VERSION ""
BS_:
BU_:

BO_ 795 BCS2L_warningMatrix2: 8 ETH
 SG_ BCS2L_w065_latchMotorLSD: 0|1@1+ (1,0) [0|0] "" X
 SG_ BCS2L_w066_latchMotorOverCurr: 1|1@1+ (1,0) [0|0] "" X
 SG_ BCS2L_w067_latchMotorUnderCurr: 2|1@1+ (1,0) [0|0] "" X
 SG_ BCS2L_w068_latchMicroswitchError: 3|1@1+ (1,0) [0|0] "" X
 SG_ BCS2L_w070_2ROccupiedUnbuckled: 5|1@1+ (1,0) [0|0] "" X
 SG_ BCS2L_w071_3ROccupiedUnbuckled: 6|1@1+ (1,0) [0|0] "" X
 SG_ BCS2L_w072_2RObstacleDetected: 7|1@1+ (1,0) [0|0] "" X
 SG_ BCS2L_w073_occupiedUnsecured: 8|1@1+ (1,0) [0|0] "" X
 SG_ BCS2L_w074_2RowTrackObstacle: 9|1@1+ (1,0) [0|0] "" X
 SG_ BCS2L_w075_2RowPitchObstacle: 10|1@1+ (1,0) [0|0] "" X
 SG_ BCS2L_w076_unexpectedStop: 11|1@1+ (1,0) [0|0] "" X
 SG_ BCS2L_w077_jammedSeat: 12|1@1+ (1,0) [0|0] "" X
 SG_ BCS2L_w079_DvrSideCfgMismatch: 14|1@1+ (1,0) [0|0] "" X
 SG_ BCS2L_w081_trackUncalibrated: 16|1@1+ (1,0) [0|0] "" X
 SG_ BCS2L_w082_pitchUncalibrated: 17|1@1+ (1,0) [0|0] "" X
 SG_ BCS2L_w085_comfortSwitchMisuse: 20|1@1+ (1,0) [0|0] "" X
 SG_ BCS2L_w086_easyEntrySwitchMisuse: 21|1@1+ (1,0) [0|0] "" X
 SG_ BCS2L_w087_foldFlatSwitchMisuse: 22|1@1+ (1,0) [0|0] "" X
 SG_ BCS2L_w090_CrashUnlockError: 25|1@1+ (1,0) [0|0] "" X
 SG_ BCS2L_w091_CrashStateMismatch: 26|1@1+ (1,0) [0|0] "" X
 SG_ BCS2L_w093_OTPError: 28|1@1+ (1,0) [0|0] "" X
 SG_ BCS2L_w094_FreescaleHSDFault: 29|1@1+ (1,0) [0|0] "" X
 SG_ BCS2L_w095_SeatUncalibrated1Row: 30|1@1+ (1,0) [0|0] "" X
 SG_ BCS2L_w096_HeadUncalibrated1Row: 31|1@1+ (1,0) [0|0] "" X
 SG_ BCS2L_w097_6040SeatUnlatched: 32|1@1+ (1,0) [0|0] "" X
 SG_ BCS2L_w098_6040TrackUndercurrent: 33|1@1+ (1,0) [0|0] "" X
 SG_ BCS2L_w100_chargePumpFail: 35|1@1+ (1,0) [0|0] "" X
 SG_ BCS2L_w101_VBATOutOfRange: 36|1@1+ (1,0) [0|0] "" X
 SG_ BCS2L_w102_8vRegulatorOutOfRange: 37|1@1+ (1,0) [0|0] "" X
 SG_ BCS2L_w103_regulatorShortedToGND: 38|1@1+ (1,0) [0|0] "" X
 SG_ BCS2L_w104_ECUOverCurrent: 39|1@1+ (1,0) [0|0] "" X
 SG_ BCS2L_w105_ECUDebugMode: 40|1@1+ (1,0) [0|0] "" X
 SG_ BCS2L_w106_HighCPULoad: 41|1@1+ (1,0) [0|0] "" X
 SG_ BCS2L_w107_HighStackUsage: 42|1@1+ (1,0) [0|0] "" X
 SG_ BCS2L_w108_2RHeatrTmpSnsInvalid: 43|1@1+ (1,0) [0|0] "" X
 SG_ BCS2L_w109_3RHeatrTmpSnsInvalid: 44|1@1+ (1,0) [0|0] "" X
 SG_ BCS2L_w110_2RSeatHeatSlowRise: 45|1@1+ (1,0) [0|0] "" X
 SG_ BCS2L_w111_3RLSeatHeatFault: 46|1@1+ (1,0) [0|0] "" X
 SG_ BCS2L_w112_3RSeatHeatSlowRise: 47|1@1+ (1,0) [0|0] "" X
 SG_ BCS2L_w114_seatHeatFault: 49|1@1+ (1,0) [0|0] "" X
 SG_ BCS2L_w115_2RHeatPadTempSensFLT: 50|1@1+ (1,0) [0|0] "" X
 SG_ BCS2L_w116_3RHeatPadTempSensFLT: 51|1@1+ (1,0) [0|0] "" X
 SG_ BCS2L_w117_2RHeatPadOvercurrent: 52|1@1+ (1,0) [0|0] "" X
 SG_ BCS2L_w118_3RHeatPadOvercurrent: 53|1@1+ (1,0) [0|0] "" X
 SG_ BCS2L_w119_2RCHeatPadOvercurrent: 54|1@1+ (1,0) [0|0] "" X
 SG_ BCS2L_w120_trackMotorDisconnect: 55|1@1+ (1,0) [0|0] "" X
 SG_ BCS2L_w121_pitchMotorDisconnect: 56|1@1+ (1,0) [0|0] "" X
 SG_ BCS2L_w122_trackSensorDisconnect: 57|1@1+ (1,0) [0|0] "" X
 SG_ BCS2L_w123_pitchSensorDisconnect: 58|1@1+ (1,0) [0|0] "" X
 SG_ BCS2L_w124_3RFFMotorDisconnect: 59|1@1+ (1,0) [0|0] "" X
 SG_ BCS2L_w125_3RHeadMotorDisconnect: 60|1@1+ (1,0) [0|0] "" X
 SG_ BCS2L_w126_comfortHoldDown: 61|1@1+ (1,0) [0|0] "" X
 SG_ BCS2L_w127_easyEntryHoldDown: 62|1@1+ (1,0) [0|0] "" X
 SG_ BCS2L_w128_foldFlatHoldDown: 63|1@1+ (1,0) [0|0] "" X

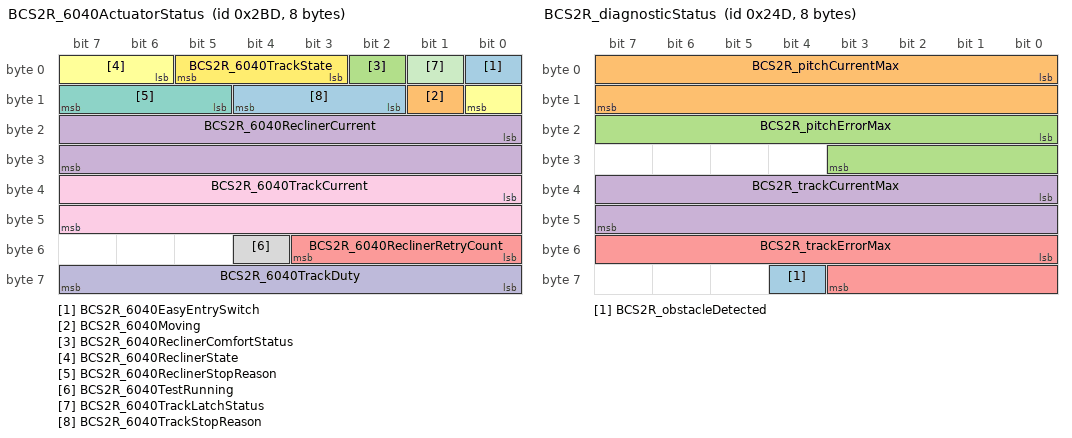
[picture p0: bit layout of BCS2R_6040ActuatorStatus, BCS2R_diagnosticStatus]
BO_ 701 BCS2R_6040ActuatorStatus: 8 ETH
 SG_ BCS2R_6040EasyEntrySwitch: 0|1@1+ (1,0) [0|0] "" X
 SG_ BCS2R_6040Moving: 9|1@1+ (1,0) [0|0] "" X
 SG_ BCS2R_6040ReclinerComfortStatus: 2|1@1+ (1,0) [0|0] "" X
 SG_ BCS2R_6040ReclinerCurrent: 16|16@1- (0.0030518,0) [0|0] "A" X
 SG_ BCS2R_6040ReclinerRetryCount: 48|4@1+ (1,0) [0|0] "" X
 SG_ BCS2R_6040ReclinerState: 6|3@1+ (1,0) [0|0] "" X
 SG_ BCS2R_6040ReclinerStopReason: 13|3@1+ (1,0) [0|0] "" X
 SG_ BCS2R_6040TestRunning: 52|1@1+ (1,0) [0|0] "" X
 SG_ BCS2R_6040TrackCurrent: 32|16@1- (0.0030518,0) [0|0] "A" X
 SG_ BCS2R_6040TrackDuty: 56|8@1- (1,0) [0|0] "%" X
 SG_ BCS2R_6040TrackLatchStatus: 1|1@1+ (1,0) [0|0] "" X
 SG_ BCS2R_6040TrackState: 3|3@1+ (1,0) [0|0] "" X
 SG_ BCS2R_6040TrackStopReason: 10|3@1+ (1,0) [0|0] "" X

BO_ 589 BCS2R_diagnosticStatus: 8 ETH
 SG_ BCS2R_obstacleDetected: 60|1@1+ (1,0) [0|0] "" X
 SG_ BCS2R_pitchCurrentMax: 0|16@1- (0.0030518,0) [0|0] "A" X
 SG_ BCS2R_pitchErrorMax: 16|12@1- (0.04884,0) [0|0] "%" X
 SG_ BCS2R_trackCurrentMax: 32|16@1- (0.0030518,0) [0|0] "A" X
 SG_ BCS2R_trackErrorMax: 48|12@1- (0.04884,0) [0|0] "%" X

BO_ 1309 BCS2R_info: 8 ETH
 SG_ BCS2R_infoIndex M: 0|8@1+ (1,0) [0|0] "" X
 SG_ BCS2R_infoBuildType m10: 8|8@1+ (1,0) [0|0] "" X
 SG_ BCS2R_infoBuildConfigID m10: 16|16@1+ (1,0) [0|0] "" X
 SG_ BCS2R_infoHardwareID m10: 32|16@1+ (1,0) [0|0] "" X
 SG_ BCS2R_infoComponentID m10: 48|16@1+ (1,0) [0|0] "" X
 SG_ BCS2R_infoPcbaID m11: 16|8@1+ (1,0) [0|0] "" X
 SG_ BCS2R_infoAssemblyID m11: 24|8@1+ (1,0) [0|0] "INTEGRAL" X
 SG_ BCS2R_infoUsageID m11: 32|16@1+ (1,0) [0|0] "" X
 SG_ BCS2R_infoSubUsageID m11: 48|16@1+ (1,0) [0|0] "" X
 SG_ BCS2R_infoApplicationCRC m13: 32|32@1+ (1,0) [0|0] "" X
 SG_ BCS2R_infoBootSvnRev m14: 8|24@1+ (1,0) [0|0] "" X
 SG_ BCS2R_infoAppGitHashBytes m17: 10|54@1+ (4,0) [0|0] "" X
 SG_ BCS2R_infoBootGitHashBytes m18: 10|54@1+ (4,0) [0|0] "" X
 SG_ BCS2R_infoPlatformType m19: 8|8@1+ (1,0) [0|0] "" X
 SG_ BCS2R_infoBootUdsProtoVersion m20: 8|8@1+ (1,0) [0|0] "" X
 SG_ BCS2R_infoBootloaderCRC m20: 32|32@1+ (1,0) [0|0] "" X

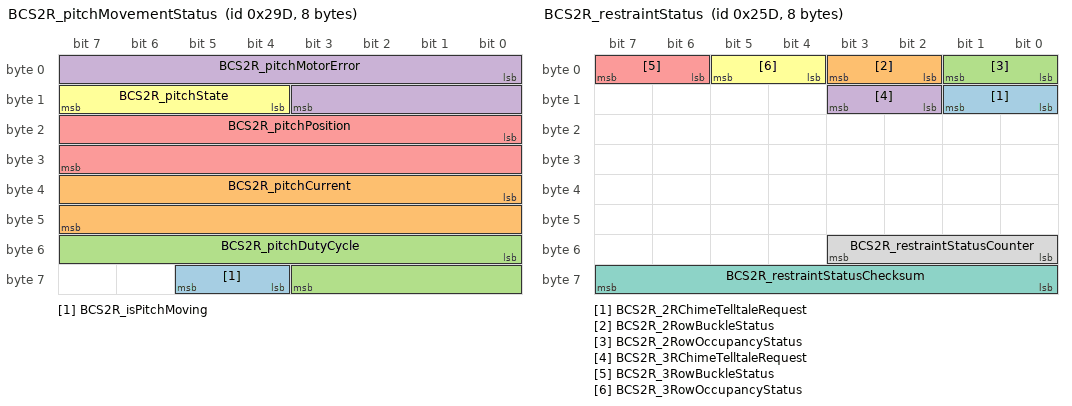
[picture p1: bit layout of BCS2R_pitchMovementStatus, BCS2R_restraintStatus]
BO_ 669 BCS2R_pitchMovementStatus: 8 ETH
 SG_ BCS2R_isPitchMoving: 60|2@1+ (1,0) [0|0] "" X
 SG_ BCS2R_pitchCurrent: 32|16@1- (0.0030518,0) [0|0] "A" X
 SG_ BCS2R_pitchDutyCycle: 48|12@1- (0.04884,0) [0|0] "%" X
 SG_ BCS2R_pitchMotorError: 0|12@1- (0.04884,0) [0|0] "%" X
 SG_ BCS2R_pitchPosition: 16|16@1- (1,0) [0|0] "INTEGRAL" X
 SG_ BCS2R_pitchState: 12|4@1+ (1,0) [0|0] "" X

BO_ 605 BCS2R_restraintStatus: 8 ETH
 SG_ BCS2R_2RChimeTelltaleRequest: 8|2@1+ (1,0) [0|0] "" X
 SG_ BCS2R_2RowBuckleStatus: 2|2@1+ (1,0) [0|0] "" X
 SG_ BCS2R_2RowOccupancyStatus: 0|2@1+ (1,0) [0|0] "" X
 SG_ BCS2R_3RChimeTelltaleRequest: 10|2@1+ (1,0) [0|0] "" X
 SG_ BCS2R_3RowBuckleStatus: 6|2@1+ (1,0) [0|0] "" X
 SG_ BCS2R_3RowOccupancyStatus: 4|2@1+ (1,0) [0|0] "" X
 SG_ BCS2R_restraintStatusChecksum: 56|8@1+ (1,0) [0|0] "" X
 SG_ BCS2R_restraintStatusCounter: 48|4@1+ (1,0) [0|0] "" X

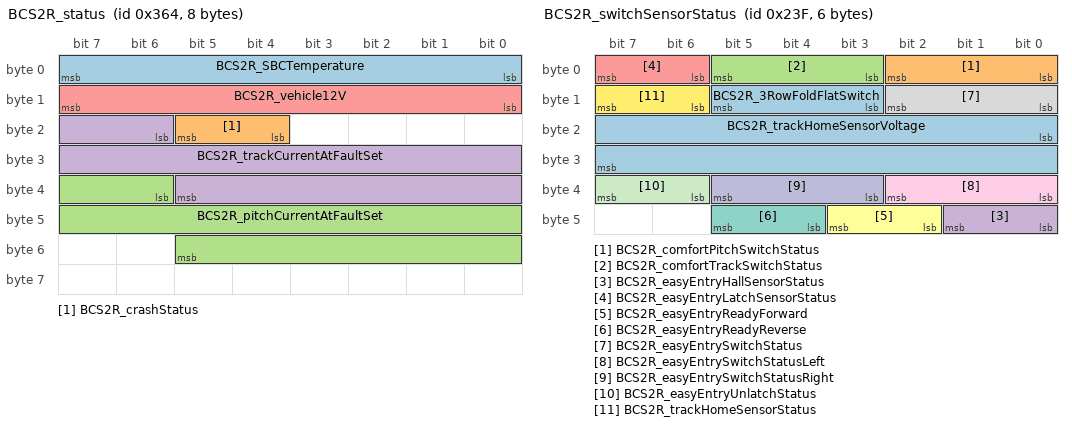
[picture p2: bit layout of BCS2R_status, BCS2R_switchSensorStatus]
BO_ 868 BCS2R_status: 8 ETH
 SG_ BCS2R_SBCTemperature: 0|8@1- (1,0) [0|0] "C" X
 SG_ BCS2R_crashStatus: 20|2@1+ (1,0) [0|0] "" X
 SG_ BCS2R_pitchCurrentAtFaultSet: 38|16@1- (0.0030518,0) [0|0] "A" X
 SG_ BCS2R_trackCurrentAtFaultSet: 22|16@1- (0.0030518,0) [0|0] "A" X
 SG_ BCS2R_vehicle12V: 8|8@1+ (0.1,0) [0|0] "V" X

BO_ 575 BCS2R_switchSensorStatus: 6 ETH
 SG_ BCS2R_3RowFoldFlatSwitch: 11|3@1+ (1,0) [0|0] "" X
 SG_ BCS2R_comfortPitchSwitchStatus: 0|3@1+ (1,0) [0|0] "" X
 SG_ BCS2R_comfortTrackSwitchStatus: 3|3@1+ (1,0) [0|0] "" X
 SG_ BCS2R_easyEntryHallSensorStatus: 40|2@1+ (1,0) [0|0] "" X
 SG_ BCS2R_easyEntryLatchSensorStatus: 6|2@1+ (1,0) [0|0] "" X
 SG_ BCS2R_easyEntryReadyForward: 42|2@1+ (1,0) [0|0] "" X
 SG_ BCS2R_easyEntryReadyReverse: 44|2@1+ (1,0) [0|0] "" X
 SG_ BCS2R_easyEntrySwitchStatus: 8|3@1+ (1,0) [0|0] "" X
 SG_ BCS2R_easyEntrySwitchStatusLeft: 32|3@1+ (1,0) [0|0] "" X
 SG_ BCS2R_easyEntrySwitchStatusRight: 35|3@1+ (1,0) [0|0] "" X
 SG_ BCS2R_easyEntryUnlatchStatus: 38|2@1+ (1,0) [0|0] "" X
 SG_ BCS2R_trackHomeSensorStatus: 14|2@1+ (1,0) [0|0] "" X
 SG_ BCS2R_trackHomeSensorVoltage: 16|16@1- (0.00015259,0) [0|0] "V" X

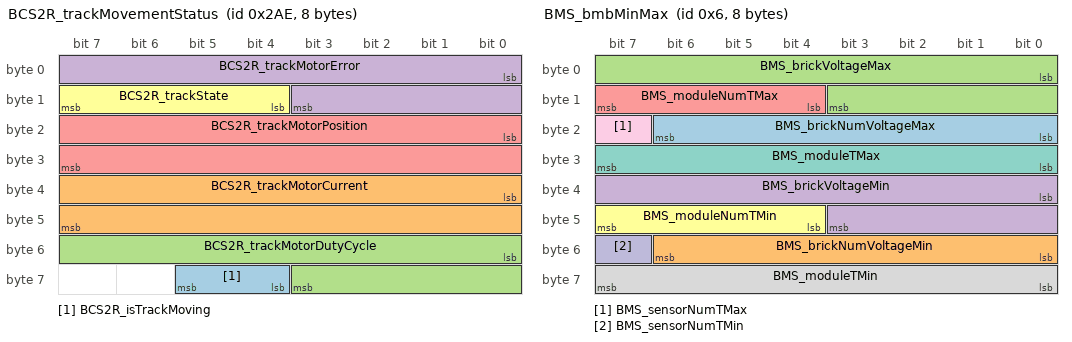
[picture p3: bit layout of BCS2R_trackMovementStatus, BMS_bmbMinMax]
BO_ 686 BCS2R_trackMovementStatus: 8 ETH
 SG_ BCS2R_isTrackMoving: 60|2@1+ (1,0) [0|0] "" X
 SG_ BCS2R_trackMotorCurrent: 32|16@1- (0.0030518,0) [0|0] "A" X
 SG_ BCS2R_trackMotorDutyCycle: 48|12@1- (0.04884,0) [0|0] "%" X
 SG_ BCS2R_trackMotorError: 0|12@1- (0.04884,0) [0|0] "%" X
 SG_ BCS2R_trackMotorPosition: 16|16@1- (1,0) [0|0] "INTEGRAL" X
 SG_ BCS2R_trackState: 12|4@1+ (1,0) [0|0] "" X

BO_ 1725 BCS2R_udsResponse: 8 ETH
 SG_ BCS2R_udsResponseData_H: 0|32@0+ (1,0) [0|0] "" X
 SG_ BCS2R_udsResponseData_L: 32|32@0+ (1,0) [0|0] "" X

BO_ 781 BCS2R_warningMatrix1: 8 ETH
 SG_ BCS2R_w001_WatchdogReset: 0|1@1+ (1,0) [0|0] "" X
 SG_ BCS2R_w002_PowerLossReset: 1|1@1+ (1,0) [0|0] "" X
 SG_ BCS2R_w003_SWAssertion: 2|1@1+ (1,0) [0|0] "" X
 SG_ BCS2R_w004_CANMIA: 3|1@1+ (1,0) [0|0] "" X
 SG_ BCS2R_w005_CANHighError: 4|1@1+ (1,0) [0|0] "" X
 SG_ BCS2R_w006_CANLowError: 5|1@1+ (1,0) [0|0] "" X
 SG_ BCS2R_w007_LINTimeout: 6|1@1+ (1,0) [0|0] "" X
 SG_ BCS2R_w008_LIN2Error: 7|1@1+ (1,0) [0|0] "" X
 SG_ BCS2R_w009_LIN3Error: 8|1@1+ (1,0) [0|0] "" X
 SG_ BCS2R_w010_ExtSupplyVoltError: 9|1@1+ (1,0) [0|0] "" X
 SG_ BCS2R_w011_ECUSupplyVoltError: 10|1@1+ (1,0) [0|0] "" X
 SG_ BCS2R_w012_CPUReset: 11|1@1+ (1,0) [0|0] "" X
 SG_ BCS2R_w013_Shared13: 12|1@1+ (1,0) [0|0] "" X
 SG_ BCS2R_w014_BridgeFault: 13|1@1+ (1,0) [0|0] "" X
 SG_ BCS2R_w015_NVMMAlert: 14|1@1+ (1,0) [0|0] "" X
 SG_ BCS2R_w016_MessageTimingError: 15|1@1+ (1,0) [0|0] "" X
 SG_ BCS2R_w017_AwakeForTooLong: 16|1@1+ (1,0) [0|0] "" X
 SG_ BCS2R_w018_ADCError: 17|1@1+ (1,0) [0|0] "" X
 SG_ BCS2R_w019_I2CError: 18|1@1+ (1,0) [0|0] "" X
 SG_ BCS2R_w020_PWMError: 19|1@1+ (1,0) [0|0] "" X
 SG_ BCS2R_w021_TaskSchedulerError: 20|1@1+ (1,0) [0|0] "" X
 SG_ BCS2R_w022_TaskInitError: 21|1@1+ (1,0) [0|0] "" X
 SG_ BCS2R_w023_SleepError: 22|1@1+ (1,0) [0|0] "" X
 SG_ BCS2R_w024_WakeError: 23|1@1+ (1,0) [0|0] "" X
 SG_ BCS2R_w025_CrashEvent: 24|1@1+ (1,0) [0|0] "" X
 SG_ BCS2R_w026_FlashMemoryError: 25|1@1+ (1,0) [0|0] "" X
 SG_ BCS2R_w027_NVRAMCorruption: 26|1@1+ (1,0) [0|0] "" X
 SG_ BCS2R_w028_NVRAMNotResponding: 27|1@1+ (1,0) [0|0] "" X
 SG_ BCS2R_w029_NVRAMUninitialized: 28|1@1+ (1,0) [0|0] "" X
 SG_ BCS2R_w030_SeatConfigError: 29|1@1+ (1,0) [0|0] "" X
 SG_ BCS2R_w040_trackMotorShort: 39|1@1+ (1,0) [0|0] "" X
 SG_ BCS2R_w041_trackMotorLowCurrent: 40|1@1+ (1,0) [0|0] "" X
 SG_ BCS2R_w042_trackMotorLogicTempUV: 41|1@1+ (1,0) [0|0] "" X
 SG_ BCS2R_w043_trackMotorOverCurr: 42|1@1+ (1,0) [0|0] "" X
 SG_ BCS2R_w044_trackMotorEncodeError: 43|1@1+ (1,0) [0|0] "" X
 SG_ BCS2R_w045_trackMotorUnderCurr: 44|1@1+ (1,0) [0|0] "" X
 SG_ BCS2R_w046_2RBuckleFaultSNA: 45|1@1+ (1,0) [0|0] "" X
 SG_ BCS2R_w047_2ROccupancyFaultSNA: 46|1@1+ (1,0) [0|0] "" X
 SG_ BCS2R_w048_3RBuckleFaultSNA: 47|1@1+ (1,0) [0|0] "" X
 SG_ BCS2R_w049_3ROccupancyFaultSNA: 48|1@1+ (1,0) [0|0] "" X
 SG_ BCS2R_w050_pitchMotorOverCurr: 49|1@1+ (1,0) [0|0] "" X
 SG_ BCS2R_w051_pitchMotorUnderCurr: 50|1@1+ (1,0) [0|0] "" X
 SG_ BCS2R_w052_pitchMotorEncodeError: 51|1@1+ (1,0) [0|0] "" X
 SG_ BCS2R_w053_2RCHeatrTmpSnsInvalid: 52|1@1+ (1,0) [0|0] "" X
 SG_ BCS2R_w054_2RCSeatHeatSlowRise: 53|1@1+ (1,0) [0|0] "" X
 SG_ BCS2R_w056_2RCHeatPadTempSensFLT: 55|1@1+ (1,0) [0|0] "" X
 SG_ BCS2R_w057_2RCBuckleFaultSNA: 56|1@1+ (1,0) [0|0] "" X
 SG_ BCS2R_w058_2RCOccupancyFaultSNA: 57|1@1+ (1,0) [0|0] "" X
 SG_ BCS2R_w060_3RFoldOverCurr: 59|1@1+ (1,0) [0|0] "" X
 SG_ BCS2R_w061_3RHeadrestUnderCurr: 60|1@1+ (1,0) [0|0] "" X
 SG_ BCS2R_w062_3RHeadrestOverCurr: 61|1@1+ (1,0) [0|0] "" X
 SG_ BCS2R_w063_sharedMotorLSD: 62|1@1+ (1,0) [0|0] "" X
 SG_ BCS2R_w064_3RFoldMotorLSD: 63|1@1+ (1,0) [0|0] "" X

BO_ 797 BCS2R_warningMatrix2: 8 ETH
 SG_ BCS2R_w065_latchMotorLSD: 0|1@1+ (1,0) [0|0] "" X
 SG_ BCS2R_w066_latchMotorOverCurr: 1|1@1+ (1,0) [0|0] "" X
 SG_ BCS2R_w067_latchMotorUnderCurr: 2|1@1+ (1,0) [0|0] "" X
 SG_ BCS2R_w068_latchMicroswitchError: 3|1@1+ (1,0) [0|0] "" X
 SG_ BCS2R_w070_2ROccupiedUnbuckled: 5|1@1+ (1,0) [0|0] "" X
 SG_ BCS2R_w071_3ROccupiedUnbuckled: 6|1@1+ (1,0) [0|0] "" X
 SG_ BCS2R_w072_2RObstacleDetected: 7|1@1+ (1,0) [0|0] "" X
 SG_ BCS2R_w073_occupiedUnsecured: 8|1@1+ (1,0) [0|0] "" X
 SG_ BCS2R_w074_2RowTrackObstacle: 9|1@1+ (1,0) [0|0] "" X
 SG_ BCS2R_w075_2RowPitchObstacle: 10|1@1+ (1,0) [0|0] "" X
 SG_ BCS2R_w076_unexpectedStop: 11|1@1+ (1,0) [0|0] "" X
 SG_ BCS2R_w077_jammedSeat: 12|1@1+ (1,0) [0|0] "" X
 SG_ BCS2R_w079_DvrSideCfgMismatch: 14|1@1+ (1,0) [0|0] "" X
 SG_ BCS2R_w081_trackUncalibrated: 16|1@1+ (1,0) [0|0] "" X
 SG_ BCS2R_w082_pitchUncalibrated: 17|1@1+ (1,0) [0|0] "" X
 SG_ BCS2R_w085_comfortSwitchMisuse: 20|1@1+ (1,0) [0|0] "" X
 SG_ BCS2R_w086_easyEntrySwitchMisuse: 21|1@1+ (1,0) [0|0] "" X
 SG_ BCS2R_w087_foldFlatSwitchMisuse: 22|1@1+ (1,0) [0|0] "" X
 SG_ BCS2R_w090_CrashUnlockError: 25|1@1+ (1,0) [0|0] "" X
 SG_ BCS2R_w091_CrashStateMismatch: 26|1@1+ (1,0) [0|0] "" X
 SG_ BCS2R_w093_OTPError: 28|1@1+ (1,0) [0|0] "" X
 SG_ BCS2R_w094_FreescaleHSDFault: 29|1@1+ (1,0) [0|0] "" X
 SG_ BCS2R_w095_SeatUncalibrated1Row: 30|1@1+ (1,0) [0|0] "" X
 SG_ BCS2R_w096_HeadUncalibrated1Row: 31|1@1+ (1,0) [0|0] "" X
 SG_ BCS2R_w097_6040SeatUnlatched: 32|1@1+ (1,0) [0|0] "" X
 SG_ BCS2R_w098_6040TrackUndercurrent: 33|1@1+ (1,0) [0|0] "" X
 SG_ BCS2R_w100_chargePumpFail: 35|1@1+ (1,0) [0|0] "" X
 SG_ BCS2R_w101_VBATOutOfRange: 36|1@1+ (1,0) [0|0] "" X
 SG_ BCS2R_w102_8vRegulatorOutOfRange: 37|1@1+ (1,0) [0|0] "" X
 SG_ BCS2R_w103_regulatorShortedToGND: 38|1@1+ (1,0) [0|0] "" X
 SG_ BCS2R_w104_ECUOverCurrent: 39|1@1+ (1,0) [0|0] "" X
 SG_ BCS2R_w105_ECUDebugMode: 40|1@1+ (1,0) [0|0] "" X
 SG_ BCS2R_w106_HighCPULoad: 41|1@1+ (1,0) [0|0] "" X
 SG_ BCS2R_w107_HighStackUsage: 42|1@1+ (1,0) [0|0] "" X
 SG_ BCS2R_w108_2RHeatrTmpSnsInvalid: 43|1@1+ (1,0) [0|0] "" X
 SG_ BCS2R_w109_3RHeatrTmpSnsInvalid: 44|1@1+ (1,0) [0|0] "" X
 SG_ BCS2R_w110_2RSeatHeatSlowRise: 45|1@1+ (1,0) [0|0] "" X
 SG_ BCS2R_w111_3RLSeatHeatFault: 46|1@1+ (1,0) [0|0] "" X
 SG_ BCS2R_w112_3RSeatHeatSlowRise: 47|1@1+ (1,0) [0|0] "" X
 SG_ BCS2R_w114_seatHeatFault: 49|1@1+ (1,0) [0|0] "" X
 SG_ BCS2R_w115_2RHeatPadTempSensFLT: 50|1@1+ (1,0) [0|0] "" X
 SG_ BCS2R_w116_3RHeatPadTempSensFLT: 51|1@1+ (1,0) [0|0] "" X
 SG_ BCS2R_w117_2RHeatPadOvercurrent: 52|1@1+ (1,0) [0|0] "" X
 SG_ BCS2R_w118_3RHeatPadOvercurrent: 53|1@1+ (1,0) [0|0] "" X
 SG_ BCS2R_w119_2RCHeatPadOvercurrent: 54|1@1+ (1,0) [0|0] "" X
 SG_ BCS2R_w120_trackMotorDisconnect: 55|1@1+ (1,0) [0|0] "" X
 SG_ BCS2R_w121_pitchMotorDisconnect: 56|1@1+ (1,0) [0|0] "" X
 SG_ BCS2R_w122_trackSensorDisconnect: 57|1@1+ (1,0) [0|0] "" X
 SG_ BCS2R_w123_pitchSensorDisconnect: 58|1@1+ (1,0) [0|0] "" X
 SG_ BCS2R_w124_3RFFMotorDisconnect: 59|1@1+ (1,0) [0|0] "" X
 SG_ BCS2R_w125_3RHeadMotorDisconnect: 60|1@1+ (1,0) [0|0] "" X
 SG_ BCS2R_w126_comfortHoldDown: 61|1@1+ (1,0) [0|0] "" X
 SG_ BCS2R_w127_easyEntryHoldDown: 62|1@1+ (1,0) [0|0] "" X
 SG_ BCS2R_w128_foldFlatHoldDown: 63|1@1+ (1,0) [0|0] "" X

BO_ 1684 BC_udsResponse: 8 ETH
 SG_ BC_udsResponseData: 0|54@0+ (1024,0) [0|0] "" X

BO_ 1300 BC_version: 8 ETH
 SG_ BC_componentBranchOrigin: 40|8@1+ (1,0) [0|0] "" X
 SG_ BC_componentHardwareRevision: 56|8@1+ (1,0) [0|0] "" X
 SG_ BC_componentMajorVersion: 32|8@1+ (1,0) [0|0] "" X
 SG_ BC_componentMaturity: 48|8@1+ (1,0) [0|0] "" X
 SG_ BC_componentSvn: 8|24@0+ (1,0) [0|0] "" X
 SG_ BC_platformType: 0|8@1+ (1,0) [0|0] "" X

BO_ 1448 BC_warningMatrix1: 8 ETH
 SG_ BC_w001_leftIndicatorFail: 0|1@1+ (1,0) [0|0] "" X
 SG_ BC_w002_rightIndicatorFail: 1|1@1+ (1,0) [0|0] "" X

BO_ 32 BMS_alertMatrix1: 8 ETH
 SG_ BMS_f001_HW_Over_Current: 0|1@1+ (1,0) [0|0] "" X
 SG_ BMS_f002_HW_Over_Voltage: 1|1@1+ (1,0) [0|0] "" X
 SG_ BMS_f003_HW_Module_Alarm: 2|1@1+ (1,0) [0|0] "" X
 SG_ BMS_f004_Unused_4: 3|1@1+ (1,0) [0|0] "" X
 SG_ BMS_f005_Unused_5: 4|1@1+ (1,0) [0|0] "" X
 SG_ BMS_f006_HW_Ctr_Sfty_Override: 5|1@1+ (1,0) [0|0] "" X
 SG_ BMS_f007_SW_Module_Alarm_Broken: 6|1@1+ (1,0) [0|0] "" X
 SG_ BMS_f008_HW_HVIL: 7|1@1+ (1,0) [0|0] "" X
 SG_ BMS_f009_SW_Pos_Contactor_Drive: 8|1@1+ (1,0) [0|0] "" X
 SG_ BMS_f010_SW_Neg_Contactor_Drive: 9|1@1+ (1,0) [0|0] "" X
 SG_ BMS_f011_HW_Illegal_Ctr_Req: 10|1@1+ (1,0) [0|0] "" X
 SG_ BMS_f012_HW_Pump_Drive_Fault: 11|1@1+ (1,0) [0|0] "" X
 SG_ BMS_f013_HW_Liquid_Detected: 12|1@1+ (1,0) [0|0] "" X
 SG_ BMS_f014_HW_Heater_Drive: 13|1@1+ (1,0) [0|0] "" X
 SG_ BMS_f015_HW_Sleep_Attempt: 14|1@1+ (1,0) [0|0] "" X
 SG_ BMS_f016_SW_Thermal_Gradient: 15|1@1+ (1,0) [0|0] "" X
 SG_ BMS_f017_SW_Brick_OV: 16|1@1+ (1,0) [0|0] "" X
 SG_ BMS_f018_SW_Brick_UV: 17|1@1+ (1,0) [0|0] "" X
 SG_ BMS_f019_SW_BMB_Module_OT: 18|1@1+ (1,0) [0|0] "" X
 SG_ BMS_f020_SW_BMB_PCB_OT: 19|1@1+ (1,0) [0|0] "" X
 SG_ BMS_f021_SW_Dr_Limits_Regulation: 20|1@1+ (1,0) [0|0] "" X
 SG_ BMS_f022_SW_Over_Current: 21|1@1+ (1,0) [0|0] "" X
 SG_ BMS_f023_SW_Contactors_Open_HWOC: 22|1@1+ (1,0) [0|0] "" X
 SG_ BMS_f024_SW_Ctrs_Open_Under_Load: 23|1@1+ (1,0) [0|0] "" X
 SG_ BMS_f025_SW_FC_Ctrs_Open_Undr_Ld: 24|1@1+ (1,0) [0|0] "" X
 SG_ BMS_f026_SW_Ctrs_Disabled: 25|1@1+ (1,0) [0|0] "" X
 SG_ BMS_f027_Unused_27: 26|1@1+ (1,0) [0|0] "" X
 SG_ BMS_f028_Unused_28: 27|1@1+ (1,0) [0|0] "" X
 SG_ BMS_f029_SW_Current_Sensor_Reset: 28|1@1+ (1,0) [0|0] "" X
 SG_ BMS_f030_SW_Chg_Port_Door_Open: 29|1@1+ (1,0) [0|0] "" X
 SG_ BMS_f031_SW_Precharge_Res_Hot: 30|1@1+ (1,0) [0|0] "" X
 SG_ BMS_f032_SW_BusVNotReducing: 31|1@1+ (1,0) [0|0] "" X
 SG_ BMS_f033_SW_Crash: 32|1@1+ (1,0) [0|0] "" X
 SG_ BMS_f034_SW_Isolation_Sensor: 33|1@1+ (1,0) [0|0] "" X
 SG_ BMS_f035_SW_Isolation: 34|1@1+ (1,0) [0|0] "" X
 SG_ BMS_f036_SW_HVIL: 35|1@1+ (1,0) [0|0] "" X
 SG_ BMS_f037_SW_Pos_Contactor: 36|1@1+ (1,0) [0|0] "" X
 SG_ BMS_f038_SW_Neg_Contactor: 37|1@1+ (1,0) [0|0] "" X
 SG_ BMS_f039_SW_DC_Link_Over_Voltage: 38|1@1+ (1,0) [0|0] "" X
 SG_ BMS_f040_SW_BMS_PCB_OT: 39|1@1+ (1,0) [0|0] "" X
 SG_ BMS_f041_SW_Liquid_Detected: 40|1@1+ (1,0) [0|0] "" X
 SG_ BMS_f042_SW_Humidity: 41|1@1+ (1,0) [0|0] "" X
 SG_ BMS_f043_SW_Watch_Dog_Reset: 42|1@1+ (1,0) [0|0] "" X
 SG_ BMS_f044_SW_Assertion: 43|1@1+ (1,0) [0|0] "" X
 SG_ BMS_f045_SW_Internal_CANB_error: 44|1@1+ (1,0) [0|0] "" X
 SG_ BMS_f046_SW_External_CANA_error: 45|1@1+ (1,0) [0|0] "" X
 SG_ BMS_f047_SW_Memory_Error: 46|1@1+ (1,0) [0|0] "" X
 SG_ BMS_f048_SW_SCC: 47|1@1+ (1,0) [0|0] "" X
 SG_ BMS_f049_SW_Thermal_Event: 48|1@1+ (1,0) [0|0] "" X
 SG_ BMS_f050_SW_BMB_MIA: 49|1@1+ (1,0) [0|0] "" X
 SG_ BMS_f051_SW_Current_Sensor_MIA: 50|1@1+ (1,0) [0|0] "" X
 SG_ BMS_f052_SW_Charger_MIA: 51|1@1+ (1,0) [0|0] "" X
 SG_ BMS_f053_SW_EVCM_MIA: 52|1@1+ (1,0) [0|0] "" X
 SG_ BMS_f054_SW_Current_Sensor: 53|1@1+ (1,0) [0|0] "" X
 SG_ BMS_f055_SW_Pump: 54|1@1+ (1,0) [0|0] "" X
 SG_ BMS_f056_SW_Module_Temp_Outlier: 55|1@1+ (1,0) [0|0] "" X
 SG_ BMS_f057_SW_Chiller: 56|1@1+ (1,0) [0|0] "" X
 SG_ BMS_f058_SW_Heater_Performance: 57|1@1+ (1,0) [0|0] "" X
 SG_ BMS_f059_SW_Pack_Voltage_Sensing: 58|1@1+ (1,0) [0|0] "" X
 SG_ BMS_f060_SW_BMB_Power_Supply: 59|1@1+ (1,0) [0|0] "" X
 SG_ BMS_f061_SW_BMS_Power_Supply: 60|1@1+ (1,0) [0|0] "" X
 SG_ BMS_f062_SW_Ctr_Pwr_Supply: 61|1@1+ (1,0) [0|0] "" X
 SG_ BMS_f063_SW_Precharge_Failure: 62|1@1+ (1,0) [0|0] "" X
 SG_ BMS_f064_SW_BrickV_Imbalance: 63|1@1+ (1,0) [0|0] "" X

BO_ 33 BMS_alertMatrix2: 8 ETH
 SG_ BMS_f065_SW_Brick_Low_Capacity: 0|1@1+ (1,0) [0|0] "" X
 SG_ BMS_f066_SW_High_Brick_Imp: 1|1@1+ (1,0) [0|0] "" X
 SG_ BMS_f067_SW_Low_Coolnt_Flow_Rate: 2|1@1+ (1,0) [0|0] "" X
 SG_ BMS_f068_SW_Low_SOC: 3|1@1+ (1,0) [0|0] "" X
 SG_ BMS_f069_SW_Low_Power: 4|1@1+ (1,0) [0|0] "" X
 SG_ BMS_f070_Unused_70: 5|1@1+ (1,0) [0|0] "" X
 SG_ BMS_f071_SW_SM_TransCon_Not_Met: 6|1@1+ (1,0) [0|0] "" X
 SG_ BMS_f072_SW_Unexpctd_Ctr_Bhvr: 7|1@1+ (1,0) [0|0] "" X
 SG_ BMS_f073_SW_Unexpctd_HV_Sys_Bhvr: 8|1@1+ (1,0) [0|0] "" X
 SG_ BMS_f074_SW_Charging: 9|1@1+ (1,0) [0|0] "" X
 SG_ BMS_f075_SW_Heater_Temp_Sensor: 10|1@1+ (1,0) [0|0] "" X
 SG_ BMS_f076_SW_Manifold_Temp_Sensor: 11|1@1+ (1,0) [0|0] "" X
 SG_ BMS_f077_SW_Charger_Regulation: 12|1@1+ (1,0) [0|0] "" X
 SG_ BMS_f078_SW_Heater_Over_Temp: 13|1@1+ (1,0) [0|0] "" X
 SG_ BMS_f079_SW_Ctr_Pwr_Interrupted: 14|1@1+ (1,0) [0|0] "" X
 SG_ BMS_f080_SW_Int_HV_Disconnect: 15|1@1+ (1,0) [0|0] "" X
 SG_ BMS_f081_SW_Liquid_Sensor_MIA: 16|1@1+ (1,0) [0|0] "" X
 SG_ BMS_f082_SW_BMS_MIA: 17|1@1+ (1,0) [0|0] "" X
 SG_ BMS_f083_SW_PacMan: 18|1@1+ (1,0) [0|0] "" X
 SG_ BMS_f084_SW_Pack_Imbalance: 19|1@1+ (1,0) [0|0] "" X
 SG_ BMS_f085_SW_Prechg_Too_Slow: 20|1@1+ (1,0) [0|0] "" X
 SG_ BMS_f086_SW_Not_Ok_To_Precharge: 21|1@1+ (1,0) [0|0] "" X
 SG_ BMS_f087_SW_Prechg_Too_Fast: 22|1@1+ (1,0) [0|0] "" X
 SG_ BMS_f088_SW_DTC: 23|1@1+ (1,0) [0|0] "" X
 SG_ BMS_f089_SW_THC_MIA: 24|1@1+ (1,0) [0|0] "" X
 SG_ BMS_f090_SW_GTW_Msg_Latency: 25|1@1+ (1,0) [0|0] "" X
 SG_ BMS_f091_RESERVED_W169_FC_SW_1: 26|1@1+ (1,0) [0|0] "" X
 SG_ BMS_f092_RESERVED_W169_FC_SW_2: 27|1@1+ (1,0) [0|0] "" X
 SG_ BMS_f093_SW_FastChg_Problem: 28|1@1+ (1,0) [0|0] "" X
 SG_ BMS_f094_SW_Drive_Inverter_MIA: 29|1@1+ (1,0) [0|0] "" X
 SG_ BMS_f095_SW_FastChg_Regulation: 30|1@1+ (1,0) [0|0] "" X
 SG_ BMS_f096_SW_Fast_Charger_MIA: 31|1@1+ (1,0) [0|0] "" X
 SG_ BMS_f097_HW_BMB_Under_Voltage: 32|1@1+ (1,0) [0|0] "" X
 SG_ BMS_f098_HW_BMB_Over_Voltage: 33|1@1+ (1,0) [0|0] "" X
 SG_ BMS_f099_SW_BMB_Communication: 34|1@1+ (1,0) [0|0] "" X
 SG_ BMS_f100_HW_BMB_Reset: 35|1@1+ (1,0) [0|0] "" X
 SG_ BMS_f101_HW_BMB_Over_Temperature: 36|1@1+ (1,0) [0|0] "" X
 SG_ BMS_f102_HW_BMB_Thermal_Shutdown: 37|1@1+ (1,0) [0|0] "" X
 SG_ BMS_f103_HW_BMB_Memory_Parity: 38|1@1+ (1,0) [0|0] "" X
 SG_ BMS_f104_HW_BMB_Enumeration: 39|1@1+ (1,0) [0|0] "" X
 SG_ BMS_f105_SW_One_Module_Tsense: 40|1@1+ (1,0) [0|0] "" X
 SG_ BMS_f106_SW_All_Module_Tsense: 41|1@1+ (1,0) [0|0] "" X
 SG_ BMS_f107_SW_Cell_Voltage_Sensor: 42|1@1+ (1,0) [0|0] "" X
 SG_ BMS_f108_HW_BMB_Alarm_Self_Test: 43|1@1+ (1,0) [0|0] "" X
 SG_ BMS_f109_SW_Bleed_Resistor: 44|1@1+ (1,0) [0|0] "" X
 SG_ BMS_f110_SW_Module_Vsense: 45|1@1+ (1,0) [0|0] "" X
 SG_ BMS_f111_SW_BMB_ADC_: 46|1@1+ (1,0) [0|0] "" X
 SG_ BMS_f112_SW_Pos_Contactor_ANC: 47|1@1+ (1,0) [0|0] "" X
 SG_ BMS_f113_SW_Neg_Contactor_ANC: 48|1@1+ (1,0) [0|0] "" X
 SG_ BMS_f114_SW_FC_Contactors: 49|1@1+ (1,0) [0|0] "" X
 SG_ BMS_f115_SW_Neg_Contactor_FC: 50|1@1+ (1,0) [0|0] "" X
 SG_ BMS_f116_SW_BusV_Not_Reducing_FC: 51|1@1+ (1,0) [0|0] "" X
 SG_ BMS_f117_SW_Wrong_Battery_Pack: 52|1@1+ (1,0) [0|0] "" X
 SG_ BMS_f118_SW_DC_Link_Voltage_ANC: 53|1@1+ (1,0) [0|0] "" X
 SG_ BMS_f119_SW_DC_Link_Voltage_FC: 54|1@1+ (1,0) [0|0] "" X
 SG_ BMS_f120_SW_Moisture_CtrlSys: 55|1@1+ (1,0) [0|0] "" X
 SG_ BMS_f121_SW_BMS_PCB_HumiditySens: 56|1@1+ (1,0) [0|0] "" X
 SG_ BMS_f122_SW_BMS_PCB_Temp_Sensor: 57|1@1+ (1,0) [0|0] "" X
 SG_ BMS_f123_SW_Internal_Isolation: 58|1@1+ (1,0) [0|0] "" X
 SG_ BMS_f124_SW_BMB_Comm_Integrity: 59|1@1+ (1,0) [0|0] "" X
 SG_ BMS_f125_SW_BMS_Ctr_Curr_Sensor: 60|1@1+ (1,0) [0|0] "" X
 SG_ BMS_f126_HW_BMS_Blind_Mate: 61|1@1+ (1,0) [0|0] "" X
 SG_ BMS_f127_SW_CPLD_CRC: 62|1@1+ (1,0) [0|0] "" X
 SG_ BMS_f128_SW_MIL_DTC_set: 63|1@1+ (1,0) [0|0] "" X

BO_ 34 BMS_alertMatrix3: 8 ETH
 SG_ BMS_f129_SW_BMB_VSH_Connector: 0|1@1+ (1,0) [0|0] "" X
 SG_ BMS_f130_SW_Module_Alrm_Redund: 1|1@1+ (1,0) [0|0] "" X
 SG_ BMS_f131_SW_PCB_Temp_Sensor_MIA: 2|1@1+ (1,0) [0|0] "" X
 SG_ BMS_f132_HW_BMB_OTP_Uncorrctbl: 3|1@1+ (1,0) [0|0] "" X
 SG_ BMS_f133_SW_Service_Tool: 4|1@1+ (1,0) [0|0] "" X
 SG_ BMS_f134_SW_Delayed_Ctr_Off: 5|1@1+ (1,0) [0|0] "" X
 SG_ BMS_f135_SW_Network_Management: 6|1@1+ (1,0) [0|0] "" X
 SG_ BMS_f136_SW_Module_OT_Warning: 7|1@1+ (1,0) [0|0] "" X
 SG_ BMS_f137_SW_Brick_UV_Warning: 8|1@1+ (1,0) [0|0] "" X
 SG_ BMS_f138_SW_Brick_OV_Warning: 9|1@1+ (1,0) [0|0] "" X
 SG_ BMS_f139_SW_DC_Link_V_Irrational: 10|1@1+ (1,0) [0|0] "" X
 SG_ BMS_f140_SW_OverCurrent_Sense: 11|1@1+ (1,0) [0|0] "" X
 SG_ BMS_f141_SW_12V_Pwr_Supply_Low: 12|1@1+ (1,0) [0|0] "" X
 SG_ BMS_f142_SW_Isolation_Degradatio: 13|1@1+ (1,0) [0|0] "" X
 SG_ BMS_f143_SW_BMB_OTP_Reg_Wrong: 14|1@1+ (1,0) [0|0] "" X
 SG_ BMS_f144_SW_CPLD_Version_Wrong: 15|1@1+ (1,0) [0|0] "" X
 SG_ BMS_f145_SW_socChange: 16|1@1+ (1,0) [0|0] "" X
 SG_ BMS_f146_SW_Brick_Overdischarged: 17|1@1+ (1,0) [0|0] "" X
 SG_ BMS_f147_SW_Safety: 18|1@1+ (1,0) [0|0] "" X
 SG_ BMS_f148_SW_unused_3: 19|1@1+ (1,0) [0|0] "" X
 SG_ BMS_f149_SW_precharge_too_short: 20|1@1+ (1,0) [0|0] "" X
 SG_ BMS_f150_SW_precharge_too_long: 21|1@1+ (1,0) [0|0] "" X
 SG_ BMS_f151_SW_external_isolation: 22|1@1+ (1,0) [0|0] "" X
 SG_ BMS_f152_SW_pos_contactor_welded: 23|1@1+ (1,0) [0|0] "" X
 SG_ BMS_f153_SW_neg_contactor_welded: 24|1@1+ (1,0) [0|0] "" X
 SG_ BMS_f154_HW_Flood: 25|1@1+ (1,0) [0|0] "" X
 SG_ BMS_f155_SW_BMB_Vref_leaky: 26|1@1+ (1,0) [0|0] "" X
 SG_ BMS_f156_SW_BMB_Vref_bad: 27|1@1+ (1,0) [0|0] "" X
 SG_ BMS_f157_SW_BMS_Standby_Supply: 28|1@1+ (1,0) [0|0] "" X
 SG_ BMS_f158_SW_Low_Isolation_Wrn: 29|1@1+ (1,0) [0|0] "" X
 SG_ BMS_f159_SW_WOT_Cycles_Exceeded: 30|1@1+ (1,0) [0|0] "" X
 SG_ BMS_f160_SW_Brick_Overcharged: 31|1@1+ (1,0) [0|0] "" X
 SG_ BMS_f161_SW_Contactor_Stress: 32|1@1+ (1,0) [0|0] "" X
 SG_ BMS_f162_SW_FC_Prechg_Too_Slow: 33|1@1+ (1,0) [0|0] "" X
 SG_ BMS_f163_SW_Contactor_WOT_Count: 34|1@1+ (1,0) [0|0] "" X
 SG_ BMS_f164_SW_Brick_SOC_Imbalance: 35|1@1+ (1,0) [0|0] "" X
 SG_ BMS_f165_SW_Module_SOC_Imbalance: 36|1@1+ (1,0) [0|0] "" X
 SG_ BMS_f166_SW_AhToBeCharged_Imbal: 37|1@1+ (1,0) [0|0] "" X
 SG_ BMS_f167_SW_Brick_WeakShort: 38|1@1+ (1,0) [0|0] "" X

BO_ 35 BMS_alertMatrix4: 8 ETH
 SG_ BMS_w001_HW_Over_Current: 0|1@1+ (1,0) [0|0] "" X
 SG_ BMS_w002_HW_Over_Voltage: 1|1@1+ (1,0) [0|0] "" X
 SG_ BMS_w003_HW_Module_Alarm: 2|1@1+ (1,0) [0|0] "" X
 SG_ BMS_w004_Unused_4: 3|1@1+ (1,0) [0|0] "" X
 SG_ BMS_w005_Unused_5: 4|1@1+ (1,0) [0|0] "" X
 SG_ BMS_w006_HW_Ctr_Sfty_Override: 5|1@1+ (1,0) [0|0] "" X
 SG_ BMS_w007_SW_Module_Alarm_Broken: 6|1@1+ (1,0) [0|0] "" X
 SG_ BMS_w008_HW_HVIL: 7|1@1+ (1,0) [0|0] "" X
 SG_ BMS_w009_SW_Pos_Contactor_Drive: 8|1@1+ (1,0) [0|0] "" X
 SG_ BMS_w010_SW_Neg_Contactor_Drive: 9|1@1+ (1,0) [0|0] "" X
 SG_ BMS_w011_HW_Illegal_Ctr_Req: 10|1@1+ (1,0) [0|0] "" X
 SG_ BMS_w012_HW_Pump_Drive_Fault: 11|1@1+ (1,0) [0|0] "" X
 SG_ BMS_w013_HW_Liquid_Detected: 12|1@1+ (1,0) [0|0] "" X
 SG_ BMS_w014_HW_Heater_Drive: 13|1@1+ (1,0) [0|0] "" X
 SG_ BMS_w015_HW_Sleep_Attempt: 14|1@1+ (1,0) [0|0] "" X
 SG_ BMS_w016_SW_Thermal_Gradient: 15|1@1+ (1,0) [0|0] "" X
 SG_ BMS_w017_SW_Brick_OV: 16|1@1+ (1,0) [0|0] "" X
 SG_ BMS_w018_SW_Brick_UV: 17|1@1+ (1,0) [0|0] "" X
 SG_ BMS_w019_SW_BMB_Module_OT: 18|1@1+ (1,0) [0|0] "" X
 SG_ BMS_w020_SW_BMB_PCB_OT: 19|1@1+ (1,0) [0|0] "" X
 SG_ BMS_w021_SW_Dr_Limits_Regulation: 20|1@1+ (1,0) [0|0] "" X
 SG_ BMS_w022_SW_Over_Current: 21|1@1+ (1,0) [0|0] "" X
 SG_ BMS_w023_SW_Contactors_Open_HWOC: 22|1@1+ (1,0) [0|0] "" X
 SG_ BMS_w024_SW_Ctrs_Open_Under_Load: 23|1@1+ (1,0) [0|0] "" X
 SG_ BMS_w025_SW_FC_Ctrs_Open_Undr_Ld: 24|1@1+ (1,0) [0|0] "" X
 SG_ BMS_w026_SW_Ctrs_Disabled: 25|1@1+ (1,0) [0|0] "" X
 SG_ BMS_w027_Unused_27: 26|1@1+ (1,0) [0|0] "" X
 SG_ BMS_w028_Unused_28: 27|1@1+ (1,0) [0|0] "" X
 SG_ BMS_w029_SW_Current_Sensor_Reset: 28|1@1+ (1,0) [0|0] "" X
 SG_ BMS_w030_SW_Chg_Port_Door_Open: 29|1@1+ (1,0) [0|0] "" X
 SG_ BMS_w031_SW_Precharge_Res_Hot: 30|1@1+ (1,0) [0|0] "" X
 SG_ BMS_w032_SW_BusVNotReducing: 31|1@1+ (1,0) [0|0] "" X
 SG_ BMS_w033_SW_Crash: 32|1@1+ (1,0) [0|0] "" X
 SG_ BMS_w034_SW_Isolation_Sensor: 33|1@1+ (1,0) [0|0] "" X
 SG_ BMS_w035_SW_Isolation: 34|1@1+ (1,0) [0|0] "" X
 SG_ BMS_w036_SW_HVIL: 35|1@1+ (1,0) [0|0] "" X
 SG_ BMS_w037_SW_Pos_Contactor: 36|1@1+ (1,0) [0|0] "" X
 SG_ BMS_w038_SW_Neg_Contactor: 37|1@1+ (1,0) [0|0] "" X
 SG_ BMS_w039_SW_DC_Link_Over_Voltage: 38|1@1+ (1,0) [0|0] "" X
 SG_ BMS_w040_SW_BMS_PCB_OT: 39|1@1+ (1,0) [0|0] "" X
 SG_ BMS_w041_SW_Liquid_Detected: 40|1@1+ (1,0) [0|0] "" X
 SG_ BMS_w042_SW_Humidity: 41|1@1+ (1,0) [0|0] "" X
 SG_ BMS_w043_SW_Watch_Dog_Reset: 42|1@1+ (1,0) [0|0] "" X
 SG_ BMS_w044_SW_Assertion: 43|1@1+ (1,0) [0|0] "" X
 SG_ BMS_w045_SW_Internal_CANB_error: 44|1@1+ (1,0) [0|0] "" X
 SG_ BMS_w046_SW_External_CANA_error: 45|1@1+ (1,0) [0|0] "" X
 SG_ BMS_w047_SW_Memory_Error: 46|1@1+ (1,0) [0|0] "" X
 SG_ BMS_w048_SW_SCC: 47|1@1+ (1,0) [0|0] "" X
 SG_ BMS_w049_SW_Thermal_Event: 48|1@1+ (1,0) [0|0] "" X
 SG_ BMS_w050_SW_BMB_MIA: 49|1@1+ (1,0) [0|0] "" X
 SG_ BMS_w051_SW_Current_Sensor_MIA: 50|1@1+ (1,0) [0|0] "" X
 SG_ BMS_w052_SW_Charger_MIA: 51|1@1+ (1,0) [0|0] "" X
 SG_ BMS_w053_SW_EVCM_MIA: 52|1@1+ (1,0) [0|0] "" X
 SG_ BMS_w054_SW_Current_Sensor: 53|1@1+ (1,0) [0|0] "" X
 SG_ BMS_w055_SW_Pump: 54|1@1+ (1,0) [0|0] "" X
 SG_ BMS_w056_SW_Module_Temp_Outlier: 55|1@1+ (1,0) [0|0] "" X
 SG_ BMS_w057_SW_Chiller: 56|1@1+ (1,0) [0|0] "" X
 SG_ BMS_w058_SW_Heater_Performance: 57|1@1+ (1,0) [0|0] "" X
 SG_ BMS_w059_SW_Pack_Voltage_Sensing: 58|1@1+ (1,0) [0|0] "" X
 SG_ BMS_w060_SW_BMB_Power_Supply: 59|1@1+ (1,0) [0|0] "" X
 SG_ BMS_w061_SW_BMS_Power_Supply: 60|1@1+ (1,0) [0|0] "" X
 SG_ BMS_w062_SW_Ctr_Pwr_Supply: 61|1@1+ (1,0) [0|0] "" X
 SG_ BMS_w063_SW_Precharge_Failure: 62|1@1+ (1,0) [0|0] "" X
 SG_ BMS_w064_SW_BrickV_Imbalance: 63|1@1+ (1,0) [0|0] "" X

BO_ 96 BMS_alertMatrix5: 8 ETH
 SG_ BMS_w065_SW_Brick_Low_Capacity: 0|1@1+ (1,0) [0|0] "" X
 SG_ BMS_w066_SW_High_Brick_Imp: 1|1@1+ (1,0) [0|0] "" X
 SG_ BMS_w067_SW_Low_Coolnt_Flow_Rate: 2|1@1+ (1,0) [0|0] "" X
 SG_ BMS_w068_SW_Low_SOC: 3|1@1+ (1,0) [0|0] "" X
 SG_ BMS_w069_SW_Low_Power: 4|1@1+ (1,0) [0|0] "" X
 SG_ BMS_w070_Unused_70: 5|1@1+ (1,0) [0|0] "" X
 SG_ BMS_w071_SW_SM_TransCon_Not_Met: 6|1@1+ (1,0) [0|0] "" X
 SG_ BMS_w072_SW_Unexpctd_Ctr_Bhvr: 7|1@1+ (1,0) [0|0] "" X
 SG_ BMS_w073_SW_Unexpctd_HV_Sys_Bhvr: 8|1@1+ (1,0) [0|0] "" X
 SG_ BMS_w074_SW_Charging: 9|1@1+ (1,0) [0|0] "" X
 SG_ BMS_w075_SW_Heater_Temp_Sensor: 10|1@1+ (1,0) [0|0] "" X
 SG_ BMS_w076_SW_Manifold_Temp_Sensor: 11|1@1+ (1,0) [0|0] "" X
 SG_ BMS_w077_SW_Charger_Regulation: 12|1@1+ (1,0) [0|0] "" X
 SG_ BMS_w078_SW_Heater_Over_Temp: 13|1@1+ (1,0) [0|0] "" X
 SG_ BMS_w079_SW_Ctr_Pwr_Interrupted: 14|1@1+ (1,0) [0|0] "" X
 SG_ BMS_w080_SW_Int_HV_Disconnect: 15|1@1+ (1,0) [0|0] "" X
 SG_ BMS_w081_SW_Liquid_Sensor_MIA: 16|1@1+ (1,0) [0|0] "" X
 SG_ BMS_w082_SW_BMS_MIA: 17|1@1+ (1,0) [0|0] "" X
 SG_ BMS_w083_SW_PacMan: 18|1@1+ (1,0) [0|0] "" X
 SG_ BMS_w084_SW_Pack_Imbalance: 19|1@1+ (1,0) [0|0] "" X
 SG_ BMS_w085_SW_Prechg_Too_Slow: 20|1@1+ (1,0) [0|0] "" X
 SG_ BMS_w086_SW_Not_Ok_To_Precharge: 21|1@1+ (1,0) [0|0] "" X
 SG_ BMS_w087_SW_Prechg_Too_Fast: 22|1@1+ (1,0) [0|0] "" X
 SG_ BMS_w088_SW_DTC: 23|1@1+ (1,0) [0|0] "" X
 SG_ BMS_w089_SW_THC_MIA: 24|1@1+ (1,0) [0|0] "" X
 SG_ BMS_w090_SW_GTW_Msg_Latency: 25|1@1+ (1,0) [0|0] "" X
 SG_ BMS_w091_RESERVED_W169_FC_SW_1: 26|1@1+ (1,0) [0|0] "" X
 SG_ BMS_w092_RESERVED_W169_FC_SW_2: 27|1@1+ (1,0) [0|0] "" X
 SG_ BMS_w093_SW_FastChg_Problem: 28|1@1+ (1,0) [0|0] "" X
 SG_ BMS_w094_SW_Drive_Inverter_MIA: 29|1@1+ (1,0) [0|0] "" X
 SG_ BMS_w095_SW_FastChg_Regulation: 30|1@1+ (1,0) [0|0] "" X
 SG_ BMS_w096_SW_Fast_Charger_MIA: 31|1@1+ (1,0) [0|0] "" X
 SG_ BMS_w097_HW_BMB_Under_Voltage: 32|1@1+ (1,0) [0|0] "" X
 SG_ BMS_w098_HW_BMB_Over_Voltage: 33|1@1+ (1,0) [0|0] "" X
 SG_ BMS_w099_SW_BMB_Communication: 34|1@1+ (1,0) [0|0] "" X
 SG_ BMS_w100_HW_BMB_Reset: 35|1@1+ (1,0) [0|0] "" X
 SG_ BMS_w101_HW_BMB_Over_Temperature: 36|1@1+ (1,0) [0|0] "" X
 SG_ BMS_w102_HW_BMB_Thermal_Shutdown: 37|1@1+ (1,0) [0|0] "" X
 SG_ BMS_w103_HW_BMB_Memory_Parity: 38|1@1+ (1,0) [0|0] "" X
 SG_ BMS_w104_HW_BMB_Enumeration: 39|1@1+ (1,0) [0|0] "" X
 SG_ BMS_w105_SW_One_Module_Tsense: 40|1@1+ (1,0) [0|0] "" X
 SG_ BMS_w106_SW_All_Module_Tsense: 41|1@1+ (1,0) [0|0] "" X
 SG_ BMS_w107_SW_Cell_Voltage_Sensor: 42|1@1+ (1,0) [0|0] "" X
 SG_ BMS_w108_HW_BMB_Alarm_Self_Test: 43|1@1+ (1,0) [0|0] "" X
 SG_ BMS_w109_SW_Bleed_Resistor: 44|1@1+ (1,0) [0|0] "" X
 SG_ BMS_w110_SW_Module_Vsense: 45|1@1+ (1,0) [0|0] "" X
 SG_ BMS_w111_SW_BMB_ADC_: 46|1@1+ (1,0) [0|0] "" X
 SG_ BMS_w112_SW_Pos_Contactor_ANC: 47|1@1+ (1,0) [0|0] "" X
 SG_ BMS_w113_SW_Neg_Contactor_ANC: 48|1@1+ (1,0) [0|0] "" X
 SG_ BMS_w114_SW_FC_Contactors: 49|1@1+ (1,0) [0|0] "" X
 SG_ BMS_w115_SW_Neg_Contactor_FC: 50|1@1+ (1,0) [0|0] "" X
 SG_ BMS_w116_SW_BusV_Not_Reducing_FC: 51|1@1+ (1,0) [0|0] "" X
 SG_ BMS_w117_SW_Wrong_Battery_Pack: 52|1@1+ (1,0) [0|0] "" X
 SG_ BMS_w118_SW_DC_Link_Voltage_ANC: 53|1@1+ (1,0) [0|0] "" X
 SG_ BMS_w119_SW_DC_Link_Voltage_FC: 54|1@1+ (1,0) [0|0] "" X
 SG_ BMS_w120_SW_Moisture_CtrlSys: 55|1@1+ (1,0) [0|0] "" X
 SG_ BMS_w121_SW_BMS_PCB_HumiditySens: 56|1@1+ (1,0) [0|0] "" X
 SG_ BMS_w122_SW_BMS_PCB_Temp_Sensor: 57|1@1+ (1,0) [0|0] "" X
 SG_ BMS_w123_SW_Internal_Isolation: 58|1@1+ (1,0) [0|0] "" X
 SG_ BMS_w124_SW_BMB_Comm_Integrity: 59|1@1+ (1,0) [0|0] "" X
 SG_ BMS_w125_SW_BMS_Ctr_Curr_Sensor: 60|1@1+ (1,0) [0|0] "" X
 SG_ BMS_w126_HW_BMS_Blind_Mate: 61|1@1+ (1,0) [0|0] "" X
 SG_ BMS_w127_SW_CPLD_CRC: 62|1@1+ (1,0) [0|0] "" X
 SG_ BMS_w128_SW_MIL_DTC_set: 63|1@1+ (1,0) [0|0] "" X

BO_ 97 BMS_alertMatrix6: 8 ETH
 SG_ BMS_w129_SW_BMB_VSH_Connector: 0|1@1+ (1,0) [0|0] "" X
 SG_ BMS_w130_SW_Module_Alrm_Redund: 1|1@1+ (1,0) [0|0] "" X
 SG_ BMS_w131_SW_PCB_Temp_Sensor_MIA: 2|1@1+ (1,0) [0|0] "" X
 SG_ BMS_w132_HW_BMB_OTP_Uncorrctbl: 3|1@1+ (1,0) [0|0] "" X
 SG_ BMS_w133_SW_Service_Tool: 4|1@1+ (1,0) [0|0] "" X
 SG_ BMS_w134_SW_Delayed_Ctr_Off: 5|1@1+ (1,0) [0|0] "" X
 SG_ BMS_w135_SW_Network_Management: 6|1@1+ (1,0) [0|0] "" X
 SG_ BMS_w136_SW_Module_OT_Warning: 7|1@1+ (1,0) [0|0] "" X
 SG_ BMS_w137_SW_Brick_UV_Warning: 8|1@1+ (1,0) [0|0] "" X
 SG_ BMS_w138_SW_Brick_OV_Warning: 9|1@1+ (1,0) [0|0] "" X
 SG_ BMS_w139_SW_DC_Link_V_Irrational: 10|1@1+ (1,0) [0|0] "" X
 SG_ BMS_w140_SW_OverCurrent_Sense: 11|1@1+ (1,0) [0|0] "" X
 SG_ BMS_w141_SW_12V_Pwr_Supply_Low: 12|1@1+ (1,0) [0|0] "" X
 SG_ BMS_w142_SW_Isolation_Degradatio: 13|1@1+ (1,0) [0|0] "" X
 SG_ BMS_w143_SW_BMB_OTP_Reg_Wrong: 14|1@1+ (1,0) [0|0] "" X
 SG_ BMS_w144_SW_CPLD_Version_Wrong: 15|1@1+ (1,0) [0|0] "" X
 SG_ BMS_w145_SW_socChange: 16|1@1+ (1,0) [0|0] "" X
 SG_ BMS_w146_SW_Brick_Overdischarged: 17|1@1+ (1,0) [0|0] "" X
 SG_ BMS_w147_SW_Safety: 18|1@1+ (1,0) [0|0] "" X
 SG_ BMS_w148_SW_DrvDenied_BattEmpty: 19|1@1+ (1,0) [0|0] "" X
 SG_ BMS_w149_SW_precharge_too_short: 20|1@1+ (1,0) [0|0] "" X
 SG_ BMS_w150_SW_precharge_too_long: 21|1@1+ (1,0) [0|0] "" X
 SG_ BMS_w151_SW_external_isolation: 22|1@1+ (1,0) [0|0] "" X
 SG_ BMS_w152_SW_pos_contactor_welded: 23|1@1+ (1,0) [0|0] "" X
 SG_ BMS_w153_SW_neg_contactor_welded: 24|1@1+ (1,0) [0|0] "" X
 SG_ BMS_w154_HW_Flood: 25|1@1+ (1,0) [0|0] "" X
 SG_ BMS_w155_SW_BMB_Vref_leaky: 26|1@1+ (1,0) [0|0] "" X
 SG_ BMS_w156_SW_BMB_Vref_bad: 27|1@1+ (1,0) [0|0] "" X
 SG_ BMS_w157_SW_BMS_Standby_Supply: 28|1@1+ (1,0) [0|0] "" X
 SG_ BMS_w158_SW_Low_Isolation_Wrn: 29|1@1+ (1,0) [0|0] "" X
 SG_ BMS_w159_SW_WOT_Cycles_Exceeded: 30|1@1+ (1,0) [0|0] "" X
 SG_ BMS_w160_SW_Brick_Overcharged: 31|1@1+ (1,0) [0|0] "" X
 SG_ BMS_w161_SW_Contactor_Stress: 32|1@1+ (1,0) [0|0] "" X
 SG_ BMS_w162_SW_FC_Prechg_Too_Slow: 33|1@1+ (1,0) [0|0] "" X
 SG_ BMS_w163_SW_Contactor_WOT_Count: 34|1@1+ (1,0) [0|0] "" X
 SG_ BMS_w164_SW_Brick_SOC_Imbalance: 35|1@1+ (1,0) [0|0] "" X
 SG_ BMS_w165_SW_Module_SOC_Imbalance: 36|1@1+ (1,0) [0|0] "" X
 SG_ BMS_w166_SW_AhToBeCharged_Imbal: 37|1@1+ (1,0) [0|0] "" X
 SG_ BMS_w167_SW_Brick_WeakShort: 38|1@1+ (1,0) [0|0] "" X

BO_ 994 BMS_alertMatrix7: 8 ETH
 SG_ BMS_u001_DisChg_While_Charging: 0|1@1+ (1,0) [0|0] "" X
 SG_ BMS_u002_Ramp_Down_Active: 1|1@1+ (1,0) [0|0] "" X
 SG_ BMS_u003_Insufficient_drive_pwr: 2|1@1+ (1,0) [0|0] "" X
 SG_ BMS_u004_Charge_Cable_Connected: 3|1@1+ (1,0) [0|0] "" X
 SG_ BMS_u005_Low_Power_Until_Charge: 4|1@1+ (1,0) [0|0] "" X
 SG_ BMS_u006_End_of_Drive_Ramp_Down: 5|1@1+ (1,0) [0|0] "" X
 SG_ BMS_u007_Unused_u7: 6|1@1+ (1,0) [0|0] "" X
 SG_ BMS_u008_limpMode: 7|1@1+ (1,0) [0|0] "" X
 SG_ BMS_u009_Power_Will_Improve: 8|1@1+ (1,0) [0|0] "" X
 SG_ BMS_u010_Power_Will_NOT_Improve: 9|1@1+ (1,0) [0|0] "" X
 SG_ BMS_u011_Fast_Charger_Problem: 10|1@1+ (1,0) [0|0] "" X
 SG_ BMS_u012_Fast_Charger_Incompat: 11|1@1+ (1,0) [0|0] "" X
 SG_ BMS_u013_Not_Supercharge_Capable: 12|1@1+ (1,0) [0|0] "" X
 SG_ BMS_u014_Not_Enough_Pwr_To_Heat: 13|1@1+ (1,0) [0|0] "" X
 SG_ BMS_u015_Not_Fast_Charge_Capable: 14|1@1+ (1,0) [0|0] "" X
 SG_ BMS_u016_FEIM_Delayed_Ctr_Close: 15|1@1+ (1,0) [0|0] "" X
 SG_ BMS_u017_Charge_Already_Complete: 16|1@1+ (1,0) [0|0] "" X
 SG_ BMS_u018_Max_Charge_Limited: 17|1@1+ (1,0) [0|0] "" X
 SG_ BMS_u019_Acceleration_Reduced: 18|1@1+ (1,0) [0|0] "" X
 SG_ BMS_u020_Cannot_Precharge_FC: 19|1@1+ (1,0) [0|0] "" X
 SG_ BMS_u021_SC_Post_Out_Of_Service: 20|1@1+ (1,0) [0|0] "" X
 SG_ BMS_u022_EVSE_UpdateInProgress: 21|1@1+ (1,0) [0|0] "" X
 SG_ BMS_u023_AdapterUpdateInProgress: 22|1@1+ (1,0) [0|0] "" X
 SG_ BMS_u024_Not_Uncorked_Capable: 23|1@1+ (1,0) [0|0] "" X

BO_ 6 BMS_bmbMinMax: 8 ETH
 SG_ BMS_brickNumVoltageMax: 16|7@1+ (1,1) [0|0] "" X
 SG_ BMS_brickNumVoltageMin: 48|7@1+ (1,1) [0|0] "" X
 SG_ BMS_brickVoltageMax: 0|12@1+ (0.002,0) [0|0] "V" X
 SG_ BMS_brickVoltageMin: 32|12@1+ (0.002,0) [0|0] "V" X
 SG_ BMS_moduleNumTMax: 12|4@1+ (1,1) [0|0] "" X
 SG_ BMS_moduleNumTMin: 44|4@1+ (1,1) [0|0] "" X
 SG_ BMS_moduleTMax: 24|8@1+ (0.5,-40) [0|0] "DegC" X
 SG_ BMS_moduleTMin: 56|8@1+ (0.5,-40) [0|0] "DegC" X
 SG_ BMS_sensorNumTMax: 23|1@1+ (1,1) [0|0] "" X
 SG_ BMS_sensorNumTMin: 55|1@1+ (1,1) [0|0] "" X

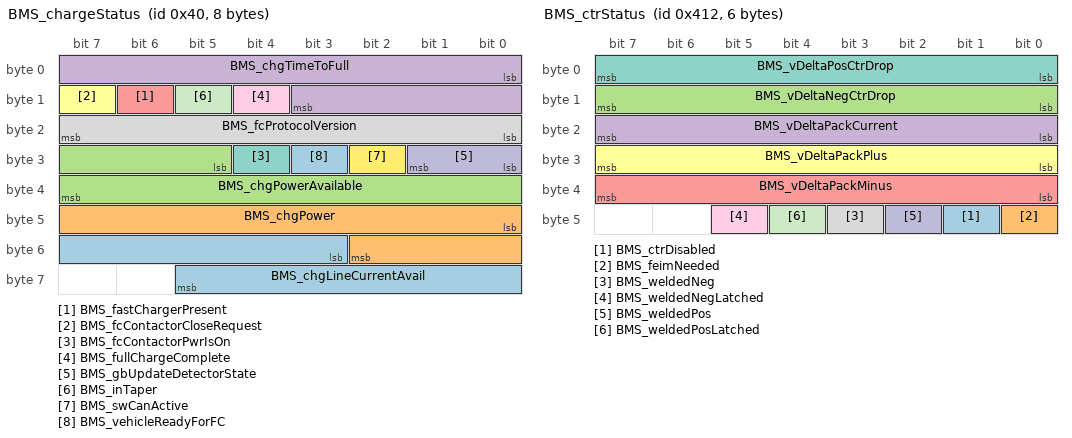
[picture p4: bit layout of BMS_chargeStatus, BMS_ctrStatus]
BO_ 64 BMS_chargeStatus: 8 ETH
 SG_ BMS_chgLineCurrentAvail: 51|11@1+ (0.05,0) [0|0] "A" X
 SG_ BMS_chgPower: 40|11@1+ (0.125,0) [0|0] "kW" X
 SG_ BMS_chgPowerAvailable: 29|11@1+ (0.125,0) [0|0] "kW" X
 SG_ BMS_chgTimeToFull: 0|12@1+ (0.0166667,0) [0|0] "Hours" X
 SG_ BMS_fastChargerPresent: 14|1@1+ (1,0) [0|0] "" X
 SG_ BMS_fcContactorCloseRequest: 15|1@1+ (1,0) [0|0] "" X
 SG_ BMS_fcContactorPwrIsOn: 28|1@1+ (1,0) [0|0] "" X
 SG_ BMS_fcProtocolVersion: 16|8@1+ (1,0) [0|0] "" X
 SG_ BMS_fullChargeComplete: 12|1@1+ (1,0) [0|0] "" X
 SG_ BMS_gbUpdateDetectorState: 24|2@1+ (1,0) [0|0] "" X
 SG_ BMS_inTaper: 13|1@1+ (1,0) [0|0] "" X
 SG_ BMS_swCanActive: 26|1@1+ (1,0) [0|0] "" X
 SG_ BMS_vehicleReadyForFC: 27|1@1+ (1,0) [0|0] "" X

BO_ 1042 BMS_ctrStatus: 6 ETH
 SG_ BMS_ctrDisabled: 41|1@1+ (1,0) [0|0] "" X
 SG_ BMS_feimNeeded: 40|1@1+ (1,0) [0|0] "" X
 SG_ BMS_vDeltaNegCtrDrop: 8|8@1- (0.125,0) [0|0] "V" X
 SG_ BMS_vDeltaPackCurrent: 16|8@1+ (5,-1000) [0|0] "A" X
 SG_ BMS_vDeltaPackMinus: 32|8@1+ (2,0) [0|0] "V" X
 SG_ BMS_vDeltaPackPlus: 24|8@1+ (2,0) [0|0] "V" X
 SG_ BMS_vDeltaPosCtrDrop: 0|8@1- (0.125,0) [0|0] "V" X
 SG_ BMS_weldedNeg: 43|1@1+ (1,0) [0|0] "" X
 SG_ BMS_weldedNegLatched: 45|1@1+ (1,0) [0|0] "" X
 SG_ BMS_weldedPos: 42|1@1+ (1,0) [0|0] "" X
 SG_ BMS_weldedPosLatched: 44|1@1+ (1,0) [0|0] "" X

BO_ 802 BMS_dtcMatrix1: 8 ETH
 SG_ BMS_dtcIndex M: 0|8@1+ (1,0) [0|0] "" X
 SG_ BMS_d001_Internal_Batt_Failure m0: 8|2@1+ (1,0) [0|0] "" X
 SG_ BMS_d002_Internal_Iso_Failure m0: 10|2@1+ (1,0) [0|0] "" X
 SG_ BMS_d003_FEIM_Failure m0: 12|2@1+ (1,0) [0|0] "" X
 SG_ BMS_d004_System_Iso_Failure m0: 14|2@1+ (1,0) [0|0] "" X
 SG_ BMS_d005_Pos_Ctr_Stuck_Closed m0: 16|2@1+ (1,0) [0|0] "" X
 SG_ BMS_d006_Neg_Ctr_Stuck_Closed m0: 18|2@1+ (1,0) [0|0] "" X
 SG_ BMS_d007_HVIL_Fault m0: 20|2@1+ (1,0) [0|0] "" X
 SG_ BMS_d008_HV_Discharge_Fault m0: 22|2@1+ (1,0) [0|0] "" X
 SG_ BMS_d009_Over_Temperature m0: 24|2@1+ (1,0) [0|0] "" X
 SG_ BMS_d010_Precharge_Too_Short m0: 26|2@1+ (1,0) [0|0] "" X
 SG_ BMS_d011_Precharge_Too_Long m0: 28|2@1+ (1,0) [0|0] "" X
 SG_ BMS_d012_12V_Undervoltage m0: 30|2@1+ (1,0) [0|0] "" X
 SG_ BMS_d013_12V_Overvoltage m0: 32|2@1+ (1,0) [0|0] "" X
 SG_ BMS_d014_Replace_Desiccant m0: 34|2@1+ (1,0) [0|0] "" X
 SG_ BMS_d015_Flood m0: 36|2@1+ (1,0) [0|0] "" X

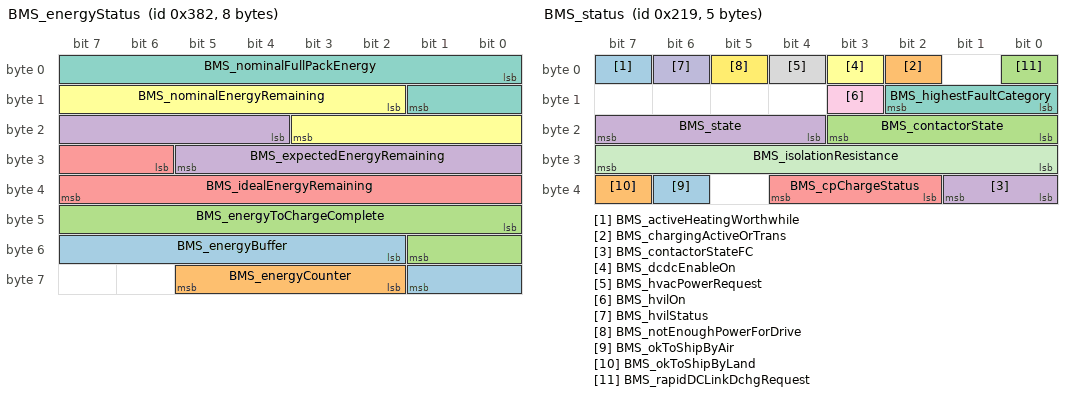
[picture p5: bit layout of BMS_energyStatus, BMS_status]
BO_ 898 BMS_energyStatus: 8 ETH
 SG_ BMS_energyBuffer: 50|8@1+ (0.1,0) [0|0] "KWh" X
 SG_ BMS_energyCounter: 58|4@1+ (1,0) [0|0] "" X
 SG_ BMS_energyToChargeComplete: 40|10@1+ (0.1,0) [0|0] "KWh" X
 SG_ BMS_expectedEnergyRemaining: 20|10@1+ (0.1,0) [0|0] "KWh" X
 SG_ BMS_idealEnergyRemaining: 30|10@1+ (0.1,0) [0|0] "KWh" X
 SG_ BMS_nominalEnergyRemaining: 10|10@1+ (0.1,0) [0|0] "KWh" X
 SG_ BMS_nominalFullPackEnergy: 0|10@1+ (0.1,0) [0|0] "KWh" X

BO_ 1490 BMS_info: 8 ETH
 SG_ BMS_infoIndex M: 0|8@1+ (1,0) [0|0] "" X
 SG_ BMS_infoBuildType m10: 8|8@1+ (1,0) [0|0] "" X
 SG_ BMS_infoBuildConfigID m10: 16|16@1+ (1,0) [0|0] "" X
 SG_ BMS_infoHardwareID m10: 32|16@1+ (1,0) [0|0] "" X
 SG_ BMS_infoComponentID m10: 48|16@1+ (1,0) [0|0] "" X
 SG_ BMS_infoPcbaID m11: 16|8@1+ (1,0) [0|0] "" X
 SG_ BMS_infoAssemblyID m11: 24|8@1+ (1,0) [0|0] "" X
 SG_ BMS_infoUsageID m11: 32|16@1+ (1,0) [0|0] "" X
 SG_ BMS_infoSubUsageID m11: 48|16@1+ (1,0) [0|0] "" X
 SG_ BMS_infoApplicationCRC m13: 32|32@1+ (1,0) [0|0] "" X
 SG_ BMS_infoBootloaderSvnRevision m14: 8|24@1+ (1,0) [0|0] "" X
 SG_ BMS_infoCPLDVersion m16: 16|8@1+ (1,0) [0|0] "" X
 SG_ BMS_infoAppGitHashBytes m17: 10|54@1+ (4,0) [0|0] "" X
 SG_ BMS_infoBootGitHashBytes m18: 10|54@1+ (4,0) [0|0] "" X
 SG_ BMS_infoPlatformType m19: 8|8@1+ (1,0) [0|0] "" X
 SG_ BMS_infoHardwareRevision m19: 40|8@1+ (1,0) [0|0] "" X
 SG_ BMS_infoBootUdsProtoVersion m20: 8|8@1+ (1,0) [0|0] "" X
 SG_ BMS_infoBootloaderCRC m20: 32|32@1+ (1,0) [0|0] "" X

BO_ 978 BMS_kwhCounter: 8 ETH
 SG_ BMS_kwhChargeTotal: 0|32@1+ (0.001,0) [0|0] "kWh" X
 SG_ BMS_kwhDischargeTotal: 32|32@1+ (0.001,0) [0|0] "kWh" X

BO_ 1378 BMS_odometerStatus: 4 ETH
 SG_ BMS_odometer: 0|32@1+ (0.001,0) [0|0] "mi" X

BO_ 65 BMS_socStatus: 8 ETH
 SG_ BMS_kwhCounterType M: 20|2@1+ (1,0) [0|0] "" X
 SG_ BMS_packSOE: 10|10@1+ (0.1,0) [0|0] "%" X
 SG_ BMS_socMin: 0|10@1+ (0.1,0) [0|0] "%" X
 SG_ BMS_dcChargerKwhTotal m0: 32|32@1+ (0.001,0) [0|0] "KWh" X
 SG_ BMS_acChargerKwhTotal m1: 32|32@1+ (0.001,0) [0|0] "KWh" X

BO_ 537 BMS_status: 5 ETH
 SG_ BMS_activeHeatingWorthwhile: 7|1@1+ (1,0) [0|0] "" X
 SG_ BMS_chargingActiveOrTrans: 2|1@1+ (1,0) [0|0] "" X
 SG_ BMS_contactorState: 16|4@1+ (1,0) [0|0] "" X
 SG_ BMS_contactorStateFC: 32|2@1+ (1,0) [0|0] "" X
 SG_ BMS_cpChargeStatus: 34|3@1+ (1,0) [0|0] "" X
 SG_ BMS_dcdcEnableOn: 3|1@1+ (1,0) [0|0] "" X
 SG_ BMS_highestFaultCategory: 8|3@1+ (1,0) [0|0] "" X
 SG_ BMS_hvacPowerRequest: 4|1@1+ (1,0) [0|0] "" X
 SG_ BMS_hvilOn: 11|1@1+ (1,0) [0|0] "" X
 SG_ BMS_hvilStatus: 6|1@1+ (1,0) [0|0] "" X
 SG_ BMS_isolationResistance: 24|8@1+ (20,0) [0|0] "kOhm" X
 SG_ BMS_notEnoughPowerForDrive: 5|1@1+ (1,0) [0|0] "" X
 SG_ BMS_okToShipByAir: 38|1@1+ (1,0) [0|0] "" X
 SG_ BMS_okToShipByLand: 39|1@1+ (1,0) [0|0] "" X
 SG_ BMS_rapidDCLinkDchgRequest: 0|1@1+ (1,0) [0|0] "" X
 SG_ BMS_state: 20|4@1+ (1,0) [0|0] "" X

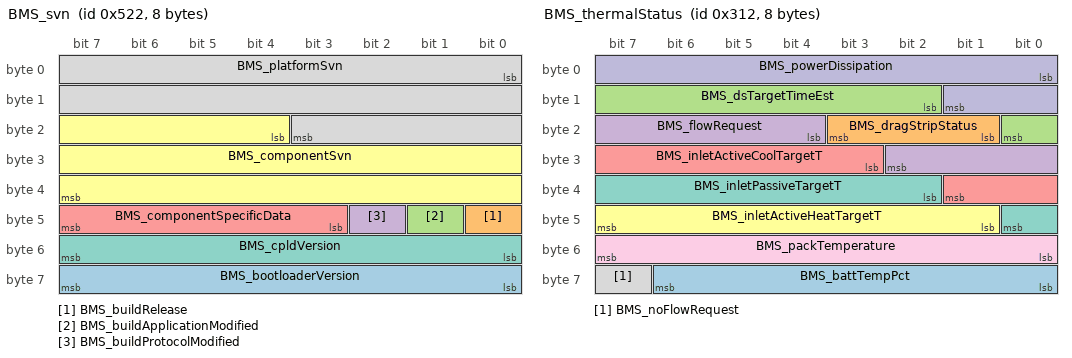
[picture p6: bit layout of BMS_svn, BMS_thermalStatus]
BO_ 1314 BMS_svn: 8 ETH
 SG_ BMS_bootloaderVersion: 56|8@1+ (1,0) [0|0] "" X
 SG_ BMS_buildRelease: 40|1@1+ (1,0) [0|0] "" X
 SG_ BMS_buildApplicationModified: 41|1@1+ (1,0) [0|0] "" X
 SG_ BMS_buildProtocolModified: 42|1@1+ (1,0) [0|0] "" X
 SG_ BMS_componentSpecificData: 43|5@1+ (1,0) [0|0] "" X
 SG_ BMS_componentSvn: 20|20@1+ (1,0) [0|0] "" X
 SG_ BMS_cpldVersion: 48|8@1+ (1,0) [0|0] "" X
 SG_ BMS_platformSvn: 0|20@1+ (1,0) [0|0] "" X

BO_ 786 BMS_thermalStatus: 8 ETH
 SG_ BMS_battTempPct: 56|7@1+ (1,0) [0|0] "%" X
 SG_ BMS_dragStripStatus: 17|3@1+ (1,0) [0|0] "" X
 SG_ BMS_dsTargetTimeEst: 10|7@1+ (1,0) [0|0] "min" X
 SG_ BMS_flowRequest: 20|7@1+ (1,0) [0|0] "%" X
 SG_ BMS_inletActiveCoolTargetT: 27|7@1+ (1,0) [0|0] "DegC" X
 SG_ BMS_inletActiveHeatTargetT: 41|7@1+ (1,-40) [0|0] "DegC" X
 SG_ BMS_inletPassiveTargetT: 34|7@1+ (1,-20) [0|0] "DegC" X
 SG_ BMS_noFlowRequest: 63|1@1+ (1,0) [0|0] "" X
 SG_ BMS_packTemperature: 48|8@1- (1,40) [0|0] "C" X
 SG_ BMS_powerDissipation: 0|10@1+ (0.02,0) [0|0] "kW" X

BO_ 1554 BMS_udsResponse: 8 ETH
 SG_ BMS_udsResponseData: 0|54@0+ (1024,0) [0|0] "" X

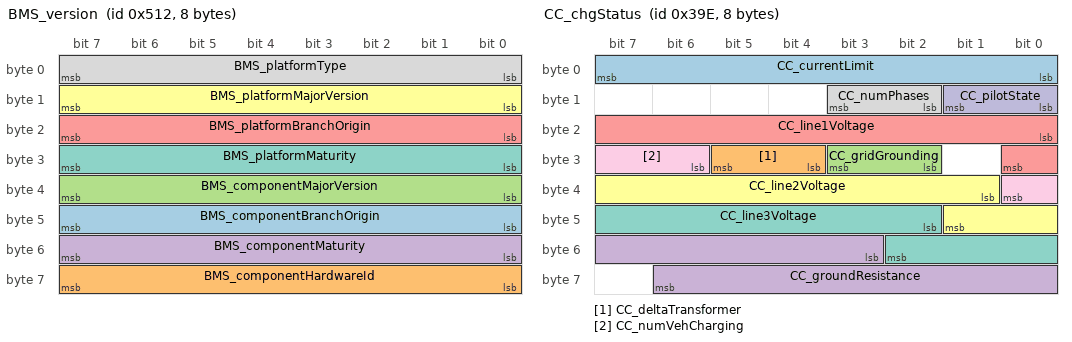
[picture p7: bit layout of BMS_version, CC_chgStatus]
BO_ 1298 BMS_version: 8 ETH
 SG_ BMS_componentBranchOrigin: 40|8@1+ (1,0) [0|0] "" X
 SG_ BMS_componentHardwareId: 56|8@1+ (1,0) [0|0] "" X
 SG_ BMS_componentMajorVersion: 32|8@1+ (1,0) [0|0] "" X
 SG_ BMS_componentMaturity: 48|8@1+ (1,0) [0|0] "" X
 SG_ BMS_platformBranchOrigin: 16|8@1+ (1,0) [0|0] "" X
 SG_ BMS_platformMajorVersion: 8|8@1+ (1,0) [0|0] "" X
 SG_ BMS_platformMaturity: 24|8@1+ (1,0) [0|0] "" X
 SG_ BMS_platformType: 0|8@1+ (1,0) [0|0] "" X

BO_ 926 CC_chgStatus: 8 ETH
 SG_ CC_currentLimit: 0|8@1+ (0.5,0) [0|0] "A" X
 SG_ CC_deltaTransformer: 28|2@1+ (1,0) [0|0] "" X
 SG_ CC_gridGrounding: 26|2@1+ (1,0) [0|0] "" X
 SG_ CC_groundResistance: 51|12@1+ (1,0) [0|0] "kOhm" X
 SG_ CC_line1Voltage: 16|9@1+ (1,0) [0|0] "V" X
 SG_ CC_line2Voltage: 33|9@1+ (1,0) [0|0] "V" X
 SG_ CC_line3Voltage: 42|9@1+ (1,0) [0|0] "V" X
 SG_ CC_numPhases: 10|2@1+ (1,0) [0|0] "" X
 SG_ CC_numVehCharging: 30|3@1+ (1,0) [0|0] "" X
 SG_ CC_pilotState: 8|2@1+ (1,0) [0|0] "" X

BO_ 647 CC_faultMatrix: 8 ETH
 SG_ CC_f001_gndMonIntrptLineSide: 0|1@1+ (1,0) [0|0] "" X
 SG_ CC_f002_gndMonIntrptLoadSide: 1|1@1+ (1,0) [0|0] "" X
 SG_ CC_f003_CCIDTripped: 2|1@1+ (1,0) [0|0] "" X
 SG_ CC_f004_CCIDSelfTestFault: 3|1@1+ (1,0) [0|0] "" X
 SG_ CC_f005_groundedNeutral: 4|1@1+ (1,0) [0|0] "" X
 SG_ CC_f006_inputOverCurrent: 5|1@1+ (1,0) [0|0] "" X
 SG_ CC_f007_inputOverVoltage: 6|1@1+ (1,0) [0|0] "" X
 SG_ CC_f008_inputUnderVoltage: 7|1@1+ (1,0) [0|0] "" X
 SG_ CC_f009_inputMiswired: 8|1@1+ (1,0) [0|0] "" X
 SG_ CC_f010_contactorWelded: 9|1@1+ (1,0) [0|0] "" X
 SG_ CC_f011_ambientOT: 10|1@1+ (1,0) [0|0] "" X
 SG_ CC_f012_wallPlugOT: 11|1@1+ (1,0) [0|0] "" X
 SG_ CC_f013_vehConnOT: 12|1@1+ (1,0) [0|0] "" X
 SG_ CC_f014_mcuSelfTestFault: 13|1@1+ (1,0) [0|0] "" X
 SG_ CC_f015_PilotAFault: 14|1@1+ (1,0) [0|0] "" X
 SG_ CC_f016_PilotBFault: 15|1@1+ (1,0) [0|0] "" X
 SG_ CC_f017_PilotCFault: 16|1@1+ (1,0) [0|0] "" X
 SG_ CC_f018_PilotDFault: 17|1@1+ (1,0) [0|0] "" X
 SG_ CC_f019_proxDisconnected: 18|1@1+ (1,0) [0|0] "" X
 SG_ CC_f020_3vRailIncorrect: 19|1@1+ (1,0) [0|0] "" X
 SG_ CC_f021_CB_noMaster: 20|1@1+ (1,0) [0|0] "" X
 SG_ CC_f022_CB_tooManyMasters: 21|1@1+ (1,0) [0|0] "" X
 SG_ CC_f023_CB_tooManySlaves: 22|1@1+ (1,0) [0|0] "" X
 SG_ CC_f024_CB_masterISetTooLow: 23|1@1+ (1,0) [0|0] "" X
 SG_ CC_f025_evseTemp: 24|1@1+ (1,0) [0|0] "" X
 SG_ CC_f026_wallPlugTemp: 25|1@1+ (1,0) [0|0] "" X
 SG_ CC_f027_vehicleHandleTemp: 26|1@1+ (1,0) [0|0] "" X
 SG_ CC_f028_CB_rotarySelect: 27|1@1+ (1,0) [0|0] "" X
 SG_ CC_f029_PilotFFault: 28|1@1+ (1,0) [0|0] "" X
 SG_ CC_f030_masterSlaveMismatch: 29|1@1+ (1,0) [0|0] "" X

BO_ 1134 CC_logData: 8 ETH
 SG_ CC_logIndex M: 0|8@1+ (1,0) [0|0] "" X
 SG_ CC_activeConnectorID m0: 8|8@1+ (1,0) [0|0] "" X
 SG_ CC_temperature1 m0: 16|8@1- (1,88) [0|0] "DegC" X
 SG_ CC_temperature2 m0: 24|8@1- (1,88) [0|0] "DegC" X
 SG_ CC_temperature3 m0: 32|8@1- (1,88) [0|0] "DegC" X
 SG_ CC_contactor1Closed m0: 40|2@1+ (1,0) [0|0] "" X
 SG_ CC_contactor2Closed m0: 42|2@1+ (1,0) [0|0] "" X
 SG_ CC_temperature4 m0: 44|8@1- (1,88) [0|0] "DegC" X
 SG_ CC_conn1Current m1: 8|8@1+ (0.5,0) [0|0] "A" X
 SG_ CC_conn2Current m2: 8|8@1+ (0.5,0) [0|0] "A" X
 SG_ CC_conn3Current m3: 8|8@1+ (0.5,0) [0|0] "A" X
 SG_ CC_conn4Current m4: 8|8@1+ (0.5,0) [0|0] "A" X
 SG_ CC_lifetimei2t m10: 32|32@1+ (0.1,0) [0|0] "A2h" X
 SG_ CC_lifetimeCtrCycles m11: 8|28@1+ (1,0) [0|0] "" X
 SG_ CC_lifetimeCtrCyclesLoaded m11: 36|28@1+ (1,0) [0|0] "" X
 SG_ CC_lifetimeAlertCount m12: 8|28@1+ (1,0) [0|0] "" X
 SG_ CC_lifetimeThermalFoldbacks m12: 36|28@1+ (1,0) [0|0] "" X
 SG_ CC_lifetimeAvgStartupTemp m13: 36|28@1- (0.1,0) [0|0] "degC" X

BO_ 592 CHADA_status_1: 8 ETH
 SG_ CA_status1DataSelect M: 0|7@1+ (1,0) [0|0] "" X
 SG_ CA_status1DummySig: 7|1@1+ (1,0) [0|0] "" X
 SG_ CA_pilotState m0: 8|2@1+ (1,0) [0|0] "" X
 SG_ CA_proximityState m0: 10|2@1+ (1,0) [0|0] "" X
 SG_ CA_swCanRelay m0: 12|1@1+ (1,0) [0|0] "" X
 SG_ CA_flybackEnabled m0: 13|1@1+ (1,0) [0|0] "" X
 SG_ CA_bms_vehicleReady m0: 14|1@1+ (1,0) [0|0] "" X
 SG_ CA_bms_connLocked m0: 15|1@1+ (1,0) [0|0] "" X
 SG_ CA_flybackV m0: 16|16@1+ (0.0128333,0) [0|0] "V" X
 SG_ CA_flybackTargetV m0: 32|16@1+ (0.0128333,0) [0|0] "V" X
 SG_ CA_proximityV m0: 48|16@1+ (5.86634e-05,0) [0|0] "V" X
 SG_ CA_state m1: 8|8@1+ (1,0) [0|0] "" X
 SG_ CA_bms_packVoltage m1: 16|13@1+ (0.0732422,0) [0|0] "V" X
 SG_ CA_evse_ss1Active_GPIO m1: 29|1@1+ (1,0) [0|0] "" X
 SG_ CA_evse_ss2Active_GPIO m1: 30|1@1+ (1,0) [0|0] "" X
 SG_ CA_evse_chgEnable_GPIO m1: 31|1@1+ (1,0) [0|0] "" X
 SG_ CA_bms_packCurrent m1: 32|16@1- (0.0183105,0) [0|0] "A" X
 SG_ CA_pilotMaxV m1: 48|16@1- (0.000865938,0) [0|0] "V" X
 SG_ CA_bms_currentCommand m2: 8|16@1+ (0.0091543,0) [0|0] "A" X
 SG_ CA_bms_voltageLimit m2: 24|16@1+ (0.0091543,0) [0|0] "V" X
 SG_ CA_bms_currentLimit m2: 40|16@1+ (0.0091543,0) [0|0] "A" X
 SG_ CA_bmsStatus m2: 56|2@1+ (1,0) [0|0] "" X
 SG_ CA_evseStatus m2: 58|2@1+ (1,0) [0|0] "" X
 SG_ CA_dbgStatus m2: 60|2@1+ (1,0) [0|0] "" X
 SG_ CA_global_dbg_active m2: 62|1@1+ (1,0) [0|0] "" X
 SG_ CA_VEH_Flag_BAT_V_Over m3: 8|1@1+ (1,0) [0|0] "" X
 SG_ CA_VEH_Flag_BAT_V_Under m3: 9|1@1+ (1,0) [0|0] "" X
 SG_ CA_VEH_Flag_BAT_I_Deviation m3: 10|1@1+ (1,0) [0|0] "" X
 SG_ CA_VEH_Flag_BAT_T_High m3: 11|1@1+ (1,0) [0|0] "" X
 SG_ CA_VEH_Flag_BAT_V_Deviation m3: 12|1@1+ (1,0) [0|0] "" X
 SG_ CA_VEH_Flag_CHR_Enable m3: 13|1@1+ (1,0) [0|0] "" X
 SG_ CA_VEH_Flag_In_Drive m3: 14|1@1+ (1,0) [0|0] "" X
 SG_ CA_VEH_Flag_Other_Fault m3: 15|1@1+ (1,0) [0|0] "" X
 SG_ CA_VEH_Flag_FC_Cont_Open m3: 16|1@1+ (1,0) [0|0] "" X
 SG_ CA_VEH_Flag_Normal_Stop_Req m3: 17|1@1+ (1,0) [0|0] "" X
 SG_ CA_EVSE_Flag_CHR_Enabled m3: 18|1@1+ (1,0) [0|0] "" X
 SG_ CA_EVSE_Flag_CHR_Malfunc m3: 19|1@1+ (1,0) [0|0] "" X
 SG_ CA_EVSE_Flag_CHR_ConLock m3: 20|1@1+ (1,0) [0|0] "" X
 SG_ CA_EVSE_Flag_BAT_Incomp m3: 21|1@1+ (1,0) [0|0] "" X
 SG_ CA_EVSE_Flag_BAT_Malfunc m3: 22|1@1+ (1,0) [0|0] "" X
 SG_ CA_EVSE_Flag_Stop_Req m3: 23|1@1+ (1,0) [0|0] "" X
 SG_ CA_fc_dcVoltage m3: 24|16@1+ (0.0128333,0) [0|0] "V" X
 SG_ CA_voltageRail12V m3: 40|16@1+ (0.00028966,0) [0|0] "V" X
 SG_ CA_pilotDrv m3: 56|2@1+ (1,0) [0|0] "" X
 SG_ CA_flybackState m3: 58|2@1+ (1,0) [0|0] "" X
 SG_ CA_flybackTargetState m3: 60|2@1+ (1,0) [0|0] "" X
 SG_ CA_EVSE_Present_V_Out m4: 8|16@1+ (1,0) [0|0] "V" X
 SG_ CA_EVSE_Present_I_Out m4: 24|8@1+ (1,0) [0|0] "A" X
 SG_ CA_VEH_Request_I m4: 32|8@1+ (1,0) [0|0] "A" X
 SG_ CA_flybackMaxV m4: 40|16@1+ (0.0128333,0) [0|0] "V" X
 SG_ CA_shutdownSource m4: 56|2@1+ (1,0) [0|0] "" X
 SG_ CA_shutdownReason m4: 58|3@1+ (1,0) [0|0] "" X

BO_ 593 CHADA_status_2: 8 ETH
 SG_ CA_status2DataSelect M: 0|7@1+ (1,0) [0|0] "" X
 SG_ CA_status2DummySig: 7|1@1+ (1,0) [0|0] "" X
 SG_ CA_VEH_Ext_Protocol_Ver m0: 8|8@1+ (1,0) [0|0] "" X
 SG_ CA_EVSE_Ext_Protocol_Ver m0: 16|8@1+ (1,0) [0|0] "" X
 SG_ CA_FC_protocolVersion m0: 24|8@1+ (1,0) [0|0] "" X
 SG_ CA_BMS_protocolVersion m0: 32|8@1+ (1,0) [0|0] "" X
 SG_ CA_VEH_BAT_V_Target m0: 40|16@1+ (1,0) [0|0] "V" X
 SG_ CA_VEH_BAT_SOC m0: 56|8@1+ (0.392157,0) [0|0] "%" X
 SG_ CA_EVSE_Threshold_V m1: 8|16@1+ (1,0) [0|0] "A" X
 SG_ CA_EVSE_Avail_V_Out m1: 24|16@1+ (1,0) [0|0] "V" X
 SG_ CA_EVSE_Avail_I_Out m1: 40|8@1+ (1,0) [0|0] "A" X
 SG_ CA_flybackVoltageLimit m1: 48|16@1+ (0.0128333,0) [0|0] "V" X
 SG_ CA_vehConnTempDegC m2: 8|16@1- (0.00457771,0) [0|0] "C" X
 SG_ CA_evseConnTempDegC m2: 24|16@1- (0.00457771,0) [0|0] "C" X
 SG_ CA_pcbaTempDegC m2: 40|16@1- (0.0100711,25) [0|0] "C" X
 SG_ CA_vehConnTempV m3: 8|16@1+ (5.03548e-05,0) [0|0] "V" X
 SG_ CA_evseConnTempV m3: 24|16@1+ (5.03548e-05,0) [0|0] "V" X
 SG_ CA_pcbaTempV m3: 40|16@1+ (5.03548e-05,0) [0|0] "V" X

BO_ 1335 CHGPH1_info: 8 ETH
 SG_ CHGPH1_infoIndex M: 0|8@1+ (1,0) [0|0] "" X
 SG_ CHGPH1_infoBuildType m10: 8|8@1+ (1,0) [0|0] "" X
 SG_ CHGPH1_infoBuildConfigID m10: 16|16@1+ (1,0) [0|0] "" X
 SG_ CHGPH1_infoHardwareID m10: 32|16@1+ (1,0) [0|0] "" X
 SG_ CHGPH1_infoComponentID m10: 48|16@1+ (1,0) [0|0] "" X
 SG_ CHGPH1_infoPcbaID m11: 16|8@1+ (1,0) [0|0] "" X
 SG_ CHGPH1_infoAssemblyID m11: 24|8@1+ (1,0) [0|0] "" X
 SG_ CHGPH1_infoUsageID m11: 32|16@1+ (1,0) [0|0] "" X
 SG_ CHGPH1_infoSubUsageID m11: 48|16@1+ (1,0) [0|0] "" X
 SG_ CHGPH1_infoApplicationCRC m13: 32|32@1+ (1,0) [0|0] "" X
 SG_ CHGPH1_infoBootloaderSvnRevision m14: 8|24@1+ (1,0) [0|0] "" X
 SG_ CHGPH1_infoBootloaderCRC m15: 32|32@1+ (1,0) [0|0] "" X
 SG_ CHGPH1_infoCPLDVersionMajor m16: 16|8@1+ (1,0) [0|0] "" X
 SG_ CHGPH1_infoCPLDVersionMinor m16: 24|8@1+ (1,0) [0|0] "" X
 SG_ CHGPH1_infoAppGitHashBytes m17: 10|54@1+ (4,0) [0|0] "" X
 SG_ CHGPH1_infoBootGitHashBytes m18: 10|54@1+ (4,0) [0|0] "" X
 SG_ CHGPH1_infoPlatformType m19: 8|8@1+ (1,0) [0|0] "" X
 SG_ CHGPH1_infoMajorVersion m19: 16|8@1+ (1,0) [0|0] "" X
 SG_ CHGPH1_infoBranchOrigin m19: 24|8@1+ (1,0) [0|0] "" X
 SG_ CHGPH1_infoMaturity m19: 32|8@1+ (1,0) [0|0] "" X
 SG_ CHGPH1_infoHardwareRevision m19: 40|8@1+ (1,0) [0|0] "" X
 SG_ CHGPH1_infoBootUdsProtoVersion m20: 8|8@1+ (1,0) [0|0] "" X

BO_ 1559 CHGPH1_udsResponse: 8 ETH
 SG_ CHGPH1_udsResponseData: 0|54@0+ (1024,0) [0|0] "" X

BO_ 1337 CHGPH2_info: 8 ETH
 SG_ CHGPH2_infoIndex M: 0|8@1+ (1,0) [0|0] "" X
 SG_ CHGPH2_infoBuildType m10: 8|8@1+ (1,0) [0|0] "" X
 SG_ CHGPH2_infoBuildConfigID m10: 16|16@1+ (1,0) [0|0] "" X
 SG_ CHGPH2_infoHardwareID m10: 32|16@1+ (1,0) [0|0] "" X
 SG_ CHGPH2_infoComponentID m10: 48|16@1+ (1,0) [0|0] "" X
 SG_ CHGPH2_infoPcbaID m11: 16|8@1+ (1,0) [0|0] "" X
 SG_ CHGPH2_infoAssemblyID m11: 24|8@1+ (1,0) [0|0] "" X
 SG_ CHGPH2_infoUsageID m11: 32|16@1+ (1,0) [0|0] "" X
 SG_ CHGPH2_infoSubUsageID m11: 48|16@1+ (1,0) [0|0] "" X
 SG_ CHGPH2_infoApplicationCRC m13: 32|32@1+ (1,0) [0|0] "" X
 SG_ CHGPH2_infoBootloaderSvnRevision m14: 8|24@1+ (1,0) [0|0] "" X
 SG_ CHGPH2_infoBootloaderCRC m15: 32|32@1+ (1,0) [0|0] "" X
 SG_ CHGPH2_infoCPLDVersionMajor m16: 16|8@1+ (1,0) [0|0] "" X
 SG_ CHGPH2_infoCPLDVersionMinor m16: 24|8@1+ (1,0) [0|0] "" X
 SG_ CHGPH2_infoAppGitHashBytes m17: 10|54@1+ (4,0) [0|0] "" X
 SG_ CHGPH2_infoBootGitHashBytes m18: 10|54@1+ (4,0) [0|0] "" X
 SG_ CHGPH2_infoPlatformType m19: 8|8@1+ (1,0) [0|0] "" X
 SG_ CHGPH2_infoMajorVersion m19: 16|8@1+ (1,0) [0|0] "" X
 SG_ CHGPH2_infoBranchOrigin m19: 24|8@1+ (1,0) [0|0] "" X
 SG_ CHGPH2_infoMaturity m19: 32|8@1+ (1,0) [0|0] "" X
 SG_ CHGPH2_infoHardwareRevision m19: 40|8@1+ (1,0) [0|0] "" X
 SG_ CHGPH2_infoBootUdsProtoVersion m20: 8|8@1+ (1,0) [0|0] "" X

BO_ 1561 CHGPH2_udsResponse: 8 ETH
 SG_ CHGPH2_udsResponseData: 0|54@0+ (1024,0) [0|0] "" X

BO_ 1339 CHGPH3_info: 8 ETH
 SG_ CHGPH3_infoIndex M: 0|8@1+ (1,0) [0|0] "" X
 SG_ CHGPH3_infoBuildType m10: 8|8@1+ (1,0) [0|0] "" X
 SG_ CHGPH3_infoBuildConfigID m10: 16|16@1+ (1,0) [0|0] "" X
 SG_ CHGPH3_infoHardwareID m10: 32|16@1+ (1,0) [0|0] "" X
 SG_ CHGPH3_infoComponentID m10: 48|16@1+ (1,0) [0|0] "" X
 SG_ CHGPH3_infoPcbaID m11: 16|8@1+ (1,0) [0|0] "" X
 SG_ CHGPH3_infoAssemblyID m11: 24|8@1+ (1,0) [0|0] "" X
 SG_ CHGPH3_infoUsageID m11: 32|16@1+ (1,0) [0|0] "" X
 SG_ CHGPH3_infoSubUsageID m11: 48|16@1+ (1,0) [0|0] "" X
 SG_ CHGPH3_infoApplicationCRC m13: 32|32@1+ (1,0) [0|0] "" X
 SG_ CHGPH3_infoBootloaderSvnRevision m14: 8|24@1+ (1,0) [0|0] "" X
 SG_ CHGPH3_infoBootloaderCRC m15: 32|32@1+ (1,0) [0|0] "" X
 SG_ CHGPH3_infoCPLDVersionMajor m16: 16|8@1+ (1,0) [0|0] "" X
 SG_ CHGPH3_infoCPLDVersionMinor m16: 24|8@1+ (1,0) [0|0] "" X
 SG_ CHGPH3_infoAppGitHashBytes m17: 10|54@1+ (4,0) [0|0] "" X
 SG_ CHGPH3_infoBootGitHashBytes m18: 10|54@1+ (4,0) [0|0] "" X
 SG_ CHGPH3_infoPlatformType m19: 8|8@1+ (1,0) [0|0] "" X
 SG_ CHGPH3_infoMajorVersion m19: 16|8@1+ (1,0) [0|0] "" X
 SG_ CHGPH3_infoBranchOrigin m19: 24|8@1+ (1,0) [0|0] "" X
 SG_ CHGPH3_infoMaturity m19: 32|8@1+ (1,0) [0|0] "" X
 SG_ CHGPH3_infoHardwareRevision m19: 40|8@1+ (1,0) [0|0] "" X
 SG_ CHGPH3_infoBootUdsProtoVersion m20: 8|8@1+ (1,0) [0|0] "" X

BO_ 1563 CHGPH3_udsResponse: 8 ETH
 SG_ CHGPH3_udsResponseData: 0|54@0+ (1024,0) [0|0] "" X

BO_ 1388 CHGRLY_info: 8 ETH
 SG_ CHGRLY_infoIndex M: 0|8@1+ (1,0) [0|0] "" X
 SG_ CHGRLY_buildType m10: 8|8@1+ (1,0) [0|0] "" X
 SG_ CHGRLY_buildConfigId m10: 16|16@1+ (1,0) [0|0] "" X
 SG_ CHGRLY_hardwareId m10: 32|16@1+ (1,0) [0|0] "" X
 SG_ CHGRLY_componentId m10: 48|16@1+ (1,0) [0|0] "" X
 SG_ CHGRLY_pcbaId m11: 16|8@1+ (1,0) [0|0] "" X
 SG_ CHGRLY_assemblyId m11: 24|8@1+ (1,0) [0|0] "" X
 SG_ CHGRLY_usageId m11: 32|16@1+ (1,0) [0|0] "" X
 SG_ CHGRLY_subUsageId m11: 48|16@1+ (1,0) [0|0] "" X
 SG_ CHGRLY_platformType m13: 8|8@1+ (1,0) [0|0] "" X
 SG_ CHGRLY_appCrc m13: 32|32@1+ (1,0) [0|0] "" X
 SG_ CHGRLY_appGitHash m17: 10|54@1+ (4,0) [0|0] "" X
 SG_ CHGRLY_bootGitHash m18: 10|54@1+ (4,0) [0|0] "" X
 SG_ CHGRLY_bootUdsProtoVersion m20: 8|8@1+ (1,0) [0|0] "" X
 SG_ CHGRLY_bootCrc m20: 32|32@1+ (1,0) [0|0] "" X

BO_ 1596 CHGRLY_udsResponse: 8 ETH
 SG_ CHGRLY_udsResponseData: 0|54@0+ (1024,0) [0|0] "" X

BO_ 1463 CHGSPH1_info: 8 ETH
 SG_ CHGSPH1_infoIndex M: 0|8@1+ (1,0) [0|0] "" X
 SG_ CHGSPH1_infoBuildType m10: 8|8@1+ (1,0) [0|0] "" X
 SG_ CHGSPH1_infoBuildConfigID m10: 16|16@1+ (1,0) [0|0] "" X
 SG_ CHGSPH1_infoHardwareID m10: 32|16@1+ (1,0) [0|0] "" X
 SG_ CHGSPH1_infoComponentID m10: 48|16@1+ (1,0) [0|0] "" X
 SG_ CHGSPH1_infoPcbaID m11: 16|8@1+ (1,0) [0|0] "" X
 SG_ CHGSPH1_infoAssemblyID m11: 24|8@1+ (1,0) [0|0] "" X
 SG_ CHGSPH1_infoUsageID m11: 32|16@1+ (1,0) [0|0] "" X
 SG_ CHGSPH1_infoSubUsageID m11: 48|16@1+ (1,0) [0|0] "" X
 SG_ CHGSPH1_infoApplicationCRC m13: 32|32@1+ (1,0) [0|0] "" X
 SG_ CHGSPH1_infoBootloaderSvnRevisio m14: 8|24@1+ (1,0) [0|0] "" X
 SG_ CHGSPH1_infoBootloaderCRC m15: 32|32@1+ (1,0) [0|0] "" X
 SG_ CHGSPH1_infoCPLDVersionMajor m16: 16|8@1+ (1,0) [0|0] "" X
 SG_ CHGSPH1_infoCPLDVersionMinor m16: 24|8@1+ (1,0) [0|0] "" X
 SG_ CHGSPH1_infoAppGitHashBytes m17: 10|54@1+ (4,0) [0|0] "" X
 SG_ CHGSPH1_infoBootGitHashBytes m18: 10|54@1+ (4,0) [0|0] "" X
 SG_ CHGSPH1_infoPlatformType m19: 8|8@1+ (1,0) [0|0] "" X
 SG_ CHGSPH1_infoMajorVersion m19: 16|8@1+ (1,0) [0|0] "" X
 SG_ CHGSPH1_infoBranchOrigin m19: 24|8@1+ (1,0) [0|0] "" X
 SG_ CHGSPH1_infoMaturity m19: 32|8@1+ (1,0) [0|0] "" X
 SG_ CHGSPH1_infoHardwareRevision m19: 40|8@1+ (1,0) [0|0] "" X
 SG_ CHGSPH1_infoBootUdsProtoVersion m20: 8|8@1+ (1,0) [0|0] "" X

BO_ 1687 CHGSPH1_udsResponse: 8 ETH
 SG_ CHGSPH1_udsResponseData: 0|54@0+ (1024,0) [0|0] "" X

BO_ 1465 CHGSPH2_info: 8 ETH
 SG_ CHGSPH2_infoIndex M: 0|8@1+ (1,0) [0|0] "" X
 SG_ CHGSPH2_infoBuildType m10: 8|8@1+ (1,0) [0|0] "" X
 SG_ CHGSPH2_infoBuildConfigID m10: 16|16@1+ (1,0) [0|0] "" X
 SG_ CHGSPH2_infoHardwareID m10: 32|16@1+ (1,0) [0|0] "" X
 SG_ CHGSPH2_infoComponentID m10: 48|16@1+ (1,0) [0|0] "" X
 SG_ CHGSPH2_infoPcbaID m11: 16|8@1+ (1,0) [0|0] "" X
 SG_ CHGSPH2_infoAssemblyID m11: 24|8@1+ (1,0) [0|0] "" X
 SG_ CHGSPH2_infoUsageID m11: 32|16@1+ (1,0) [0|0] "" X
 SG_ CHGSPH2_infoSubUsageID m11: 48|16@1+ (1,0) [0|0] "" X
 SG_ CHGSPH2_infoApplicationCRC m13: 32|32@1+ (1,0) [0|0] "" X
 SG_ CHGSPH2_infoBootloaderSvnRevisio m14: 8|24@1+ (1,0) [0|0] "" X
 SG_ CHGSPH2_infoBootloaderCRC m15: 32|32@1+ (1,0) [0|0] "" X
 SG_ CHGSPH2_infoCPLDVersionMajor m16: 16|8@1+ (1,0) [0|0] "" X
 SG_ CHGSPH2_infoCPLDVersionMinor m16: 24|8@1+ (1,0) [0|0] "" X
 SG_ CHGSPH2_infoAppGitHashBytes m17: 10|54@1+ (4,0) [0|0] "" X
 SG_ CHGSPH2_infoBootGitHashBytes m18: 10|54@1+ (4,0) [0|0] "" X
 SG_ CHGSPH2_infoPlatformType m19: 8|8@1+ (1,0) [0|0] "" X
 SG_ CHGSPH2_infoMajorVersion m19: 16|8@1+ (1,0) [0|0] "" X
 SG_ CHGSPH2_infoBranchOrigin m19: 24|8@1+ (1,0) [0|0] "" X
 SG_ CHGSPH2_infoMaturity m19: 32|8@1+ (1,0) [0|0] "" X
 SG_ CHGSPH2_infoHardwareRevision m19: 40|8@1+ (1,0) [0|0] "" X
 SG_ CHGSPH2_infoBootUdsProtoVersion m20: 8|8@1+ (1,0) [0|0] "" X

BO_ 1565 CHGSPH2_udsResponse: 8 ETH
 SG_ CHGSPH2_udsResponseData: 0|54@0+ (1024,0) [0|0] "" X

BO_ 1467 CHGSPH3_info: 8 ETH
 SG_ CHGSPH3_infoIndex M: 0|8@1+ (1,0) [0|0] "" X
 SG_ CHGSPH3_infoBuildType m10: 8|8@1+ (1,0) [0|0] "" X
 SG_ CHGSPH3_infoBuildConfigID m10: 16|16@1+ (1,0) [0|0] "" X
 SG_ CHGSPH3_infoHardwareID m10: 32|16@1+ (1,0) [0|0] "" X
 SG_ CHGSPH3_infoComponentID m10: 48|16@1+ (1,0) [0|0] "" X
 SG_ CHGSPH3_infoPcbaID m11: 16|8@1+ (1,0) [0|0] "" X
 SG_ CHGSPH3_infoAssemblyID m11: 24|8@1+ (1,0) [0|0] "" X
 SG_ CHGSPH3_infoUsageID m11: 32|16@1+ (1,0) [0|0] "" X
 SG_ CHGSPH3_infoSubUsageID m11: 48|16@1+ (1,0) [0|0] "" X
 SG_ CHGSPH3_infoApplicationCRC m13: 32|32@1+ (1,0) [0|0] "" X
 SG_ CHGSPH3_infoBootloaderSvnRevisio m14: 8|24@1+ (1,0) [0|0] "" X
 SG_ CHGSPH3_infoBootloaderCRC m15: 32|32@1+ (1,0) [0|0] "" X
 SG_ CHGSPH3_infoCPLDVersionMajor m16: 16|8@1+ (1,0) [0|0] "" X
 SG_ CHGSPH3_infoCPLDVersionMinor m16: 24|8@1+ (1,0) [0|0] "" X
 SG_ CHGSPH3_infoAppGitHashBytes m17: 10|54@1+ (4,0) [0|0] "" X
 SG_ CHGSPH3_infoBootGitHashBytes m18: 10|54@1+ (4,0) [0|0] "" X
 SG_ CHGSPH3_infoPlatformType m19: 8|8@1+ (1,0) [0|0] "" X
 SG_ CHGSPH3_infoMajorVersion m19: 16|8@1+ (1,0) [0|0] "" X
 SG_ CHGSPH3_infoBranchOrigin m19: 24|8@1+ (1,0) [0|0] "" X
 SG_ CHGSPH3_infoMaturity m19: 32|8@1+ (1,0) [0|0] "" X
 SG_ CHGSPH3_infoHardwareRevision m19: 40|8@1+ (1,0) [0|0] "" X
 SG_ CHGSPH3_infoBootUdsProtoVersion m20: 8|8@1+ (1,0) [0|0] "" X

BO_ 1691 CHGSPH3_udsResponse: 8 ETH
 SG_ CHGSPH3_udsResponseData: 0|54@0+ (1024,0) [0|0] "" X

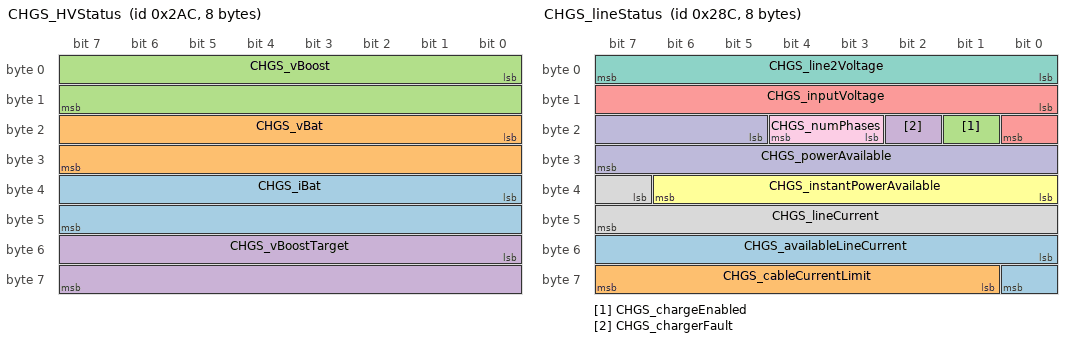
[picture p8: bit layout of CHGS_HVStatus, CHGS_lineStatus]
BO_ 684 CHGS_HVStatus: 8 ETH
 SG_ CHGS_iBat: 32|16@1+ (0.00126648,0) [0|0] "A" X
 SG_ CHGS_vBat: 16|16@1+ (0.0105286,0) [0|0] "V" X
 SG_ CHGS_vBoost: 0|16@1+ (0.00762939,0) [0|0] "V" X
 SG_ CHGS_vBoostTarget: 48|16@1+ (0.00762939,0) [0|0] "V" X

BO_ 956 CHGS_dtcMatrix: 8 ETH
 SG_ CHGS_dtcIndex M: 0|8@1+ (1,0) [0|0] "" X
 SG_ CHGS_d001_replaceCharger m0: 8|2@1+ (1,0) [0|0] "" X
 SG_ CHGS_d002_12VOV m0: 10|2@1+ (1,0) [0|0] "" X
 SG_ CHGS_d003_12VUV m0: 12|2@1+ (1,0) [0|0] "" X
 SG_ CHGS_d004_overTemp m0: 14|2@1+ (1,0) [0|0] "" X
 SG_ CHGS_d005_lowFlow m0: 16|2@1+ (1,0) [0|0] "" X
 SG_ CHGS_d006_HVUV m0: 18|2@1+ (1,0) [0|0] "" X
 SG_ CHGS_d007_FCFuseBlown m0: 20|2@1+ (1,0) [0|0] "" X
 SG_ CHGS_d008_FCWeld m0: 22|2@1+ (1,0) [0|0] "" X
 SG_ CHGS_d009_FCWontClose m0: 24|2@1+ (1,0) [0|0] "" X
 SG_ CHGS_d010_FCCnctrPower m0: 26|2@1+ (1,0) [0|0] "" X
 SG_ CHGS_d011_proxRationality m0: 28|2@1+ (1,0) [0|0] "" X
 SG_ CHGS_d012_lostComms m0: 30|2@1+ (1,0) [0|0] "" X
 SG_ CHGS_d013_HVIL m0: 32|2@1+ (1,0) [0|0] "" X
 SG_ CHGS_d014_15VUV m0: 34|2@1+ (1,0) [0|0] "" X
 SG_ CHGS_d015_unused m0: 36|2@1+ (1,0) [0|0] "" X
 SG_ CHGS_d016_unused m0: 38|2@1+ (1,0) [0|0] "" X
 SG_ CHGS_d017_unused m0: 40|2@1+ (1,0) [0|0] "" X
 SG_ CHGS_d018_unused m0: 42|2@1+ (1,0) [0|0] "" X
 SG_ CHGS_d019_unused m0: 44|2@1+ (1,0) [0|0] "" X
 SG_ CHGS_d020_unused m0: 46|2@1+ (1,0) [0|0] "" X
 SG_ CHGS_d021_unused m0: 48|2@1+ (1,0) [0|0] "" X
 SG_ CHGS_d022_unused m0: 50|2@1+ (1,0) [0|0] "" X
 SG_ CHGS_d023_unused m0: 52|2@1+ (1,0) [0|0] "" X
 SG_ CHGS_d024_unused m0: 54|2@1+ (1,0) [0|0] "" X
 SG_ CHGS_d025_unused m0: 56|2@1+ (1,0) [0|0] "" X
 SG_ CHGS_d026_unused m0: 58|2@1+ (1,0) [0|0] "" X
 SG_ CHGS_d027_unused m0: 60|2@1+ (1,0) [0|0] "" X
 SG_ CHGS_d028_unused m0: 62|2@1+ (1,0) [0|0] "" X

BO_ 66 CHGS_faultMatrix1: 8 ETH
 SG_ CHGS_f001_hwBuck: 0|1@1+ (1,0) [0|0] "" X
 SG_ CHGS_f002_hwBoost: 1|1@1+ (1,0) [0|0] "" X
 SG_ CHGS_f003_hwBiasBoost: 2|1@1+ (1,0) [0|0] "" X
 SG_ CHGS_f004_hwBiasBuck: 3|1@1+ (1,0) [0|0] "" X
 SG_ CHGS_f005_hwXfrmrOC: 4|1@1+ (1,0) [0|0] "" X
 SG_ CHGS_f006_hwBoost1OC: 5|1@1+ (1,0) [0|0] "" X
 SG_ CHGS_f007_hwBoost2OC: 6|1@1+ (1,0) [0|0] "" X
 SG_ CHGS_f008_hwThermal1: 7|1@1+ (1,0) [0|0] "" X
 SG_ CHGS_f009_hwFCWeld: 8|1@1+ (1,0) [0|0] "" X
 SG_ CHGS_f010_hwIllegalFCRequest: 9|1@1+ (1,0) [0|0] "" X
 SG_ CHGS_f011_hwVInOV: 10|1@1+ (1,0) [0|0] "" X
 SG_ CHGS_f012_hwFastChargeDriver: 11|1@1+ (1,0) [0|0] "" X
 SG_ CHGS_f013_hwIllegalInletRequest: 12|1@1+ (1,0) [0|0] "" X
 SG_ CHGS_f014_hwThermal2: 13|1@1+ (1,0) [0|0] "" X
 SG_ CHGS_f015_hwAntispark: 14|1@1+ (1,0) [0|0] "" X
 SG_ CHGS_f016_hwVOutOV: 15|1@1+ (1,0) [0|0] "" X
 SG_ CHGS_f017_hwIntermediateBus: 16|1@1+ (1,0) [0|0] "" X
 SG_ CHGS_f018_hwLineOC: 17|1@1+ (1,0) [0|0] "" X
 SG_ CHGS_f019_hwIBatOC: 18|1@1+ (1,0) [0|0] "" X
 SG_ CHGS_f020_hwHVIL: 19|1@1+ (1,0) [0|0] "" X
 SG_ CHGS_f021_15V: 20|1@1+ (1,0) [0|0] "" X
 SG_ CHGS_f022_hw12VUV: 21|1@1+ (1,0) [0|0] "" X
 SG_ CHGS_f023_hwReset: 22|1@1+ (1,0) [0|0] "" X
 SG_ CHGS_f024_VLineOVPk: 23|1@1+ (1,0) [0|0] "" X
 SG_ CHGS_f025_VLineUV: 24|1@1+ (1,0) [0|0] "" X
 SG_ CHGS_f026_VOutOV: 25|1@1+ (1,0) [0|0] "" X
 SG_ CHGS_f027_VOutUV: 26|1@1+ (1,0) [0|0] "" X
 SG_ CHGS_f028_igbtOT: 27|1@1+ (1,0) [0|0] "" X
 SG_ CHGS_f029_ambientOT: 28|1@1+ (1,0) [0|0] "" X
 SG_ CHGS_f030_VLineFreqOF: 29|1@1+ (1,0) [0|0] "" X
 SG_ CHGS_f031_VLineFreqUF: 30|1@1+ (1,0) [0|0] "" X
 SG_ CHGS_f032_pllSyncLoss: 31|1@1+ (1,0) [0|0] "" X
 SG_ CHGS_f033_pilotFaulted: 32|1@1+ (1,0) [0|0] "" X
 SG_ CHGS_f034_swHVIL: 33|1@1+ (1,0) [0|0] "" X
 SG_ CHGS_f035_pilotRationality: 34|1@1+ (1,0) [0|0] "" X
 SG_ CHGS_f036_unused: 35|1@1+ (1,0) [0|0] "" X
 SG_ CHGS_f037_recOT: 36|1@1+ (1,0) [0|0] "" X
 SG_ CHGS_f038_buckOT: 37|1@1+ (1,0) [0|0] "" X
 SG_ CHGS_f039_12V: 38|1@1+ (1,0) [0|0] "" X
 SG_ CHGS_f040_lostCommsGTW: 39|1@1+ (1,0) [0|0] "" X
 SG_ CHGS_f041_lostCommsBMS: 40|1@1+ (1,0) [0|0] "" X
 SG_ CHGS_f042_lostCommsCP: 41|1@1+ (1,0) [0|0] "" X
 SG_ CHGS_f043_canRationality: 42|1@1+ (1,0) [0|0] "" X
 SG_ CHGS_f044_lostCommsVI: 43|1@1+ (1,0) [0|0] "" X
 SG_ CHGS_f045_invalidState: 44|1@1+ (1,0) [0|0] "" X
 SG_ CHGS_f046_movingInCharge: 45|1@1+ (1,0) [0|0] "" X
 SG_ CHGS_f047_HVJB_groundLoss: 46|1@1+ (1,0) [0|0] "" X
 SG_ CHGS_f048_FCWeldCheckState: 47|1@1+ (1,0) [0|0] "" X
 SG_ CHGS_f049_invalidChargeReq: 48|1@1+ (1,0) [0|0] "" X
 SG_ CHGS_f050_invalidStateChng: 49|1@1+ (1,0) [0|0] "" X
 SG_ CHGS_f051_FCStateFault: 50|1@1+ (1,0) [0|0] "" X
 SG_ CHGS_f052_memoryError: 51|1@1+ (1,0) [0|0] "" X
 SG_ CHGS_f053_networkManagement: 52|1@1+ (1,0) [0|0] "" X
 SG_ CHGS_f054_interruptTime: 53|1@1+ (1,0) [0|0] "" X
 SG_ CHGS_f055_VLineDischarge: 54|1@1+ (1,0) [0|0] "" X
 SG_ CHGS_f056_5VPower: 55|1@1+ (1,0) [0|0] "" X
 SG_ CHGS_f057_VLineOV: 56|1@1+ (1,0) [0|0] "" X
 SG_ CHGS_f058_watchdogreset: 57|1@1+ (1,0) [0|0] "" X
 SG_ CHGS_f059_SWCANError: 58|1@1+ (1,0) [0|0] "" X
 SG_ CHGS_f060_FCCntrVcheck: 59|1@1+ (1,0) [0|0] "" X
 SG_ CHGS_f061_FCAuxCntrRationality: 60|1@1+ (1,0) [0|0] "" X
 SG_ CHGS_f062_FCPosCntrWelded: 61|1@1+ (1,0) [0|0] "" X
 SG_ CHGS_f063_FCNegCntrWelded: 62|1@1+ (1,0) [0|0] "" X
 SG_ CHGS_f064_prechargeRelayWelded: 63|1@1+ (1,0) [0|0] "" X

BO_ 67 CHGS_faultMatrix2: 8 ETH
 SG_ CHGS_f065_FCCntrRationalitycheck: 0|1@1+ (1,0) [0|0] "" X
 SG_ CHGS_f066_unexpectedVintBehavior: 1|1@1+ (1,0) [0|0] "" X
 SG_ CHGS_f067_line2OV: 2|1@1+ (1,0) [0|0] "" X
 SG_ CHGS_f068_heatsinkTempSlope: 3|1@1+ (1,0) [0|0] "" X
 SG_ CHGS_f069_igbtTempSlope: 4|1@1+ (1,0) [0|0] "" X
 SG_ CHGS_f070_heatsinkOT: 5|1@1+ (1,0) [0|0] "" X
 SG_ CHGS_f071_chargeThermalLimit: 6|1@1+ (1,0) [0|0] "" X
 SG_ CHGS_f072_assertion: 7|1@1+ (1,0) [0|0] "" X
 SG_ CHGS_f073_unexpectedVoutBehavior: 8|1@1+ (1,0) [0|0] "" X
 SG_ CHGS_f074_cpldFaulted: 9|1@1+ (1,0) [0|0] "" X
 SG_ CHGS_f075_stateTransitionDenied: 10|1@1+ (1,0) [0|0] "" X
 SG_ CHGS_f076_iLineOCPk: 11|1@1+ (1,0) [0|0] "" X
 SG_ CHGS_f077_iLineOCRMS: 12|1@1+ (1,0) [0|0] "" X
 SG_ CHGS_f078_boostPrechargeFail: 13|1@1+ (1,0) [0|0] "" X
 SG_ CHGS_f079_GFCI: 14|1@1+ (1,0) [0|0] "" X
 SG_ CHGS_f080_vIntOutofRange: 15|1@1+ (1,0) [0|0] "" X
 SG_ CHGS_f081_iacRegulation: 16|1@1+ (1,0) [0|0] "" X
 SG_ CHGS_f082_vIntRegulation: 17|1@1+ (1,0) [0|0] "" X
 SG_ CHGS_f083_allPhasesFaulted: 18|1@1+ (1,0) [0|0] "" X
 SG_ CHGS_f084_vOutRegulation: 19|1@1+ (1,0) [0|0] "" X
 SG_ CHGS_f085_adcReference: 20|1@1+ (1,0) [0|0] "" X
 SG_ CHGS_f086_CPLDInhibEVSEAccept: 21|1@1+ (1,0) [0|0] "" X
 SG_ CHGS_f087_inputRelayRationalty: 22|1@1+ (1,0) [0|0] "" X
 SG_ CHGS_f088_lostCommsChgrly: 23|1@1+ (1,0) [0|0] "" X
 SG_ CHGS_f089_iLineRationality: 24|1@1+ (1,0) [0|0] "" X
 SG_ CHGS_f090_vLineRationality: 25|1@1+ (1,0) [0|0] "" X
 SG_ CHGS_f091_proximityRationality: 26|1@1+ (1,0) [0|0] "" X
 SG_ CHGS_f092_vOutRationality: 27|1@1+ (1,0) [0|0] "" X
 SG_ CHGS_f093_vIntRationality: 28|1@1+ (1,0) [0|0] "" X
 SG_ CHGS_f094_igbtTempRationality: 29|1@1+ (1,0) [0|0] "" X
 SG_ CHGS_f095_htsinkTempRationality: 30|1@1+ (1,0) [0|0] "" X
 SG_ CHGS_f096_ambientTempRationality: 31|1@1+ (1,0) [0|0] "" X
 SG_ CHGS_f097_hvilRationality: 32|1@1+ (1,0) [0|0] "" X
 SG_ CHGS_f098_iOutRationality: 33|1@1+ (1,0) [0|0] "" X
 SG_ CHGS_f099_noFlowDetected: 34|1@1+ (1,0) [0|0] "" X
 SG_ CHGS_f100_hw15VUV: 35|1@1+ (1,0) [0|0] "" X
 SG_ CHGS_f101_lostCommsPhase: 36|1@1+ (1,0) [0|0] "" X
 SG_ CHGS_f102_lostCommsMaster: 37|1@1+ (1,0) [0|0] "" X
 SG_ CHGS_f103_lostCommsSlave: 38|1@1+ (1,0) [0|0] "" X
 SG_ CHGS_f104_magneticsOT: 39|1@1+ (1,0) [0|0] "" X
 SG_ CHGS_f105_magTempRationality: 40|1@1+ (1,0) [0|0] "" X
 SG_ CHGS_f106_gfciRationality: 41|1@1+ (1,0) [0|0] "" X
 SG_ CHGS_f107_cpldRationality: 42|1@1+ (1,0) [0|0] "" X
 SG_ CHGS_f108_cpCoverOpen: 43|1@1+ (1,0) [0|0] "" X
 SG_ CHGS_f109_resetAttemptInEnable: 44|1@1+ (1,0) [0|0] "" X
 SG_ CHGS_f110_busOff: 45|1@1+ (1,0) [0|0] "" X
 SG_ CHGS_f111_AttemptToFastCharge: 46|1@1+ (1,0) [0|0] "" X
 SG_ CHGS_f112_packConfig: 47|1@1+ (1,0) [0|0] "" X
 SG_ CHGS_f113_eepromError: 48|1@1+ (1,0) [0|0] "" X
 SG_ CHGS_f114_phEnRationality: 49|1@1+ (1,0) [0|0] "" X
 SG_ CHGS_f115_chargerConfig: 50|1@1+ (1,0) [0|0] "" X
 SG_ CHGS_f116_HVJBOT: 51|1@1+ (1,0) [0|0] "" X
 SG_ CHGS_f117_HVJBOTFault: 52|1@1+ (1,0) [0|0] "" X
 SG_ CHGS_f118_VDiffHwRationality: 53|1@1+ (1,0) [0|0] "" X
 SG_ CHGS_f119_FCNotClosed: 54|1@1+ (1,0) [0|0] "" X
 SG_ CHGS_f120_unused: 55|1@1+ (1,0) [0|0] "" X
 SG_ CHGS_f121_crashDetected: 56|1@1+ (1,0) [0|0] "" X
 SG_ CHGS_f122_dioRationality: 57|1@1+ (1,0) [0|0] "" X
 SG_ CHGS_f123_liveCableDisconnect: 58|1@1+ (1,0) [0|0] "" X
 SG_ CHGS_f124_ph3VersionMismatch: 59|1@1+ (1,0) [0|0] "" X
 SG_ CHGS_f125_leakageTestFailure: 60|1@1+ (1,0) [0|0] "" X
 SG_ CHGS_f126_allPhasesMIA: 61|1@1+ (1,0) [0|0] "" X
 SG_ CHGS_f127_hvCableBadPolarity: 62|1@1+ (1,0) [0|0] "" X
 SG_ CHGS_f128_leakageTestLow: 63|1@1+ (1,0) [0|0] "" X

BO_ 1468 CHGS_info: 8 ETH
 SG_ CHGS_infoIndex M: 0|8@1+ (1,0) [0|0] "" X
 SG_ CHGS_infoBuildType m10: 8|8@1+ (1,0) [0|0] "" X
 SG_ CHGS_infoBuildConfigID m10: 16|16@1+ (1,0) [0|0] "" X
 SG_ CHGS_infoHardwareID m10: 32|16@1+ (1,0) [0|0] "" X
 SG_ CHGS_infoComponentID m10: 48|16@1+ (1,0) [0|0] "" X
 SG_ CHGS_infoPcbaID m11: 16|8@1+ (1,0) [0|0] "" X
 SG_ CHGS_infoAssemblyID m11: 24|8@1+ (1,0) [0|0] "" X
 SG_ CHGS_infoUsageID m11: 32|16@1+ (1,0) [0|0] "" X
 SG_ CHGS_infoSubUsageID m11: 48|16@1+ (1,0) [0|0] "" X
 SG_ CHGS_infoApplicationCRC m13: 32|32@1+ (1,0) [0|0] "" X
 SG_ CHGS_infoBootloaderSvnRevision m14: 8|24@1+ (1,0) [0|0] "" X
 SG_ CHGS_infoBootloaderCRC m15: 32|32@1+ (1,0) [0|0] "" X
 SG_ CHGS_infoCPLDVersionMajor m16: 16|8@1+ (1,0) [0|0] "" X
 SG_ CHGS_infoCPLDVersionMinor m16: 24|8@1+ (1,0) [0|0] "" X
 SG_ CHGS_infoAppGitHashBytes m17: 10|54@1+ (4,0) [0|0] "" X
 SG_ CHGS_infoBootGitHashBytes m18: 10|54@1+ (4,0) [0|0] "" X
 SG_ CHGS_infoPlatformType m19: 8|8@1+ (1,0) [0|0] "" X
 SG_ CHGS_infoMajorVersion m19: 16|8@1+ (1,0) [0|0] "" X
 SG_ CHGS_infoBranchOrigin m19: 24|8@1+ (1,0) [0|0] "" X
 SG_ CHGS_infoMaturity m19: 32|8@1+ (1,0) [0|0] "" X
 SG_ CHGS_infoHardwareRevision m19: 40|8@1+ (1,0) [0|0] "" X
 SG_ CHGS_infoBootUdsProtoVersion m20: 8|8@1+ (1,0) [0|0] "" X

BO_ 652 CHGS_lineStatus: 8 ETH
 SG_ CHGS_availableLineCurrent: 48|9@1+ (0.16666,0) [0|0] "A" X
 SG_ CHGS_cableCurrentLimit: 57|7@1+ (1,0) [0|0] "A" X
 SG_ CHGS_chargeEnabled: 17|1@1+ (1,0) [0|0] "" X
 SG_ CHGS_chargerFault: 18|1@1+ (1,0) [0|0] "" X
 SG_ CHGS_inputVoltage: 8|9@1+ (1,0) [0|0] "V" X
 SG_ CHGS_instantPowerAvailable: 32|7@1+ (0.2,0) [0|0] "kW" X
 SG_ CHGS_line2Voltage: 0|8@1+ (2,0) [0|0] "V" X
 SG_ CHGS_lineCurrent: 39|9@1+ (0.16666,0) [0|0] "A" X
 SG_ CHGS_numPhases: 19|2@1+ (1,0) [0|0] "" X
 SG_ CHGS_powerAvailable: 21|11@1+ (0.01,0) [0|0] "kW" X

BO_ 668 CHGS_status: 8 ETH
 SG_ CHGS_GFCICurrent: 48|7@1+ (0.4,0) [0|0] "mA" X
 SG_ CHGS_cableState: 26|2@1+ (1,0) [0|0] "" X
 SG_ CHGS_cableType: 24|2@1+ (1,0) [0|0] "" X
 SG_ CHGS_evseAccept: 0|1@1+ (1,0) [0|0] "" X
 SG_ CHGS_evseRequest: 1|1@1+ (1,0) [0|0] "" X
 SG_ CHGS_lineChgShuttingDown: 28|1@1+ (1,0) [0|0] "" X
 SG_ CHGS_mainState: 4|4@1+ (1,0) [0|0] "" X
 SG_ CHGS_maxLineCurrent: 55|7@1+ (1,0) [0|0] "A" X
 SG_ CHGS_phaseConfig: 29|3@1+ (1,0) [0|0] "" X
 SG_ CHGS_pilot: 13|3@1+ (1,0) [0|0] "" X
 SG_ CHGS_pilotCurrent: 16|8@1+ (0.5,0) [0|0] "A" X
 SG_ CHGS_proximity: 11|2@1+ (1,0) [0|0] "" X
 SG_ CHGS_proximitySimUnlatched: 10|1@1+ (1,0) [0|0] "" X
 SG_ CHGS_requestHVACPowerOn: 9|1@1+ (1,0) [0|0] "" X
 SG_ CHGS_retryCount: 2|2@1+ (1,0) [0|0] "" X
 SG_ CHGS_subState: 40|6@1+ (1,0) [0|0] "" X
 SG_ CHGS_v12V: 32|8@1+ (0.1,0) [0|0] "V" X
 SG_ CHGS_voltageLimitAchieved: 8|1@1+ (1,0) [0|0] "" X
 SG_ CHGS_waveformDataReady: 46|1@1+ (1,0) [0|0] "" X

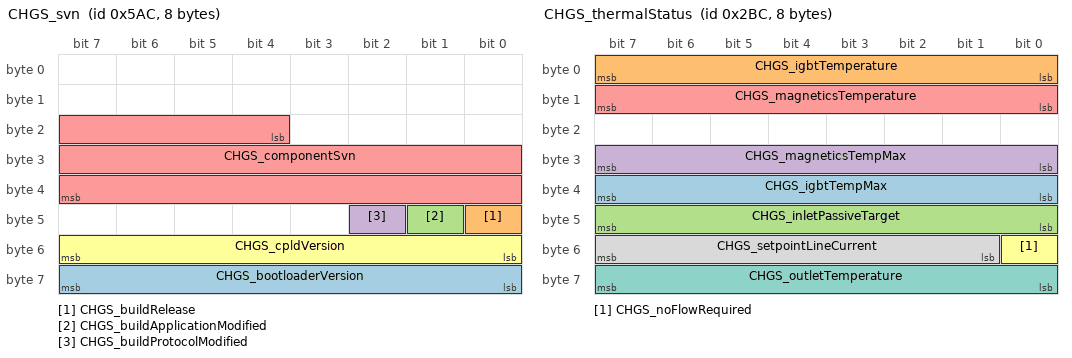
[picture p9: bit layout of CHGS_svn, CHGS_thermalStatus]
BO_ 1452 CHGS_svn: 8 ETH
 SG_ CHGS_bootloaderVersion: 56|8@1+ (1,0) [0|0] "" X
 SG_ CHGS_buildRelease: 40|1@1+ (1,0) [0|0] "" X
 SG_ CHGS_buildApplicationModified: 41|1@1+ (1,0) [0|0] "" X
 SG_ CHGS_buildProtocolModified: 42|1@1+ (1,0) [0|0] "" X
 SG_ CHGS_componentSvn: 20|20@1+ (1,0) [0|0] "" X
 SG_ CHGS_cpldVersion: 48|8@1+ (1,0) [0|0] "" X

BO_ 700 CHGS_thermalStatus: 8 ETH
 SG_ CHGS_igbtTempMax: 32|8@1+ (1,-40) [0|0] "C" X
 SG_ CHGS_igbtTemperature: 0|8@1+ (1,-40) [0|0] "C" X
 SG_ CHGS_inletPassiveTarget: 40|8@1+ (1,-40) [0|0] "C" X
 SG_ CHGS_magneticsTempMax: 24|8@1+ (1,-40) [0|0] "C" X
 SG_ CHGS_magneticsTemperature: 8|8@1+ (1,-40) [0|0] "C" X
 SG_ CHGS_noFlowRequired: 48|1@1+ (1,0) [0|0] "" X
 SG_ CHGS_outletTemperature: 56|8@1+ (1,-40) [0|0] "C" X
 SG_ CHGS_setpointLineCurrent: 49|7@1+ (1,0) [0|0] "A" X

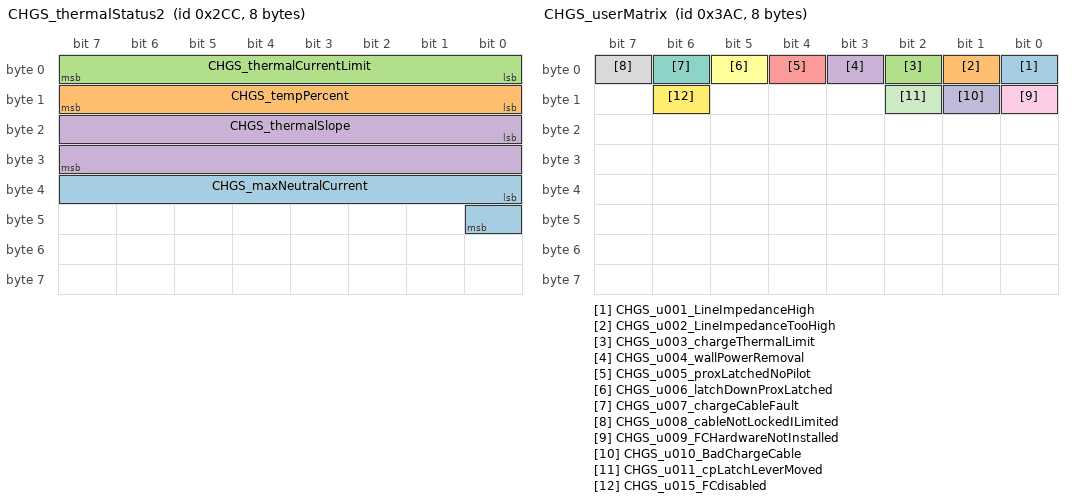
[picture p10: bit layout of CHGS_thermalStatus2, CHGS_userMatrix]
BO_ 716 CHGS_thermalStatus2: 8 ETH
 SG_ CHGS_maxNeutralCurrent: 32|9@1+ (0.16666,0) [0|0] "A" X
 SG_ CHGS_tempPercent: 8|8@1+ (0.4,0) [0|0] "%" X
 SG_ CHGS_thermalCurrentLimit: 0|8@1+ (0.234375,0) [0|0] "A" X
 SG_ CHGS_thermalSlope: 16|16@1- (0.001,0) [0|0] "degC/sec" X

BO_ 1692 CHGS_udsResponse: 8 ETH
 SG_ CHGS_udsResponseData: 0|54@0+ (1024,0) [0|0] "" X

BO_ 940 CHGS_userMatrix: 8 ETH
 SG_ CHGS_u001_LineImpedanceHigh: 0|1@1+ (1,0) [0|0] "" X
 SG_ CHGS_u002_LineImpedanceTooHigh: 1|1@1+ (1,0) [0|0] "" X
 SG_ CHGS_u003_chargeThermalLimit: 2|1@1+ (1,0) [0|0] "" X
 SG_ CHGS_u004_wallPowerRemoval: 3|1@1+ (1,0) [0|0] "" X
 SG_ CHGS_u005_proxLatchedNoPilot: 4|1@1+ (1,0) [0|0] "" X
 SG_ CHGS_u006_latchDownProxLatched: 5|1@1+ (1,0) [0|0] "" X
 SG_ CHGS_u007_chargeCableFault: 6|1@1+ (1,0) [0|0] "" X
 SG_ CHGS_u008_cableNotLockedILimited: 7|1@1+ (1,0) [0|0] "" X
 SG_ CHGS_u009_FCHardwareNotInstalled: 8|1@1+ (1,0) [0|0] "" X
 SG_ CHGS_u010_BadChargeCable: 9|1@1+ (1,0) [0|0] "" X
 SG_ CHGS_u011_cpLatchLeverMoved: 10|1@1+ (1,0) [0|0] "" X
 SG_ CHGS_u015_FCdisabled: 14|1@1+ (1,0) [0|0] "" X

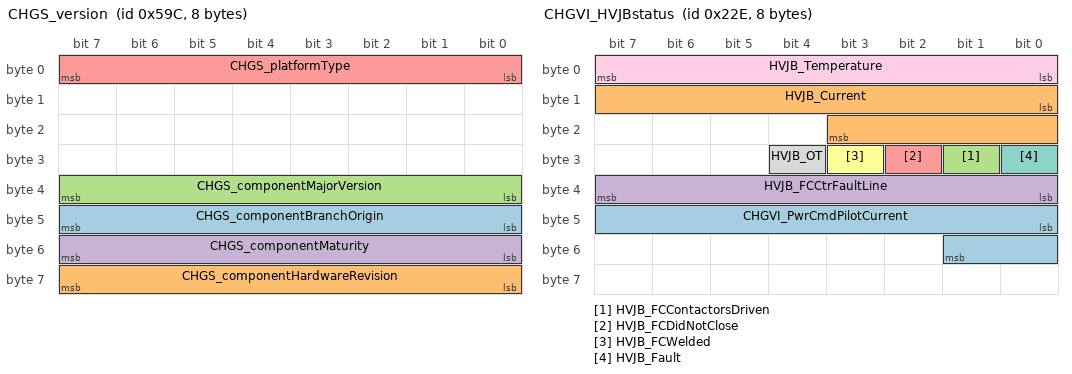
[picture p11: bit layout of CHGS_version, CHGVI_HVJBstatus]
BO_ 1436 CHGS_version: 8 ETH
 SG_ CHGS_componentBranchOrigin: 40|8@1+ (1,0) [0|0] "" X
 SG_ CHGS_componentHardwareRevision: 56|8@1+ (1,0) [0|0] "" X
 SG_ CHGS_componentMajorVersion: 32|8@1+ (1,0) [0|0] "" X
 SG_ CHGS_componentMaturity: 48|8@1+ (1,0) [0|0] "" X
 SG_ CHGS_platformType: 0|8@1+ (1,0) [0|0] "" X

BO_ 68 CHGS_warningMatrix1: 8 ETH
 SG_ CHGS_w001_hwBuck: 0|1@1+ (1,0) [0|0] "" X
 SG_ CHGS_w002_hwBoost: 1|1@1+ (1,0) [0|0] "" X
 SG_ CHGS_w003_hwBiasBoost: 2|1@1+ (1,0) [0|0] "" X
 SG_ CHGS_w004_hwBiasBuck: 3|1@1+ (1,0) [0|0] "" X
 SG_ CHGS_w005_hwXfrmrOC: 4|1@1+ (1,0) [0|0] "" X
 SG_ CHGS_w006_hwBoost1OC: 5|1@1+ (1,0) [0|0] "" X
 SG_ CHGS_w007_hwBoost2OC: 6|1@1+ (1,0) [0|0] "" X
 SG_ CHGS_w008_hwThermal1: 7|1@1+ (1,0) [0|0] "" X
 SG_ CHGS_w009_hwFCWeld: 8|1@1+ (1,0) [0|0] "" X
 SG_ CHGS_w010_hwIllegalFCRequest: 9|1@1+ (1,0) [0|0] "" X
 SG_ CHGS_w011_hwVInOV: 10|1@1+ (1,0) [0|0] "" X
 SG_ CHGS_w012_hwFastChargeDriver: 11|1@1+ (1,0) [0|0] "" X
 SG_ CHGS_w013_hwIllegalInletRequest: 12|1@1+ (1,0) [0|0] "" X
 SG_ CHGS_w014_hwThermal2: 13|1@1+ (1,0) [0|0] "" X
 SG_ CHGS_w015_hwAntispark: 14|1@1+ (1,0) [0|0] "" X
 SG_ CHGS_w016_hwVOutOV: 15|1@1+ (1,0) [0|0] "" X
 SG_ CHGS_w017_hwIntermediateBus: 16|1@1+ (1,0) [0|0] "" X
 SG_ CHGS_w018_hwLineOC: 17|1@1+ (1,0) [0|0] "" X
 SG_ CHGS_w019_hwIBatOC: 18|1@1+ (1,0) [0|0] "" X
 SG_ CHGS_w020_hwHVIL: 19|1@1+ (1,0) [0|0] "" X
 SG_ CHGS_w021_15V: 20|1@1+ (1,0) [0|0] "" X
 SG_ CHGS_w022_hw12VUV: 21|1@1+ (1,0) [0|0] "" X
 SG_ CHGS_w023_hwReset: 22|1@1+ (1,0) [0|0] "" X
 SG_ CHGS_w024_VLineOVPk: 23|1@1+ (1,0) [0|0] "" X
 SG_ CHGS_w025_VLineUV: 24|1@1+ (1,0) [0|0] "" X
 SG_ CHGS_w026_VOutOV: 25|1@1+ (1,0) [0|0] "" X
 SG_ CHGS_w027_VOutUV: 26|1@1+ (1,0) [0|0] "" X
 SG_ CHGS_w028_igbtOT: 27|1@1+ (1,0) [0|0] "" X
 SG_ CHGS_w029_ambientOT: 28|1@1+ (1,0) [0|0] "" X
 SG_ CHGS_w030_VLineFreqOF: 29|1@1+ (1,0) [0|0] "" X
 SG_ CHGS_w031_VLineFreqUF: 30|1@1+ (1,0) [0|0] "" X
 SG_ CHGS_w032_pllSyncLoss: 31|1@1+ (1,0) [0|0] "" X
 SG_ CHGS_w033_pilotFaulted: 32|1@1+ (1,0) [0|0] "" X
 SG_ CHGS_w034_swHVIL: 33|1@1+ (1,0) [0|0] "" X
 SG_ CHGS_w035_pilotRationality: 34|1@1+ (1,0) [0|0] "" X
 SG_ CHGS_w036_unused: 35|1@1+ (1,0) [0|0] "" X
 SG_ CHGS_w037_recOT: 36|1@1+ (1,0) [0|0] "" X
 SG_ CHGS_w038_buckOT: 37|1@1+ (1,0) [0|0] "" X
 SG_ CHGS_w039_12V: 38|1@1+ (1,0) [0|0] "" X
 SG_ CHGS_w040_lostCommsGTW: 39|1@1+ (1,0) [0|0] "" X
 SG_ CHGS_w041_lostCommsBMS: 40|1@1+ (1,0) [0|0] "" X
 SG_ CHGS_w042_lostCommsCP: 41|1@1+ (1,0) [0|0] "" X
 SG_ CHGS_w043_canRationality: 42|1@1+ (1,0) [0|0] "" X
 SG_ CHGS_w044_lostCommsVI: 43|1@1+ (1,0) [0|0] "" X
 SG_ CHGS_w045_invalidState: 44|1@1+ (1,0) [0|0] "" X
 SG_ CHGS_w046_movingInCharge: 45|1@1+ (1,0) [0|0] "" X
 SG_ CHGS_w047_HVJB_groundLoss: 46|1@1+ (1,0) [0|0] "" X
 SG_ CHGS_w048_FCWeldCheckState: 47|1@1+ (1,0) [0|0] "" X
 SG_ CHGS_w049_invalidChargeReq: 48|1@1+ (1,0) [0|0] "" X
 SG_ CHGS_w050_invalidStateChng: 49|1@1+ (1,0) [0|0] "" X
 SG_ CHGS_w051_FCStateFault: 50|1@1+ (1,0) [0|0] "" X
 SG_ CHGS_w052_memoryError: 51|1@1+ (1,0) [0|0] "" X
 SG_ CHGS_w053_networkManagement: 52|1@1+ (1,0) [0|0] "" X
 SG_ CHGS_w054_interruptTime: 53|1@1+ (1,0) [0|0] "" X
 SG_ CHGS_w055_VLineDischarge: 54|1@1+ (1,0) [0|0] "" X
 SG_ CHGS_w056_5VPower: 55|1@1+ (1,0) [0|0] "" X
 SG_ CHGS_w057_VLineOV: 56|1@1+ (1,0) [0|0] "" X
 SG_ CHGS_w058_watchdogreset: 57|1@1+ (1,0) [0|0] "" X
 SG_ CHGS_w059_SWCANError: 58|1@1+ (1,0) [0|0] "" X
 SG_ CHGS_w060_FCCntrVcheck: 59|1@1+ (1,0) [0|0] "" X
 SG_ CHGS_w061_FCAuxCntrRationality: 60|1@1+ (1,0) [0|0] "" X
 SG_ CHGS_w062_FCPosCntrWelded: 61|1@1+ (1,0) [0|0] "" X
 SG_ CHGS_w063_FCNegCntrWelded: 62|1@1+ (1,0) [0|0] "" X
 SG_ CHGS_w064_prechargeRelayWelded: 63|1@1+ (1,0) [0|0] "" X

BO_ 69 CHGS_warningMatrix2: 8 ETH
 SG_ CHGS_w065_FCCntrRationalitycheck: 0|1@1+ (1,0) [0|0] "" X
 SG_ CHGS_w066_unexpectedVintBehavior: 1|1@1+ (1,0) [0|0] "" X
 SG_ CHGS_w067_line2OV: 2|1@1+ (1,0) [0|0] "" X
 SG_ CHGS_w068_heatsinkTempSlope: 3|1@1+ (1,0) [0|0] "" X
 SG_ CHGS_w069_igbtTempSlope: 4|1@1+ (1,0) [0|0] "" X
 SG_ CHGS_w070_heatsinkOT: 5|1@1+ (1,0) [0|0] "" X
 SG_ CHGS_w071_chargeThermalLimit: 6|1@1+ (1,0) [0|0] "" X
 SG_ CHGS_w072_assertion: 7|1@1+ (1,0) [0|0] "" X
 SG_ CHGS_w073_unexpectedVoutBehavior: 8|1@1+ (1,0) [0|0] "" X
 SG_ CHGS_w074_cpldFaulted: 9|1@1+ (1,0) [0|0] "" X
 SG_ CHGS_w075_stateTransitionDenied: 10|1@1+ (1,0) [0|0] "" X
 SG_ CHGS_w076_iLineOCPk: 11|1@1+ (1,0) [0|0] "" X
 SG_ CHGS_w077_iLineOCRMS: 12|1@1+ (1,0) [0|0] "" X
 SG_ CHGS_w078_boostPrechargeFail: 13|1@1+ (1,0) [0|0] "" X
 SG_ CHGS_w079_GFCI: 14|1@1+ (1,0) [0|0] "" X
 SG_ CHGS_w080_vIntOutofRange: 15|1@1+ (1,0) [0|0] "" X
 SG_ CHGS_w081_iacRegulation: 16|1@1+ (1,0) [0|0] "" X
 SG_ CHGS_w082_vIntRegulation: 17|1@1+ (1,0) [0|0] "" X
 SG_ CHGS_w083_allPhasesFaulted: 18|1@1+ (1,0) [0|0] "" X
 SG_ CHGS_w084_vOutRegulation: 19|1@1+ (1,0) [0|0] "" X
 SG_ CHGS_w085_adcReference: 20|1@1+ (1,0) [0|0] "" X
 SG_ CHGS_w086_CPLDInhibEVSEAccept: 21|1@1+ (1,0) [0|0] "" X
 SG_ CHGS_w087_inputRelayRationalty: 22|1@1+ (1,0) [0|0] "" X
 SG_ CHGS_w088_lostCommsChgrly: 23|1@1+ (1,0) [0|0] "" X
 SG_ CHGS_w089_iLineRationality: 24|1@1+ (1,0) [0|0] "" X
 SG_ CHGS_w090_vLineRationality: 25|1@1+ (1,0) [0|0] "" X
 SG_ CHGS_w091_proximityRationality: 26|1@1+ (1,0) [0|0] "" X
 SG_ CHGS_w092_vOutRationality: 27|1@1+ (1,0) [0|0] "" X
 SG_ CHGS_w093_vIntRationality: 28|1@1+ (1,0) [0|0] "" X
 SG_ CHGS_w094_igbtTempRationality: 29|1@1+ (1,0) [0|0] "" X
 SG_ CHGS_w095_htsinkTempRationality: 30|1@1+ (1,0) [0|0] "" X
 SG_ CHGS_w096_ambientTempRationality: 31|1@1+ (1,0) [0|0] "" X
 SG_ CHGS_w097_hvilRationality: 32|1@1+ (1,0) [0|0] "" X
 SG_ CHGS_w098_iOutRationality: 33|1@1+ (1,0) [0|0] "" X
 SG_ CHGS_w099_noFlowDetected: 34|1@1+ (1,0) [0|0] "" X
 SG_ CHGS_w100_hw15VUV: 35|1@1+ (1,0) [0|0] "" X
 SG_ CHGS_w101_lostCommsPhase: 36|1@1+ (1,0) [0|0] "" X
 SG_ CHGS_w102_lostCommsMaster: 37|1@1+ (1,0) [0|0] "" X
 SG_ CHGS_w103_lostCommsSlave: 38|1@1+ (1,0) [0|0] "" X
 SG_ CHGS_w104_magneticsOT: 39|1@1+ (1,0) [0|0] "" X
 SG_ CHGS_w105_magTempRationality: 40|1@1+ (1,0) [0|0] "" X
 SG_ CHGS_w106_gfciRationality: 41|1@1+ (1,0) [0|0] "" X
 SG_ CHGS_w107_cpldRationality: 42|1@1+ (1,0) [0|0] "" X
 SG_ CHGS_w108_cpCoverOpen: 43|1@1+ (1,0) [0|0] "" X
 SG_ CHGS_w109_resetAttemptInEnable: 44|1@1+ (1,0) [0|0] "" X
 SG_ CHGS_w110_busOff: 45|1@1+ (1,0) [0|0] "" X
 SG_ CHGS_w111_AttemptToFastCharge: 46|1@1+ (1,0) [0|0] "" X
 SG_ CHGS_w112_packConfig: 47|1@1+ (1,0) [0|0] "" X
 SG_ CHGS_w113_eepromError: 48|1@1+ (1,0) [0|0] "" X
 SG_ CHGS_w114_phEnRationality: 49|1@1+ (1,0) [0|0] "" X
 SG_ CHGS_w115_chargerConfig: 50|1@1+ (1,0) [0|0] "" X
 SG_ CHGS_w116_HVJBOT: 51|1@1+ (1,0) [0|0] "" X
 SG_ CHGS_w117_HVJBOTFault: 52|1@1+ (1,0) [0|0] "" X
 SG_ CHGS_w118_VDiffHwRationality: 53|1@1+ (1,0) [0|0] "" X
 SG_ CHGS_w119_FCNotClosed: 54|1@1+ (1,0) [0|0] "" X
 SG_ CHGS_w120_unused: 55|1@1+ (1,0) [0|0] "" X
 SG_ CHGS_w121_crashDetected: 56|1@1+ (1,0) [0|0] "" X
 SG_ CHGS_w122_dioRationality: 57|1@1+ (1,0) [0|0] "" X
 SG_ CHGS_w123_liveCableDisconnect: 58|1@1+ (1,0) [0|0] "" X
 SG_ CHGS_w124_ph3VersionMismatch: 59|1@1+ (1,0) [0|0] "" X
 SG_ CHGS_w125_leakageTestFailure: 60|1@1+ (1,0) [0|0] "" X
 SG_ CHGS_w126_allPhasesMIA: 61|1@1+ (1,0) [0|0] "" X
 SG_ CHGS_w127_hvCableBadPolarity: 62|1@1+ (1,0) [0|0] "" X
 SG_ CHGS_w128_leakageTestLow: 63|1@1+ (1,0) [0|0] "" X

BO_ 558 CHGVI_HVJBstatus: 8 ETH
 SG_ CHGVI_PwrCmdPilotCurrent: 40|10@1+ (0.1,0) [0|0] "A" X
 SG_ HVJB_Current: 8|12@1- (0.1,0) [0|0] "A" X
 SG_ HVJB_FCContactorsDriven: 25|1@1+ (1,0) [0|0] "" X
 SG_ HVJB_FCCtrFaultLine: 32|8@1+ (0.013,0) [0|0] "V" X
 SG_ HVJB_FCDidNotClose: 26|1@1+ (1,0) [0|0] "" X
 SG_ HVJB_FCWelded: 27|1@1+ (1,0) [0|0] "" X
 SG_ HVJB_Fault: 24|1@1+ (1,0) [0|0] "" X
 SG_ HVJB_OT: 28|1@1+ (1,0) [0|0] "" X
 SG_ HVJB_Temperature: 0|8@1+ (1,0) [0|0] "C" X

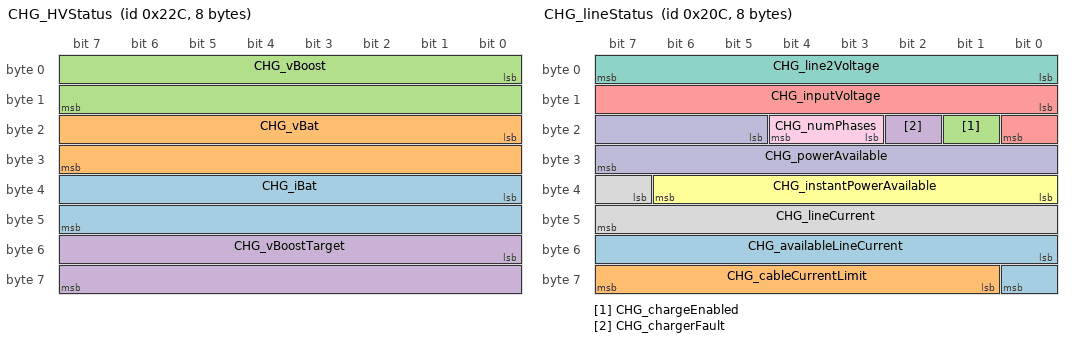
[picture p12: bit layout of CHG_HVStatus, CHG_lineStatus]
BO_ 556 CHG_HVStatus: 8 ETH
 SG_ CHG_iBat: 32|16@1+ (0.00126648,0) [0|0] "A" X
 SG_ CHG_vBat: 16|16@1+ (0.0105286,0) [0|0] "V" X
 SG_ CHG_vBoost: 0|16@1+ (0.00762939,0) [0|0] "V" X
 SG_ CHG_vBoostTarget: 48|16@1+ (0.00762939,0) [0|0] "V" X

BO_ 828 CHG_dtcMatrix: 8 ETH
 SG_ CHG_dtcIndex M: 0|8@1+ (1,0) [0|0] "" X
 SG_ CHG_d001_replaceCharger m0: 8|2@1+ (1,0) [0|0] "" X
 SG_ CHG_d002_12VOV m0: 10|2@1+ (1,0) [0|0] "" X
 SG_ CHG_d003_12VUV m0: 12|2@1+ (1,0) [0|0] "" X
 SG_ CHG_d004_overTemp m0: 14|2@1+ (1,0) [0|0] "" X
 SG_ CHG_d005_lowFlow m0: 16|2@1+ (1,0) [0|0] "" X
 SG_ CHG_d006_HVUV m0: 18|2@1+ (1,0) [0|0] "" X
 SG_ CHG_d007_FCFuseBlown m0: 20|2@1+ (1,0) [0|0] "" X
 SG_ CHG_d008_FCWeld m0: 22|2@1+ (1,0) [0|0] "" X
 SG_ CHG_d009_FCWontClose m0: 24|2@1+ (1,0) [0|0] "" X
 SG_ CHG_d010_FCCnctrPower m0: 26|2@1+ (1,0) [0|0] "" X
 SG_ CHG_d011_proxRationality m0: 28|2@1+ (1,0) [0|0] "" X
 SG_ CHG_d012_lostComms m0: 30|2@1+ (1,0) [0|0] "" X
 SG_ CHG_d013_HVIL m0: 32|2@1+ (1,0) [0|0] "" X
 SG_ CHG_d014_15VUV m0: 34|2@1+ (1,0) [0|0] "" X
 SG_ CHG_d015_unused m0: 36|2@1+ (1,0) [0|0] "" X
 SG_ CHG_d016_unused m0: 38|2@1+ (1,0) [0|0] "" X
 SG_ CHG_d017_unused m0: 40|2@1+ (1,0) [0|0] "" X
 SG_ CHG_d018_unused m0: 42|2@1+ (1,0) [0|0] "" X
 SG_ CHG_d019_unused m0: 44|2@1+ (1,0) [0|0] "" X
 SG_ CHG_d020_unused m0: 46|2@1+ (1,0) [0|0] "" X
 SG_ CHG_d021_unused m0: 48|2@1+ (1,0) [0|0] "" X
 SG_ CHG_d022_unused m0: 50|2@1+ (1,0) [0|0] "" X
 SG_ CHG_d023_unused m0: 52|2@1+ (1,0) [0|0] "" X
 SG_ CHG_d024_unused m0: 54|2@1+ (1,0) [0|0] "" X
 SG_ CHG_d025_unused m0: 56|2@1+ (1,0) [0|0] "" X
 SG_ CHG_d026_unused m0: 58|2@1+ (1,0) [0|0] "" X
 SG_ CHG_d027_unused m0: 60|2@1+ (1,0) [0|0] "" X
 SG_ CHG_d028_unused m0: 62|2@1+ (1,0) [0|0] "" X

BO_ 36 CHG_faultMatrix1: 8 ETH
 SG_ CHG_f001_hwBuck: 0|1@1+ (1,0) [0|0] "" X
 SG_ CHG_f002_hwBoost: 1|1@1+ (1,0) [0|0] "" X
 SG_ CHG_f003_hwBiasBoost: 2|1@1+ (1,0) [0|0] "" X
 SG_ CHG_f004_hwBiasBuck: 3|1@1+ (1,0) [0|0] "" X
 SG_ CHG_f005_hwXfrmrOC: 4|1@1+ (1,0) [0|0] "" X
 SG_ CHG_f006_hwBoost1OC: 5|1@1+ (1,0) [0|0] "" X
 SG_ CHG_f007_hwBoost2OC: 6|1@1+ (1,0) [0|0] "" X
 SG_ CHG_f008_hwThermal1: 7|1@1+ (1,0) [0|0] "" X
 SG_ CHG_f009_hwFCWeld: 8|1@1+ (1,0) [0|0] "" X
 SG_ CHG_f010_hwIllegalFCRequest: 9|1@1+ (1,0) [0|0] "" X
 SG_ CHG_f011_hwVInOV: 10|1@1+ (1,0) [0|0] "" X
 SG_ CHG_f012_hwFastChargeDriver: 11|1@1+ (1,0) [0|0] "" X
 SG_ CHG_f013_hwIllegalInletRequest: 12|1@1+ (1,0) [0|0] "" X
 SG_ CHG_f014_hwThermal2: 13|1@1+ (1,0) [0|0] "" X
 SG_ CHG_f015_hwAntispark: 14|1@1+ (1,0) [0|0] "" X
 SG_ CHG_f016_hwVOutOV: 15|1@1+ (1,0) [0|0] "" X
 SG_ CHG_f017_hwIntermediateBus: 16|1@1+ (1,0) [0|0] "" X
 SG_ CHG_f018_hwLineOC: 17|1@1+ (1,0) [0|0] "" X
 SG_ CHG_f019_hwIBatOC: 18|1@1+ (1,0) [0|0] "" X
 SG_ CHG_f020_hwHVIL: 19|1@1+ (1,0) [0|0] "" X
 SG_ CHG_f021_15V: 20|1@1+ (1,0) [0|0] "" X
 SG_ CHG_f022_hw12VUV: 21|1@1+ (1,0) [0|0] "" X
 SG_ CHG_f023_hwReset: 22|1@1+ (1,0) [0|0] "" X
 SG_ CHG_f024_VLineOVPk: 23|1@1+ (1,0) [0|0] "" X
 SG_ CHG_f025_VLineUV: 24|1@1+ (1,0) [0|0] "" X
 SG_ CHG_f026_VOutOV: 25|1@1+ (1,0) [0|0] "" X
 SG_ CHG_f027_VOutUV: 26|1@1+ (1,0) [0|0] "" X
 SG_ CHG_f028_igbtOT: 27|1@1+ (1,0) [0|0] "" X
 SG_ CHG_f029_ambientOT: 28|1@1+ (1,0) [0|0] "" X
 SG_ CHG_f030_VLineFreqOF: 29|1@1+ (1,0) [0|0] "" X
 SG_ CHG_f031_VLineFreqUF: 30|1@1+ (1,0) [0|0] "" X
 SG_ CHG_f032_pllSyncLoss: 31|1@1+ (1,0) [0|0] "" X
 SG_ CHG_f033_pilotFaulted: 32|1@1+ (1,0) [0|0] "" X
 SG_ CHG_f034_swHVIL: 33|1@1+ (1,0) [0|0] "" X
 SG_ CHG_f035_pilotRationality: 34|1@1+ (1,0) [0|0] "" X
 SG_ CHG_f036_HVJB_disconnected: 35|1@1+ (1,0) [0|0] "" X
 SG_ CHG_f037_recOT: 36|1@1+ (1,0) [0|0] "" X
 SG_ CHG_f038_buckOT: 37|1@1+ (1,0) [0|0] "" X
 SG_ CHG_f039_12V: 38|1@1+ (1,0) [0|0] "" X
 SG_ CHG_f040_lostCommsGTW: 39|1@1+ (1,0) [0|0] "" X
 SG_ CHG_f041_lostCommsBMS: 40|1@1+ (1,0) [0|0] "" X
 SG_ CHG_f042_lostCommsCP: 41|1@1+ (1,0) [0|0] "" X
 SG_ CHG_f043_canRationality: 42|1@1+ (1,0) [0|0] "" X
 SG_ CHG_f044_lostCommsVI: 43|1@1+ (1,0) [0|0] "" X
 SG_ CHG_f045_invalidState: 44|1@1+ (1,0) [0|0] "" X
 SG_ CHG_f046_movingInCharge: 45|1@1+ (1,0) [0|0] "" X
 SG_ CHG_f047_HVJB_groundLoss: 46|1@1+ (1,0) [0|0] "" X
 SG_ CHG_f048_FCWeldCheckState: 47|1@1+ (1,0) [0|0] "" X
 SG_ CHG_f049_invalidChargeReq: 48|1@1+ (1,0) [0|0] "" X
 SG_ CHG_f050_invalidStateChng: 49|1@1+ (1,0) [0|0] "" X
 SG_ CHG_f051_FCStateFault: 50|1@1+ (1,0) [0|0] "" X
 SG_ CHG_f052_memoryError: 51|1@1+ (1,0) [0|0] "" X
 SG_ CHG_f053_networkManagement: 52|1@1+ (1,0) [0|0] "" X
 SG_ CHG_f054_interruptTime: 53|1@1+ (1,0) [0|0] "" X
 SG_ CHG_f055_VLineDischarge: 54|1@1+ (1,0) [0|0] "" X
 SG_ CHG_f056_5VPower: 55|1@1+ (1,0) [0|0] "" X
 SG_ CHG_f057_VLineOV: 56|1@1+ (1,0) [0|0] "" X
 SG_ CHG_f058_watchdogreset: 57|1@1+ (1,0) [0|0] "" X
 SG_ CHG_f059_SWCANError: 58|1@1+ (1,0) [0|0] "" X
 SG_ CHG_f060_FCCntrVcheck: 59|1@1+ (1,0) [0|0] "" X
 SG_ CHG_f061_FCAuxCntrRationality: 60|1@1+ (1,0) [0|0] "" X
 SG_ CHG_f062_FCPosCntrWelded: 61|1@1+ (1,0) [0|0] "" X
 SG_ CHG_f063_FCNegCntrWelded: 62|1@1+ (1,0) [0|0] "" X
 SG_ CHG_f064_prechargeRelayWelded: 63|1@1+ (1,0) [0|0] "" X

BO_ 37 CHG_faultMatrix2: 8 ETH
 SG_ CHG_f065_FCCntrRationalitycheck: 0|1@1+ (1,0) [0|0] "" X
 SG_ CHG_f066_unexpectedVintBehavior: 1|1@1+ (1,0) [0|0] "" X
 SG_ CHG_f067_line2OV: 2|1@1+ (1,0) [0|0] "" X
 SG_ CHG_f068_heatsinkTempSlope: 3|1@1+ (1,0) [0|0] "" X
 SG_ CHG_f069_igbtTempSlope: 4|1@1+ (1,0) [0|0] "" X
 SG_ CHG_f070_heatsinkOT: 5|1@1+ (1,0) [0|0] "" X
 SG_ CHG_f071_chargeThermalLimit: 6|1@1+ (1,0) [0|0] "" X
 SG_ CHG_f072_assertion: 7|1@1+ (1,0) [0|0] "" X
 SG_ CHG_f073_unexpectedVoutBehavior: 8|1@1+ (1,0) [0|0] "" X
 SG_ CHG_f074_cpldFaulted: 9|1@1+ (1,0) [0|0] "" X
 SG_ CHG_f075_stateTransitionDenied: 10|1@1+ (1,0) [0|0] "" X
 SG_ CHG_f076_iLineOCPk: 11|1@1+ (1,0) [0|0] "" X
 SG_ CHG_f077_iLineOCRMS: 12|1@1+ (1,0) [0|0] "" X
 SG_ CHG_f078_boostPrechargeFail: 13|1@1+ (1,0) [0|0] "" X
 SG_ CHG_f079_GFCI: 14|1@1+ (1,0) [0|0] "" X
 SG_ CHG_f080_vIntOutofRange: 15|1@1+ (1,0) [0|0] "" X
 SG_ CHG_f081_iacRegulation: 16|1@1+ (1,0) [0|0] "" X
 SG_ CHG_f082_vIntRegulation: 17|1@1+ (1,0) [0|0] "" X
 SG_ CHG_f083_allPhasesFaulted: 18|1@1+ (1,0) [0|0] "" X
 SG_ CHG_f084_vOutRegulation: 19|1@1+ (1,0) [0|0] "" X
 SG_ CHG_f085_adcReference: 20|1@1+ (1,0) [0|0] "" X
 SG_ CHG_f086_CPLDInhibEVSEAccept: 21|1@1+ (1,0) [0|0] "" X
 SG_ CHG_f087_inputRelayRationalty: 22|1@1+ (1,0) [0|0] "" X
 SG_ CHG_f088_lostCommsChgrly: 23|1@1+ (1,0) [0|0] "" X
 SG_ CHG_f089_iLineRationality: 24|1@1+ (1,0) [0|0] "" X
 SG_ CHG_f090_vLineRationality: 25|1@1+ (1,0) [0|0] "" X
 SG_ CHG_f091_proximityRationality: 26|1@1+ (1,0) [0|0] "" X
 SG_ CHG_f092_vOutRationality: 27|1@1+ (1,0) [0|0] "" X
 SG_ CHG_f093_vIntRationality: 28|1@1+ (1,0) [0|0] "" X
 SG_ CHG_f094_igbtTempRationality: 29|1@1+ (1,0) [0|0] "" X
 SG_ CHG_f095_htsinkTempRationality: 30|1@1+ (1,0) [0|0] "" X
 SG_ CHG_f096_ambientTempRationality: 31|1@1+ (1,0) [0|0] "" X
 SG_ CHG_f097_hvilRationality: 32|1@1+ (1,0) [0|0] "" X
 SG_ CHG_f098_iOutRationality: 33|1@1+ (1,0) [0|0] "" X
 SG_ CHG_f099_noFlowDetected: 34|1@1+ (1,0) [0|0] "" X
 SG_ CHG_f100_hw15VUV: 35|1@1+ (1,0) [0|0] "" X
 SG_ CHG_f101_lostCommsPhase: 36|1@1+ (1,0) [0|0] "" X
 SG_ CHG_f102_lostCommsMaster: 37|1@1+ (1,0) [0|0] "" X
 SG_ CHG_f103_lostCommsSlave: 38|1@1+ (1,0) [0|0] "" X
 SG_ CHG_f104_magneticsOT: 39|1@1+ (1,0) [0|0] "" X
 SG_ CHG_f105_magTempRationality: 40|1@1+ (1,0) [0|0] "" X
 SG_ CHG_f106_gfciRationality: 41|1@1+ (1,0) [0|0] "" X
 SG_ CHG_f107_cpldRationality: 42|1@1+ (1,0) [0|0] "" X
 SG_ CHG_f108_cpCoverOpen: 43|1@1+ (1,0) [0|0] "" X
 SG_ CHG_f109_resetAttemptInEnable: 44|1@1+ (1,0) [0|0] "" X
 SG_ CHG_f110_busOff: 45|1@1+ (1,0) [0|0] "" X
 SG_ CHG_f111_AttemptToFastCharge: 46|1@1+ (1,0) [0|0] "" X
 SG_ CHG_f112_packConfig: 47|1@1+ (1,0) [0|0] "" X
 SG_ CHG_f113_eepromError: 48|1@1+ (1,0) [0|0] "" X
 SG_ CHG_f114_phEnRationality: 49|1@1+ (1,0) [0|0] "" X
 SG_ CHG_f115_chargerConfig: 50|1@1+ (1,0) [0|0] "" X
 SG_ CHG_f116_HVJBOT: 51|1@1+ (1,0) [0|0] "" X
 SG_ CHG_f117_HVJBOTFault: 52|1@1+ (1,0) [0|0] "" X
 SG_ CHG_f118_VDiffHwRationality: 53|1@1+ (1,0) [0|0] "" X
 SG_ CHG_f119_FCNotClosed: 54|1@1+ (1,0) [0|0] "" X
 SG_ CHG_f120_HVJB_powerFault: 55|1@1+ (1,0) [0|0] "" X
 SG_ CHG_f121_crashDetected: 56|1@1+ (1,0) [0|0] "" X
 SG_ CHG_f122_dioRationality: 57|1@1+ (1,0) [0|0] "" X
 SG_ CHG_f123_liveCableDisconnect: 58|1@1+ (1,0) [0|0] "" X
 SG_ CHG_f124_ph3VersionMismatch: 59|1@1+ (1,0) [0|0] "" X
 SG_ CHG_f125_leakageTestFailure: 60|1@1+ (1,0) [0|0] "" X
 SG_ CHG_f126_allPhasesMIA: 61|1@1+ (1,0) [0|0] "" X
 SG_ CHG_f127_hvCableBadPolarity: 62|1@1+ (1,0) [0|0] "" X
 SG_ CHG_f128_leakageTestLow: 63|1@1+ (1,0) [0|0] "" X

BO_ 1340 CHG_info: 8 ETH
 SG_ CHG_infoIndex M: 0|8@1+ (1,0) [0|0] "" X
 SG_ CHG_infoBuildType m10: 8|8@1+ (1,0) [0|0] "" X
 SG_ CHG_infoBuildConfigID m10: 16|16@1+ (1,0) [0|0] "" X
 SG_ CHG_infoHardwareID m10: 32|16@1+ (1,0) [0|0] "" X
 SG_ CHG_infoComponentID m10: 48|16@1+ (1,0) [0|0] "" X
 SG_ CHG_infoPcbaID m11: 16|8@1+ (1,0) [0|0] "" X
 SG_ CHG_infoAssemblyID m11: 24|8@1+ (1,0) [0|0] "" X
 SG_ CHG_infoUsageID m11: 32|16@1+ (1,0) [0|0] "" X
 SG_ CHG_infoSubUsageID m11: 48|16@1+ (1,0) [0|0] "" X
 SG_ CHG_infoApplicationCRC m13: 32|32@1+ (1,0) [0|0] "" X
 SG_ CHG_infoBootloaderSvnRevision m14: 8|24@1+ (1,0) [0|0] "" X
 SG_ CHG_infoBootloaderCRC m15: 32|32@1+ (1,0) [0|0] "" X
 SG_ CHG_infoCPLDVersionMajor m16: 16|8@1+ (1,0) [0|0] "" X
 SG_ CHG_infoCPLDVersionMinor m16: 24|8@1+ (1,0) [0|0] "" X
 SG_ CHG_infoAppGitHashBytes m17: 10|54@1+ (4,0) [0|0] "" X
 SG_ CHG_infoBootGitHashBytes m18: 10|54@1+ (4,0) [0|0] "" X
 SG_ CHG_infoPlatformType m19: 8|8@1+ (1,0) [0|0] "" X
 SG_ CHG_infoMajorVersion m19: 16|8@1+ (1,0) [0|0] "" X
 SG_ CHG_infoBranchOrigin m19: 24|8@1+ (1,0) [0|0] "" X
 SG_ CHG_infoMaturity m19: 32|8@1+ (1,0) [0|0] "" X
 SG_ CHG_infoHardwareRevision m19: 40|8@1+ (1,0) [0|0] "" X
 SG_ CHG_infoBootUdsProtoVersion m20: 8|8@1+ (1,0) [0|0] "" X

BO_ 524 CHG_lineStatus: 8 ETH
 SG_ CHG_availableLineCurrent: 48|9@1+ (0.16666,0) [0|0] "A" X
 SG_ CHG_cableCurrentLimit: 57|7@1+ (1,0) [0|0] "A" X
 SG_ CHG_chargeEnabled: 17|1@1+ (1,0) [0|0] "" X
 SG_ CHG_chargerFault: 18|1@1+ (1,0) [0|0] "" X
 SG_ CHG_inputVoltage: 8|9@1+ (1,0) [0|0] "V" X
 SG_ CHG_instantPowerAvailable: 32|7@1+ (0.2,0) [0|0] "kW" X
 SG_ CHG_line2Voltage: 0|8@1+ (2,0) [0|0] "V" X
 SG_ CHG_lineCurrent: 39|9@1+ (0.16666,0) [0|0] "A" X
 SG_ CHG_numPhases: 19|2@1+ (1,0) [0|0] "" X
 SG_ CHG_powerAvailable: 21|11@1+ (0.01,0) [0|0] "kW" X

BO_ 540 CHG_status: 8 ETH
 SG_ CHG_GFCICurrent: 48|7@1+ (0.4,0) [0|0] "mA" X
 SG_ CHG_cableState: 27|2@1+ (1,0) [0|0] "" X
 SG_ CHG_cableType: 24|3@1+ (1,0) [0|0] "" X
 SG_ CHG_evseAccept: 0|1@1+ (1,0) [0|0] "" X
 SG_ CHG_evseRequest: 1|1@1+ (1,0) [0|0] "" X
 SG_ CHG_inputRelayState: 62|2@1+ (1,0) [0|0] "" X
 SG_ CHG_lineChgShuttingDown: 40|1@1+ (1,0) [0|0] "" X
 SG_ CHG_mainState: 4|4@1+ (1,0) [0|0] "" X
 SG_ CHG_maxLineCurrent: 55|7@1+ (1,0) [0|0] "A" X
 SG_ CHG_phaseConfig: 29|3@1+ (1,0) [0|0] "" X
 SG_ CHG_pilot: 13|3@1+ (1,0) [0|0] "" X
 SG_ CHG_pilotCurrent: 16|8@1+ (0.5,0) [0|0] "A" X
 SG_ CHG_proximity: 11|2@1+ (1,0) [0|0] "" X
 SG_ CHG_proximitySimUnlatched: 10|1@1+ (1,0) [0|0] "" X
 SG_ CHG_requestHVACPowerOn: 9|1@1+ (1,0) [0|0] "" X
 SG_ CHG_retryCount: 2|2@1+ (1,0) [0|0] "" X
 SG_ CHG_subState: 41|6@1+ (1,0) [0|0] "" X
 SG_ CHG_v12V: 32|8@1+ (0.1,0) [0|0] "V" X
 SG_ CHG_voltageLimitAchieved: 8|1@1+ (1,0) [0|0] "" X
 SG_ CHG_waveformDataReady: 47|1@1+ (1,0) [0|0] "" X

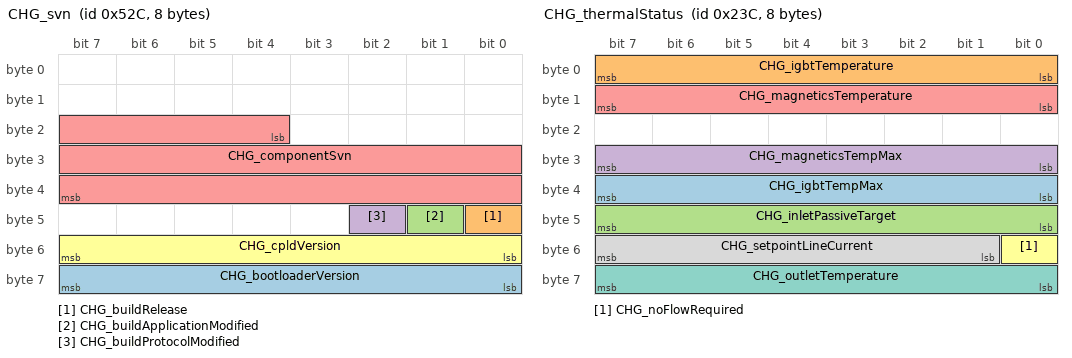
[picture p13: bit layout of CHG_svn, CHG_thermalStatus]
BO_ 1324 CHG_svn: 8 ETH
 SG_ CHG_bootloaderVersion: 56|8@1+ (1,0) [0|0] "" X
 SG_ CHG_buildRelease: 40|1@1+ (1,0) [0|0] "" X
 SG_ CHG_buildApplicationModified: 41|1@1+ (1,0) [0|0] "" X
 SG_ CHG_buildProtocolModified: 42|1@1+ (1,0) [0|0] "" X
 SG_ CHG_componentSvn: 20|20@1+ (1,0) [0|0] "" X
 SG_ CHG_cpldVersion: 48|8@1+ (1,0) [0|0] "" X

BO_ 572 CHG_thermalStatus: 8 ETH
 SG_ CHG_igbtTempMax: 32|8@1+ (1,-40) [0|0] "C" X
 SG_ CHG_igbtTemperature: 0|8@1+ (1,-40) [0|0] "C" X
 SG_ CHG_inletPassiveTarget: 40|8@1+ (1,-40) [0|0] "C" X
 SG_ CHG_magneticsTempMax: 24|8@1+ (1,-40) [0|0] "C" X
 SG_ CHG_magneticsTemperature: 8|8@1+ (1,-40) [0|0] "C" X
 SG_ CHG_noFlowRequired: 48|1@1+ (1,0) [0|0] "" X
 SG_ CHG_outletTemperature: 56|8@1+ (1,-40) [0|0] "C" X
 SG_ CHG_setpointLineCurrent: 49|7@1+ (1,0) [0|0] "A" X

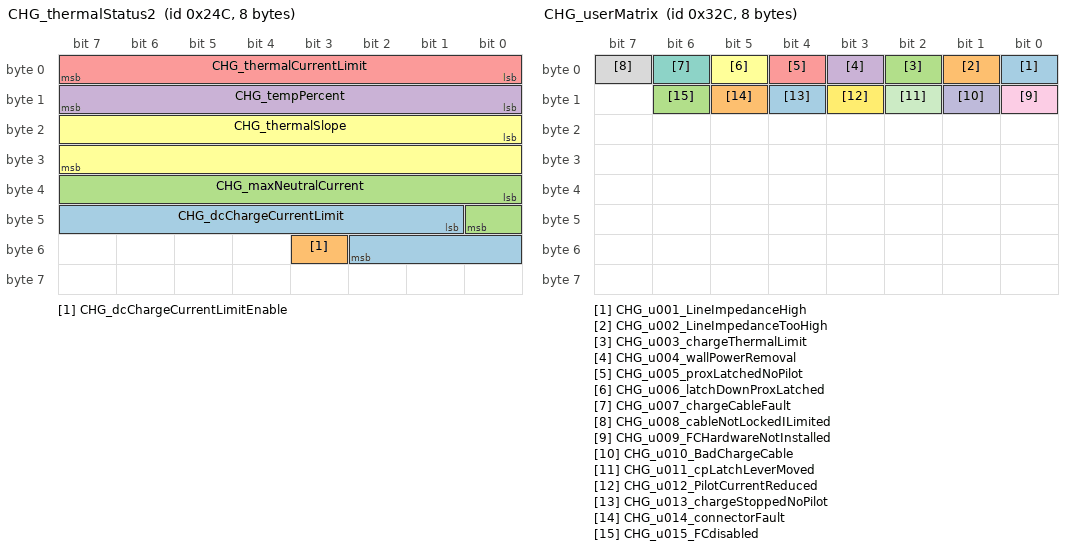
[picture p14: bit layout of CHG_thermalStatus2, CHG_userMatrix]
BO_ 588 CHG_thermalStatus2: 8 ETH
 SG_ CHG_dcChargeCurrentLimit: 41|10@1+ (1,0) [0|0] "A" X
 SG_ CHG_dcChargeCurrentLimitEnable: 51|1@1+ (1,0) [0|0] "" X
 SG_ CHG_maxNeutralCurrent: 32|9@1+ (0.16666,0) [0|0] "A" X
 SG_ CHG_tempPercent: 8|8@1+ (0.4,0) [0|0] "%" X
 SG_ CHG_thermalCurrentLimit: 0|8@1+ (0.234375,0) [0|0] "A" X
 SG_ CHG_thermalSlope: 16|16@1- (0.001,0) [0|0] "degC/sec" X

BO_ 1564 CHG_udsResponse: 8 ETH
 SG_ CHG_udsResponseData: 0|54@0+ (1024,0) [0|0] "" X

BO_ 812 CHG_userMatrix: 8 ETH
 SG_ CHG_u001_LineImpedanceHigh: 0|1@1+ (1,0) [0|0] "" X
 SG_ CHG_u002_LineImpedanceTooHigh: 1|1@1+ (1,0) [0|0] "" X
 SG_ CHG_u003_chargeThermalLimit: 2|1@1+ (1,0) [0|0] "" X
 SG_ CHG_u004_wallPowerRemoval: 3|1@1+ (1,0) [0|0] "" X
 SG_ CHG_u005_proxLatchedNoPilot: 4|1@1+ (1,0) [0|0] "" X
 SG_ CHG_u006_latchDownProxLatched: 5|1@1+ (1,0) [0|0] "" X
 SG_ CHG_u007_chargeCableFault: 6|1@1+ (1,0) [0|0] "" X
 SG_ CHG_u008_cableNotLockedILimited: 7|1@1+ (1,0) [0|0] "" X
 SG_ CHG_u009_FCHardwareNotInstalled: 8|1@1+ (1,0) [0|0] "" X
 SG_ CHG_u010_BadChargeCable: 9|1@1+ (1,0) [0|0] "" X
 SG_ CHG_u011_cpLatchLeverMoved: 10|1@1+ (1,0) [0|0] "" X
 SG_ CHG_u012_PilotCurrentReduced: 11|1@1+ (1,0) [0|0] "" X
 SG_ CHG_u013_chargeStoppedNoPilot: 12|1@1+ (1,0) [0|0] "" X
 SG_ CHG_u014_connectorFault: 13|1@1+ (1,0) [0|0] "" X
 SG_ CHG_u015_FCdisabled: 14|1@1+ (1,0) [0|0] "" X

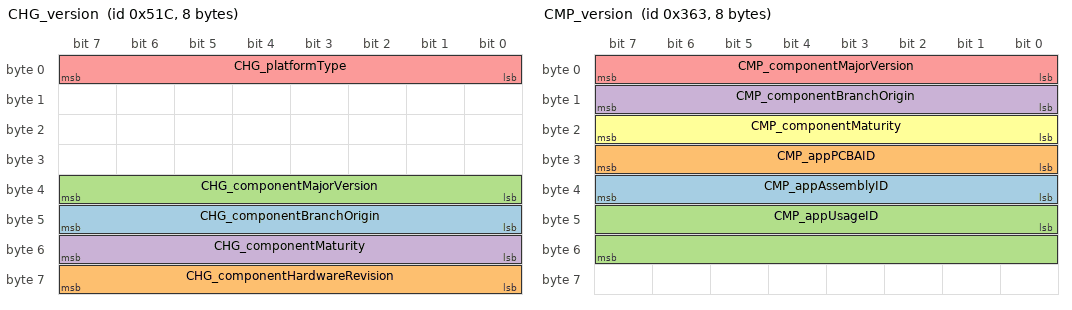
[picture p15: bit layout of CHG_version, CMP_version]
BO_ 1308 CHG_version: 8 ETH
 SG_ CHG_componentBranchOrigin: 40|8@1+ (1,0) [0|0] "" X
 SG_ CHG_componentHardwareRevision: 56|8@1+ (1,0) [0|0] "" X
 SG_ CHG_componentMajorVersion: 32|8@1+ (1,0) [0|0] "" X
 SG_ CHG_componentMaturity: 48|8@1+ (1,0) [0|0] "" X
 SG_ CHG_platformType: 0|8@1+ (1,0) [0|0] "" X

BO_ 38 CHG_warningMatrix1: 8 ETH
 SG_ CHG_w001_hwBuck: 0|1@1+ (1,0) [0|0] "" X
 SG_ CHG_w002_hwBoost: 1|1@1+ (1,0) [0|0] "" X
 SG_ CHG_w003_hwBiasBoost: 2|1@1+ (1,0) [0|0] "" X
 SG_ CHG_w004_hwBiasBuck: 3|1@1+ (1,0) [0|0] "" X
 SG_ CHG_w005_hwXfrmrOC: 4|1@1+ (1,0) [0|0] "" X
 SG_ CHG_w006_hwBoost1OC: 5|1@1+ (1,0) [0|0] "" X
 SG_ CHG_w007_hwBoost2OC: 6|1@1+ (1,0) [0|0] "" X
 SG_ CHG_w008_hwThermal1: 7|1@1+ (1,0) [0|0] "" X
 SG_ CHG_w009_hwFCWeld: 8|1@1+ (1,0) [0|0] "" X
 SG_ CHG_w010_hwIllegalFCRequest: 9|1@1+ (1,0) [0|0] "" X
 SG_ CHG_w011_hwVInOV: 10|1@1+ (1,0) [0|0] "" X
 SG_ CHG_w012_hwFastChargeDriver: 11|1@1+ (1,0) [0|0] "" X
 SG_ CHG_w013_hwIllegalInletRequest: 12|1@1+ (1,0) [0|0] "" X
 SG_ CHG_w014_hwThermal2: 13|1@1+ (1,0) [0|0] "" X
 SG_ CHG_w015_hwAntispark: 14|1@1+ (1,0) [0|0] "" X
 SG_ CHG_w016_hwVOutOV: 15|1@1+ (1,0) [0|0] "" X
 SG_ CHG_w017_hwIntermediateBus: 16|1@1+ (1,0) [0|0] "" X
 SG_ CHG_w018_hwLineOC: 17|1@1+ (1,0) [0|0] "" X
 SG_ CHG_w019_hwIBatOC: 18|1@1+ (1,0) [0|0] "" X
 SG_ CHG_w020_hwHVIL: 19|1@1+ (1,0) [0|0] "" X
 SG_ CHG_w021_15V: 20|1@1+ (1,0) [0|0] "" X
 SG_ CHG_w022_hw12VUV: 21|1@1+ (1,0) [0|0] "" X
 SG_ CHG_w023_hwReset: 22|1@1+ (1,0) [0|0] "" X
 SG_ CHG_w024_VLineOVPk: 23|1@1+ (1,0) [0|0] "" X
 SG_ CHG_w025_VLineUV: 24|1@1+ (1,0) [0|0] "" X
 SG_ CHG_w026_VOutOV: 25|1@1+ (1,0) [0|0] "" X
 SG_ CHG_w027_VOutUV: 26|1@1+ (1,0) [0|0] "" X
 SG_ CHG_w028_igbtOT: 27|1@1+ (1,0) [0|0] "" X
 SG_ CHG_w029_ambientOT: 28|1@1+ (1,0) [0|0] "" X
 SG_ CHG_w030_VLineFreqOF: 29|1@1+ (1,0) [0|0] "" X
 SG_ CHG_w031_VLineFreqUF: 30|1@1+ (1,0) [0|0] "" X
 SG_ CHG_w032_pllSyncLoss: 31|1@1+ (1,0) [0|0] "" X
 SG_ CHG_w033_pilotFaulted: 32|1@1+ (1,0) [0|0] "" X
 SG_ CHG_w034_swHVIL: 33|1@1+ (1,0) [0|0] "" X
 SG_ CHG_w035_pilotRationality: 34|1@1+ (1,0) [0|0] "" X
 SG_ CHG_w036_HVJB_disconnected: 35|1@1+ (1,0) [0|0] "" X
 SG_ CHG_w037_recOT: 36|1@1+ (1,0) [0|0] "" X
 SG_ CHG_w038_buckOT: 37|1@1+ (1,0) [0|0] "" X
 SG_ CHG_w039_12V: 38|1@1+ (1,0) [0|0] "" X
 SG_ CHG_w040_lostCommsGTW: 39|1@1+ (1,0) [0|0] "" X
 SG_ CHG_w041_lostCommsBMS: 40|1@1+ (1,0) [0|0] "" X
 SG_ CHG_w042_lostCommsCP: 41|1@1+ (1,0) [0|0] "" X
 SG_ CHG_w043_canRationality: 42|1@1+ (1,0) [0|0] "" X
 SG_ CHG_w044_lostCommsVI: 43|1@1+ (1,0) [0|0] "" X
 SG_ CHG_w045_invalidState: 44|1@1+ (1,0) [0|0] "" X
 SG_ CHG_w046_movingInCharge: 45|1@1+ (1,0) [0|0] "" X
 SG_ CHG_w047_HVJB_groundLoss: 46|1@1+ (1,0) [0|0] "" X
 SG_ CHG_w048_FCWeldCheckState: 47|1@1+ (1,0) [0|0] "" X
 SG_ CHG_w049_invalidChargeReq: 48|1@1+ (1,0) [0|0] "" X
 SG_ CHG_w050_invalidStateChng: 49|1@1+ (1,0) [0|0] "" X
 SG_ CHG_w051_FCStateFault: 50|1@1+ (1,0) [0|0] "" X
 SG_ CHG_w052_memoryError: 51|1@1+ (1,0) [0|0] "" X
 SG_ CHG_w053_networkManagement: 52|1@1+ (1,0) [0|0] "" X
 SG_ CHG_w054_interruptTime: 53|1@1+ (1,0) [0|0] "" X
 SG_ CHG_w055_VLineDischarge: 54|1@1+ (1,0) [0|0] "" X
 SG_ CHG_w056_5VPower: 55|1@1+ (1,0) [0|0] "" X
 SG_ CHG_w057_VLineOV: 56|1@1+ (1,0) [0|0] "" X
 SG_ CHG_w058_watchdogreset: 57|1@1+ (1,0) [0|0] "" X
 SG_ CHG_w059_SWCANError: 58|1@1+ (1,0) [0|0] "" X
 SG_ CHG_w060_FCCntrVcheck: 59|1@1+ (1,0) [0|0] "" X
 SG_ CHG_w061_FCAuxCntrRationality: 60|1@1+ (1,0) [0|0] "" X
 SG_ CHG_w062_FCPosCntrWelded: 61|1@1+ (1,0) [0|0] "" X
 SG_ CHG_w063_FCNegCntrWelded: 62|1@1+ (1,0) [0|0] "" X
 SG_ CHG_w064_prechargeRelayWelded: 63|1@1+ (1,0) [0|0] "" X

BO_ 39 CHG_warningMatrix2: 8 ETH
 SG_ CHG_w065_FCCntrRationalitycheck: 0|1@1+ (1,0) [0|0] "" X
 SG_ CHG_w066_unexpectedVintBehavior: 1|1@1+ (1,0) [0|0] "" X
 SG_ CHG_w067_line2OV: 2|1@1+ (1,0) [0|0] "" X
 SG_ CHG_w068_heatsinkTempSlope: 3|1@1+ (1,0) [0|0] "" X
 SG_ CHG_w069_igbtTempSlope: 4|1@1+ (1,0) [0|0] "" X
 SG_ CHG_w070_heatsinkOT: 5|1@1+ (1,0) [0|0] "" X
 SG_ CHG_w071_chargeThermalLimit: 6|1@1+ (1,0) [0|0] "" X
 SG_ CHG_w072_assertion: 7|1@1+ (1,0) [0|0] "" X
 SG_ CHG_w073_unexpectedVoutBehavior: 8|1@1+ (1,0) [0|0] "" X
 SG_ CHG_w074_cpldFaulted: 9|1@1+ (1,0) [0|0] "" X
 SG_ CHG_w075_stateTransitionDenied: 10|1@1+ (1,0) [0|0] "" X
 SG_ CHG_w076_iLineOCPk: 11|1@1+ (1,0) [0|0] "" X
 SG_ CHG_w077_iLineOCRMS: 12|1@1+ (1,0) [0|0] "" X
 SG_ CHG_w078_boostPrechargeFail: 13|1@1+ (1,0) [0|0] "" X
 SG_ CHG_w079_GFCI: 14|1@1+ (1,0) [0|0] "" X
 SG_ CHG_w080_vIntOutofRange: 15|1@1+ (1,0) [0|0] "" X
 SG_ CHG_w081_iacRegulation: 16|1@1+ (1,0) [0|0] "" X
 SG_ CHG_w082_vIntRegulation: 17|1@1+ (1,0) [0|0] "" X
 SG_ CHG_w083_allPhasesFaulted: 18|1@1+ (1,0) [0|0] "" X
 SG_ CHG_w084_vOutRegulation: 19|1@1+ (1,0) [0|0] "" X
 SG_ CHG_w085_adcReference: 20|1@1+ (1,0) [0|0] "" X
 SG_ CHG_w086_CPLDInhibEVSEAccept: 21|1@1+ (1,0) [0|0] "" X
 SG_ CHG_w087_inputRelayRationalty: 22|1@1+ (1,0) [0|0] "" X
 SG_ CHG_w088_lostCommsChgrly: 23|1@1+ (1,0) [0|0] "" X
 SG_ CHG_w089_iLineRationality: 24|1@1+ (1,0) [0|0] "" X
 SG_ CHG_w090_vLineRationality: 25|1@1+ (1,0) [0|0] "" X
 SG_ CHG_w091_proximityRationality: 26|1@1+ (1,0) [0|0] "" X
 SG_ CHG_w092_vOutRationality: 27|1@1+ (1,0) [0|0] "" X
 SG_ CHG_w093_vIntRationality: 28|1@1+ (1,0) [0|0] "" X
 SG_ CHG_w094_igbtTempRationality: 29|1@1+ (1,0) [0|0] "" X
 SG_ CHG_w095_htsinkTempRationality: 30|1@1+ (1,0) [0|0] "" X
 SG_ CHG_w096_ambientTempRationality: 31|1@1+ (1,0) [0|0] "" X
 SG_ CHG_w097_hvilRationality: 32|1@1+ (1,0) [0|0] "" X
 SG_ CHG_w098_iOutRationality: 33|1@1+ (1,0) [0|0] "" X
 SG_ CHG_w099_noFlowDetected: 34|1@1+ (1,0) [0|0] "" X
 SG_ CHG_w100_hw15VUV: 35|1@1+ (1,0) [0|0] "" X
 SG_ CHG_w101_lostCommsPhase: 36|1@1+ (1,0) [0|0] "" X
 SG_ CHG_w102_lostCommsMaster: 37|1@1+ (1,0) [0|0] "" X
 SG_ CHG_w103_lostCommsSlave: 38|1@1+ (1,0) [0|0] "" X
 SG_ CHG_w104_magneticsOT: 39|1@1+ (1,0) [0|0] "" X
 SG_ CHG_w105_magTempRationality: 40|1@1+ (1,0) [0|0] "" X
 SG_ CHG_w106_gfciRationality: 41|1@1+ (1,0) [0|0] "" X
 SG_ CHG_w107_cpldRationality: 42|1@1+ (1,0) [0|0] "" X
 SG_ CHG_w108_cpCoverOpen: 43|1@1+ (1,0) [0|0] "" X
 SG_ CHG_w109_resetAttemptInEnable: 44|1@1+ (1,0) [0|0] "" X
 SG_ CHG_w110_busOff: 45|1@1+ (1,0) [0|0] "" X
 SG_ CHG_w111_AttemptToFastCharge: 46|1@1+ (1,0) [0|0] "" X
 SG_ CHG_w112_packConfig: 47|1@1+ (1,0) [0|0] "" X
 SG_ CHG_w113_eepromError: 48|1@1+ (1,0) [0|0] "" X
 SG_ CHG_w114_phEnRationality: 49|1@1+ (1,0) [0|0] "" X
 SG_ CHG_w115_chargerConfig: 50|1@1+ (1,0) [0|0] "" X
 SG_ CHG_w116_HVJBOT: 51|1@1+ (1,0) [0|0] "" X
 SG_ CHG_w117_HVJBOTFault: 52|1@1+ (1,0) [0|0] "" X
 SG_ CHG_w118_VDiffHwRationality: 53|1@1+ (1,0) [0|0] "" X
 SG_ CHG_w119_FCNotClosed: 54|1@1+ (1,0) [0|0] "" X
 SG_ CHG_w120_HVJB_powerFault: 55|1@1+ (1,0) [0|0] "" X
 SG_ CHG_w121_crashDetected: 56|1@1+ (1,0) [0|0] "" X
 SG_ CHG_w122_dioRationality: 57|1@1+ (1,0) [0|0] "" X
 SG_ CHG_w123_liveCableDisconnect: 58|1@1+ (1,0) [0|0] "" X
 SG_ CHG_w124_ph3VersionMismatch: 59|1@1+ (1,0) [0|0] "" X
 SG_ CHG_w125_leakageTestFailure: 60|1@1+ (1,0) [0|0] "" X
 SG_ CHG_w126_allPhasesMIA: 61|1@1+ (1,0) [0|0] "" X
 SG_ CHG_w127_hvCableBadPolarity: 62|1@1+ (1,0) [0|0] "" X
 SG_ CHG_w128_leakageTestLow: 63|1@1+ (1,0) [0|0] "" X

BO_ 1555 CMP_udsResponse: 8 ETH
 SG_ CMP_udsResponseData: 0|54@0+ (1024,0) [0|0] "" X

BO_ 867 CMP_version: 8 ETH
 SG_ CMP_appAssemblyID: 32|8@1+ (1,0) [0|0] "" X
 SG_ CMP_appPCBAID: 24|8@1+ (1,0) [0|0] "" X
 SG_ CMP_appUsageID: 40|16@1+ (1,0) [0|0] "" X
 SG_ CMP_componentBranchOrigin: 8|8@1+ (1,0) [0|0] "" X
 SG_ CMP_componentMajorVersion: 0|8@1+ (1,0) [0|0] "" X
 SG_ CMP_componentMaturity: 16|8@1+ (1,0) [0|0] "" X

BO_ 1342 CP_info: 8 ETH
 SG_ CP_infoIndex M: 0|8@1+ (1,0) [0|0] "" X
 SG_ CP_buildType m10: 8|8@1+ (1,0) [0|0] "" X
 SG_ CP_buildConfigId m10: 16|16@1+ (1,0) [0|0] "" X
 SG_ CP_hardwareId m10: 32|16@1+ (1,0) [0|0] "" X
 SG_ CP_componentId m10: 48|16@1+ (1,0) [0|0] "" X
 SG_ CP_pcbaId m11: 16|8@1+ (1,0) [0|0] "" X
 SG_ CP_assemblyId m11: 24|8@1+ (1,0) [0|0] "" X
 SG_ CP_usageId m11: 32|16@1+ (1,0) [0|0] "" X
 SG_ CP_subUsageId m11: 48|16@1+ (1,0) [0|0] "" X
 SG_ CP_platformType m13: 8|8@1+ (1,0) [0|0] "" X
 SG_ CP_appCrc m13: 32|32@1+ (1,0) [0|0] "" X
 SG_ CP_bootSvnRev m14: 8|24@1+ (1,0) [0|0] "" X
 SG_ CP_bootSvnUrlHash m14: 32|32@1+ (1,0) [0|0] "" X
 SG_ CP_appGitHash m17: 10|54@1+ (4,0) [0|0] "" X
 SG_ CP_bootGitHash m18: 10|54@1+ (4,0) [0|0] "" X
 SG_ CP_bootUdsProtoVersion m20: 8|8@1+ (1,0) [0|0] "" X
 SG_ CP_bootCrc m20: 32|32@1+ (1,0) [0|0] "" X

BO_ 20 CP_status: 8 ETH
 SG_ CP_apsVoltage: 32|8@1+ (0.0715686,0) [0|0] "V" X
 SG_ CP_chargeCablePresent: 52|1@1+ (1,0) [0|0] "" X
 SG_ CP_chargeCableSecured: 53|1@1+ (1,0) [0|0] "" X
 SG_ CP_chargeDoorOpen: 0|1@1+ (1,0) [0|0] "" X
 SG_ CP_chargeDoorOpenUI: 59|1@1+ (1,0) [0|0] "" X
 SG_ CP_connectorBlocked: 50|1@1+ (1,0) [0|0] "" X
 SG_ CP_connectorLatched: 9|1@1+ (1,0) [0|0] "" X
 SG_ CP_coverClosed: 14|1@1+ (1,0) [0|0] "" X
 SG_ CP_doorButtonPressed: 16|1@1+ (1,0) [0|0] "" X
 SG_ CP_doorControlState: 21|4@1+ (1,0) [0|0] "" X
 SG_ CP_faultLineSensed: 61|1@1+ (1,0) [0|0] "" X
 SG_ CP_inductiveDoorState: 25|3@1+ (1,0) [0|0] "" X
 SG_ CP_inductiveSensorState: 5|4@1+ (1,0) [0|0] "" X
 SG_ CP_insertEnableLine: 4|1@1+ (1,0) [0|0] "" X
 SG_ CP_isMotorized: 51|1@1+ (1,0) [0|0] "" X
 SG_ CP_latch2ControlState: 56|3@1+ (1,0) [0|0] "" X
 SG_ CP_latch2State: 54|2@1+ (1,0) [0|0] "" X
 SG_ CP_latchControlState: 17|4@1+ (1,0) [0|0] "" X
 SG_ CP_latchEnableCmd: 15|1@1+ (1,0) [0|0] "" X
 SG_ CP_latchState: 48|2@1+ (1,0) [0|0] "" X
 SG_ CP_ledColor: 10|4@1+ (1,0) [0|0] "" X
 SG_ CP_leverMoved: 1|1@1+ (1,0) [0|0] "" X
 SG_ CP_numAlertsSet: 40|7@1+ (1,0) [0|0] "" X
 SG_ CP_swcanRelayClosed: 60|1@1+ (1,0) [0|0] "" X
 SG_ CP_type: 2|2@1+ (1,0) [0|0] "" X

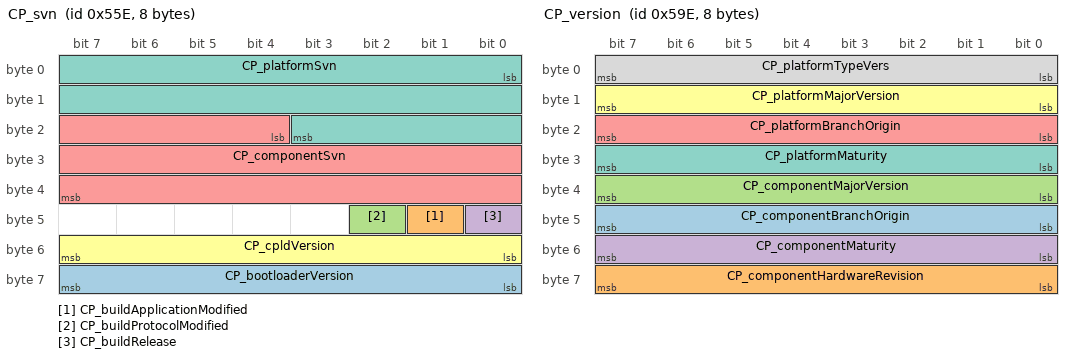
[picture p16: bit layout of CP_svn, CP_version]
BO_ 1374 CP_svn: 8 ETH
 SG_ CP_bootloaderVersion: 56|8@1+ (1,0) [0|0] "" X
 SG_ CP_buildApplicationModified: 41|1@1+ (1,0) [0|0] "" X
 SG_ CP_buildProtocolModified: 42|1@1+ (1,0) [0|0] "" X
 SG_ CP_buildRelease: 40|1@1+ (1,0) [0|0] "" X
 SG_ CP_componentSvn: 20|20@1+ (1,0) [0|0] "" X
 SG_ CP_cpldVersion: 48|8@1+ (1,0) [0|0] "" X
 SG_ CP_platformSvn: 0|20@1+ (1,0) [0|0] "" X

BO_ 1566 CP_udsResponse: 8 ETH
 SG_ CP_udsResponseData: 0|54@0+ (1024,0) [0|0] "" X

BO_ 1438 CP_version: 8 ETH
 SG_ CP_componentBranchOrigin: 40|8@1+ (1,0) [0|0] "" X
 SG_ CP_componentHardwareRevision: 56|8@1+ (1,0) [0|0] "" X
 SG_ CP_componentMajorVersion: 32|8@1+ (1,0) [0|0] "" X
 SG_ CP_componentMaturity: 48|8@1+ (1,0) [0|0] "" X
 SG_ CP_platformBranchOrigin: 16|8@1+ (1,0) [0|0] "" X
 SG_ CP_platformMajorVersion: 8|8@1+ (1,0) [0|0] "" X
 SG_ CP_platformMaturity: 24|8@1+ (1,0) [0|0] "" X
 SG_ CP_platformTypeVers: 0|8@1+ (1,0) [0|0] "" X

BO_ 40 CP_warningMatrix: 8 ETH
 SG_ CP_matrixIndex M: 0|4@1+ (1,0) [0|0] "" X
 SG_ CP_w001_canRx m0: 4|1@1+ (1,0) [0|0] "" X
 SG_ CP_w002_canTx m0: 5|1@1+ (1,0) [0|0] "" X
 SG_ CP_w003_canError m0: 6|1@1+ (1,0) [0|0] "" X
 SG_ CP_w004_proximityRationality m0: 7|1@1+ (1,0) [0|0] "" X
 SG_ CP_w005_gbdcLiveDisconnect m0: 8|1@1+ (1,0) [0|0] "" X
 SG_ CP_w006_lostCommsBMS m0: 9|1@1+ (1,0) [0|0] "" X
 SG_ CP_w007_watchdog m0: 10|1@1+ (1,0) [0|0] "" X
 SG_ CP_w008_memoryError m0: 11|1@1+ (1,0) [0|0] "" X
 SG_ CP_w009_coverOpen m0: 12|1@1+ (1,0) [0|0] "" X
 SG_ CP_w010_pilotRationality m0: 13|1@1+ (1,0) [0|0] "" X
 SG_ CP_w011_eeprom m0: 14|1@1+ (1,0) [0|0] "" X
 SG_ CP_w012_ledDriver m0: 15|1@1+ (1,0) [0|0] "" X
 SG_ CP_w013_lostCommsGTW m0: 16|1@1+ (1,0) [0|0] "" X
 SG_ CP_w014_lostCommsCHG m0: 17|1@1+ (1,0) [0|0] "" X
 SG_ CP_w015_apsVov m0: 18|1@1+ (1,0) [0|0] "" X
 SG_ CP_w016_apsVuv m0: 19|1@1+ (1,0) [0|0] "" X
 SG_ CP_w017_fiveVov m0: 20|1@1+ (1,0) [0|0] "" X
 SG_ CP_w018_fiveVuv m0: 21|1@1+ (1,0) [0|0] "" X
 SG_ CP_w019_threeVov m0: 22|1@1+ (1,0) [0|0] "" X
 SG_ CP_w020_threeVuv m0: 23|1@1+ (1,0) [0|0] "" X
 SG_ CP_w021_zeroVov m0: 24|1@1+ (1,0) [0|0] "" X
 SG_ CP_w022_zeroVuv m0: 25|1@1+ (1,0) [0|0] "" X
 SG_ CP_w023_gbdcSessionFailed m0: 26|1@1+ (1,0) [0|0] "" X
 SG_ CP_w024_ledsUC m0: 27|1@1+ (1,0) [0|0] "" X
 SG_ CP_w025_ledsOC m0: 28|1@1+ (1,0) [0|0] "" X
 SG_ CP_w026_networkManagement m0: 29|1@1+ (1,0) [0|0] "" X
 SG_ CP_w027_doorSensorOutOfSpec m0: 30|1@1+ (1,0) [0|0] "" X
 SG_ CP_w028_insertEnableMismatch m0: 31|1@1+ (1,0) [0|0] "" X
 SG_ CP_w029_doorClosedProxPilot m0: 32|1@1+ (1,0) [0|0] "" X
 SG_ CP_w030_busOff m0: 33|1@1+ (1,0) [0|0] "" X
 SG_ CP_w031_doorClosedCommandedOpen m0: 34|1@1+ (1,0) [0|0] "" X
 SG_ CP_w032_doorOpenExpectedClosed m0: 35|1@1+ (1,0) [0|0] "" X
 SG_ CP_w033_spiOpen m0: 36|1@1+ (1,0) [0|0] "" X
 SG_ CP_w034_calibrationIncomplete m0: 37|1@1+ (1,0) [0|0] "" X
 SG_ CP_w035_latchMovement_1 m0: 38|1@1+ (1,0) [0|0] "" X
 SG_ CP_w036_latchNotDisengaged m0: 39|1@1+ (1,0) [0|0] "" X
 SG_ CP_w037_latchNotEngaged m0: 40|1@1+ (1,0) [0|0] "" X
 SG_ CP_w038_latchNotBlocking m0: 41|1@1+ (1,0) [0|0] "" X
 SG_ CP_w039_latchMovement_2 m0: 42|1@1+ (1,0) [0|0] "" X
 SG_ CP_w040_doNotUse m0: 43|1@1+ (1,0) [0|0] "" X
 SG_ CP_w041_doorSensorUnplugged m0: 44|1@1+ (1,0) [0|0] "" X
 SG_ CP_w042_doorAssemblyBroken m0: 45|1@1+ (1,0) [0|0] "" X
 SG_ CP_w043_doorPotIrrational m0: 46|1@1+ (1,0) [0|0] "" X
 SG_ CP_w044_lostCommsHVP m0: 47|1@1+ (1,0) [0|0] "" X
 SG_ CP_w045_lostCommsVCSEC m0: 48|1@1+ (1,0) [0|0] "" X
 SG_ CP_w046_lostCommsEVSE m0: 49|1@1+ (1,0) [0|0] "" X
 SG_ CP_w047_lostCommsVCFRONT m0: 50|1@1+ (1,0) [0|0] "" X
 SG_ CP_w048_lostCommsUI m0: 51|1@1+ (1,0) [0|0] "" X
 SG_ CP_w049_multipleCablesDetected m0: 52|1@1+ (1,0) [0|0] "" X
 SG_ CP_w050_latchNotConnected m0: 53|1@1+ (1,0) [0|0] "" X
 SG_ CP_w051_doorInductiveSensorMIA m0: 54|1@1+ (1,0) [0|0] "" X
 SG_ CP_w052_evseNotSupported m0: 55|1@1+ (1,0) [0|0] "" X
 SG_ CP_w053_proxLatchedNoPilot m0: 56|1@1+ (1,0) [0|0] "" X
 SG_ CP_w054_cableNotSecured m0: 57|1@1+ (1,0) [0|0] "" X
 SG_ CP_w055_chargeStoppedNoPilot m0: 58|1@1+ (1,0) [0|0] "" X
 SG_ CP_w056_proxDisconnected m0: 59|1@1+ (1,0) [0|0] "" X
 SG_ CP_w057_evseFaulted m0: 60|1@1+ (1,0) [0|0] "" X
 SG_ CP_w058_acChargingBlocked m0: 61|1@1+ (1,0) [0|0] "" X
 SG_ CP_w059_swcanError m0: 62|1@1+ (1,0) [0|0] "" X
 SG_ CP_w060_lostCommsPCS m0: 63|1@1+ (1,0) [0|0] "" X
 SG_ CP_w061_uhfReceiverMIA m1: 4|1@1+ (1,0) [0|0] "" X
 SG_ CP_w062_scOutOfService m1: 5|1@1+ (1,0) [0|0] "" X
 SG_ CP_w063_scUpdateInProgress m1: 6|1@1+ (1,0) [0|0] "" X
 SG_ CP_w064_superchargingBlocked m1: 7|1@1+ (1,0) [0|0] "" X
 SG_ CP_w065_selfTestFailed m1: 8|1@1+ (1,0) [0|0] "" X
 SG_ CP_w066_proxLatchedIdlePilot m1: 9|1@1+ (1,0) [0|0] "" X
 SG_ CP_w067_gbdcConnFault m1: 10|1@1+ (1,0) [0|0] "" X
 SG_ CP_w068_doorSensorMismatch m1: 11|1@1+ (1,0) [0|0] "" X
 SG_ CP_w069_doorInductiveSensorError m1: 12|1@1+ (1,0) [0|0] "" X
 SG_ CP_w070_doorInductiveSensorReset m1: 13|1@1+ (1,0) [0|0] "" X
 SG_ CP_w071_LDC1612errorWatchdog m1: 14|1@1+ (1,0) [0|0] "" X
 SG_ CP_w072_latchNotDisengagedCold m1: 15|1@1+ (1,0) [0|0] "" X
 SG_ CP_w073_cableNotSecuredCold m1: 16|1@1+ (1,0) [0|0] "" X

BO_ 129 CTRL_U_A2: 4 ETH
 SG_ DispBrt_IC: 8|8@1+ (1,0) [0|0] "%" X
 SG_ SwIllLvl: 0|8@1+ (1,0) [0|0] "%" X

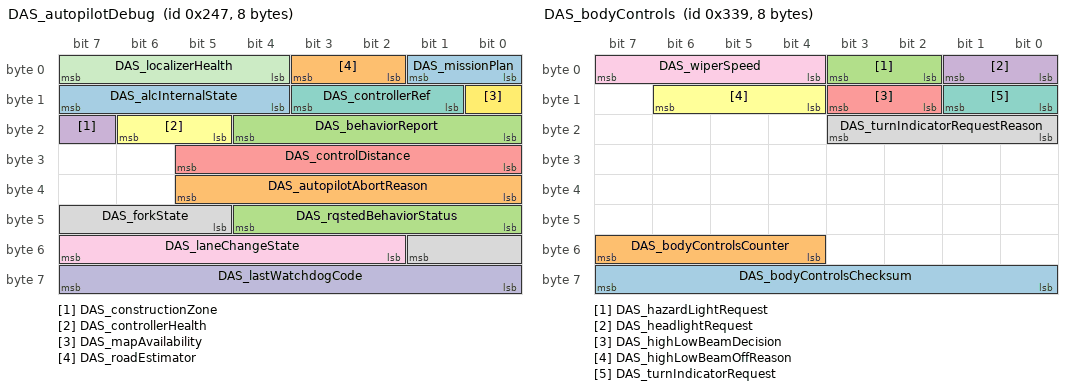
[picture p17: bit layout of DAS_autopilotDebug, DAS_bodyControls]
BO_ 583 DAS_autopilotDebug: 8 ETH
 SG_ DAS_alcInternalState: 12|4@1+ (1,0) [0|0] "" X
 SG_ DAS_autopilotAbortReason: 32|6@1+ (1,0) [0|0] "" X
 SG_ DAS_behaviorReport: 16|5@1+ (1,0) [0|0] "" X
 SG_ DAS_constructionZone: 23|1@1+ (1,0) [0|0] "" X
 SG_ DAS_controlDistance: 24|6@1+ (2,0) [0|0] "m" X
 SG_ DAS_controllerHealth: 21|2@1+ (1,0) [0|0] "" X
 SG_ DAS_controllerRef: 9|3@1+ (1,0) [0|0] "" X
 SG_ DAS_forkState: 45|5@1+ (1,0) [0|0] "" X
 SG_ DAS_laneChangeState: 50|6@1+ (1,0) [0|0] "" X
 SG_ DAS_lastWatchdogCode: 56|8@1+ (1,0) [0|0] "" X
 SG_ DAS_localizerHealth: 4|4@1+ (1,0) [0|0] "" X
 SG_ DAS_mapAvailability: 8|1@1+ (1,0) [0|0] "" X
 SG_ DAS_missionPlan: 0|2@1+ (1,0) [0|0] "" X
 SG_ DAS_roadEstimator: 2|2@1+ (1,0) [0|0] "" X
 SG_ DAS_rqstedBehaviorStatus: 40|5@1+ (1,0) [0|0] "" X

BO_ 825 DAS_bodyControls: 8 ETH
 SG_ DAS_bodyControlsChecksum: 56|8@1+ (1,0) [0|0] "" X
 SG_ DAS_bodyControlsCounter: 52|4@1+ (1,0) [0|0] "" X
 SG_ DAS_hazardLightRequest: 2|2@1+ (1,0) [0|0] "" X
 SG_ DAS_headlightRequest: 0|2@1+ (1,0) [0|0] "" X
 SG_ DAS_highLowBeamDecision: 10|2@1+ (1,0) [0|0] "" X
 SG_ DAS_highLowBeamOffReason: 12|3@1+ (1,0) [0|0] "" X
 SG_ DAS_turnIndicatorRequest: 8|2@1+ (1,0) [0|0] "" X
 SG_ DAS_turnIndicatorRequestReason: 16|4@1+ (1,0) [0|0] "" X
 SG_ DAS_wiperSpeed: 4|4@1+ (1,0) [0|0] "" X

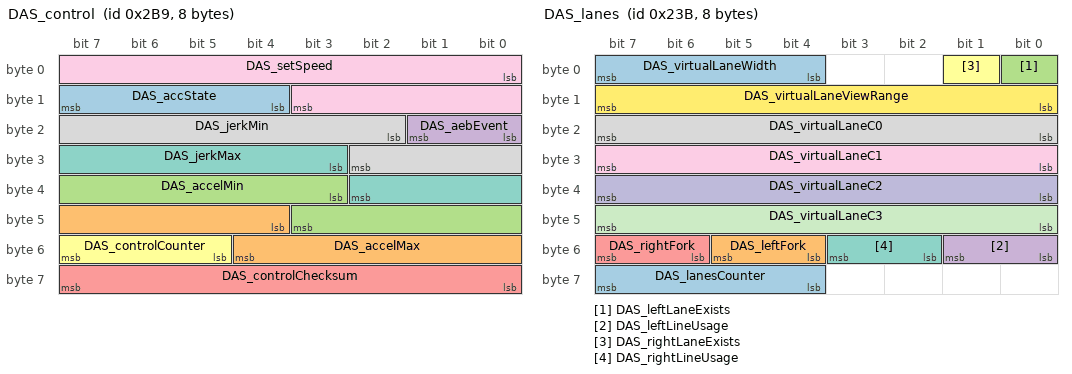
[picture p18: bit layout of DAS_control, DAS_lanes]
BO_ 697 DAS_control: 8 ETH
 SG_ DAS_accState: 12|4@1+ (1,0) [0|0] "" X
 SG_ DAS_accelMax: 44|9@1+ (0.04,-15) [0|0] "m/s^2" X
 SG_ DAS_accelMin: 35|9@1+ (0.04,-15) [0|0] "m/s^2" X
 SG_ DAS_aebEvent: 16|2@1+ (1,0) [0|0] "" X
 SG_ DAS_controlChecksum: 56|8@1+ (1,0) [0|0] "" X
 SG_ DAS_controlCounter: 53|3@1+ (1,0) [0|0] "" X
 SG_ DAS_jerkMax: 27|8@1+ (0.034,0) [0|0] "m/s^3" X
 SG_ DAS_jerkMin: 18|9@1+ (0.018,-9.1) [0|0] "m/s^3" X
 SG_ DAS_setSpeed: 0|12@1+ (0.1,0) [0|0] "kph" X

BO_ 1641 DAS_dtcMatrix: 8 ETH
 SG_ DAS_dtcMultiplex M: 0|8@1+ (1,0) [0|0] "" X
 SG_ DAS_d001_unused m0: 8|2@1+ (1,0) [0|0] "" X

BO_ 1338 DAS_info: 8 ETH
 SG_ DAS_infoIndex M: 0|8@1+ (1,0) [0|0] "" X
 SG_ DAS_infoBuildType m10: 8|8@1+ (1,0) [0|0] "" X
 SG_ DAS_infoBuildConfigID m10: 16|16@1+ (1,0) [0|0] "" X
 SG_ DAS_infoHardwareID m10: 32|16@1+ (1,0) [0|0] "" X
 SG_ DAS_infoComponentID m10: 48|16@1+ (1,0) [0|0] "" X
 SG_ DAS_infoPcbaID m11: 16|8@1+ (1,0) [0|0] "" X
 SG_ DAS_infoAssemblyID m11: 24|8@1+ (1,0) [0|0] "" X
 SG_ DAS_infoUsageID m11: 32|16@1+ (1,0) [0|0] "" X
 SG_ DAS_infoSubUsageID m11: 48|16@1+ (1,0) [0|0] "" X
 SG_ DAS_infoApplicationCRC m13: 32|32@1+ (1,0) [0|0] "" X
 SG_ DAS_infoBootloaderSvnRevision m14: 8|24@1+ (1,0) [0|0] "" X
 SG_ DAS_infoEyeQBootCRC m16: 16|32@1+ (1,0) [0|0] "" X
 SG_ DAS_infoAppGitHashBytes m17: 10|54@1+ (4,0) [0|0] "" X
 SG_ DAS_infoBootGitHashBytes m18: 10|54@1+ (4,0) [0|0] "" X
 SG_ DAS_infoPlatformType m19: 8|8@1+ (1,0) [0|0] "" X
 SG_ DAS_infoMajorVersion m19: 16|8@1+ (1,0) [0|0] "" X
 SG_ DAS_infoBranchOrigin m19: 24|8@1+ (1,0) [0|0] "" X
 SG_ DAS_infoMaturity m19: 32|8@1+ (1,0) [0|0] "" X
 SG_ DAS_infoHardwareRevision m19: 40|8@1+ (1,0) [0|0] "" X
 SG_ DAS_infoBootUdsProtoVersion m20: 8|8@1+ (1,0) [0|0] "" X
 SG_ DAS_infoBootloaderCRC m20: 32|32@1+ (1,0) [0|0] "" X
 SG_ DAS_infoEyeQAppCRC m23: 16|32@1+ (1,0) [0|0] "" X
 SG_ DAS_infoEyeQFfsCRC m24: 16|32@1+ (1,0) [0|0] "" X

BO_ 571 DAS_lanes: 8 ETH
 SG_ DAS_lanesCounter: 60|4@1+ (1,0) [0|0] "" X
 SG_ DAS_leftFork: 52|2@1+ (1,0) [0|0] "" X
 SG_ DAS_leftLaneExists: 0|1@1+ (1,0) [0|0] "" X
 SG_ DAS_leftLineUsage: 48|2@1+ (1,0) [0|0] "" X
 SG_ DAS_rightFork: 54|2@1+ (1,0) [0|0] "" X
 SG_ DAS_rightLaneExists: 1|1@1+ (1,0) [0|0] "" X
 SG_ DAS_rightLineUsage: 50|2@1+ (1,0) [0|0] "" X
 SG_ DAS_virtualLaneC0: 16|8@1+ (0.035,-3.5) [0|0] "m" X
 SG_ DAS_virtualLaneC1: 24|8@1+ (0.0016,-0.2) [0|0] "rad" X
 SG_ DAS_virtualLaneC2: 32|8@1+ (2e-05,-0.0025) [0|0] "m-1" X
 SG_ DAS_virtualLaneC3: 40|8@1+ (2.4e-07,-3e-05) [0|0] "m-2" X
 SG_ DAS_virtualLaneViewRange: 8|8@1+ (1,0) [0|0] "m" X
 SG_ DAS_virtualLaneWidth: 4|4@1+ (0.3125,2) [0|0] "m" X

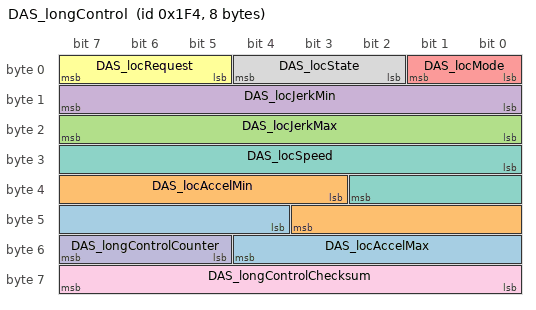
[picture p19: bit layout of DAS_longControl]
BO_ 500 DAS_longControl: 8 ETH
 SG_ DAS_locAccelMax: 44|9@1+ (0.04,-15) [0|0] "m/s^2" X
 SG_ DAS_locAccelMin: 35|9@1+ (0.04,-15) [0|0] "m/s^2" X
 SG_ DAS_locJerkMax: 16|8@1+ (0.034,0) [0|0] "m/s^3" X
 SG_ DAS_locJerkMin: 8|8@1+ (0.034,-8.67) [0|0] "m/s^3" X
 SG_ DAS_locMode: 0|2@1+ (1,0) [0|0] "" X
 SG_ DAS_locRequest: 5|3@1+ (1,0) [0|0] "" X
 SG_ DAS_locSpeed: 24|11@1+ (0.1,0) [0|0] "kph" X
 SG_ DAS_locState: 2|3@1+ (1,0) [0|0] "" X
 SG_ DAS_longControlChecksum: 56|8@1+ (1,0) [0|0] "" X
 SG_ DAS_longControlCounter: 53|3@1+ (1,0) [0|0] "" X

BO_ 1027 DAS_object: 8 ETH
 SG_ DAS_objectId M: 0|3@1+ (1,0) [0|0] "" X
 SG_ DAS_leadVehType m0: 3|3@1+ (1,0) [0|0] "" X
 SG_ DAS_leadVehRelevantForControl m0: 7|1@1+ (1,0) [0|0] "" X
 SG_ DAS_leadVehDx m0: 8|8@1+ (0.5,0) [0|0] "m" X
 SG_ DAS_leadVehVxRel m0: 16|4@1+ (4,-30) [0|0] "m/s" X
 SG_ DAS_leadVehDy m0: 20|7@1+ (0.35,-22.05) [0|0] "m" X
 SG_ DAS_leadVehId m0: 27|7@1+ (1,0) [0|0] "" X
 SG_ DAS_leadVeh2Type m0: 34|3@1+ (1,0) [0|0] "" X
 SG_ DAS_leadVeh2RelevantForControl m0: 38|1@1+ (1,0) [0|0] "" X
 SG_ DAS_leadVeh2Dx m0: 39|8@1+ (0.5,0) [0|0] "m" X
 SG_ DAS_leadVeh2VxRel m0: 47|4@1+ (4,-30) [0|0] "m/s" X
 SG_ DAS_leadVeh2Dy m0: 51|7@1+ (0.35,-22.05) [0|0] "m" X
 SG_ DAS_leadVeh2Id m0: 58|6@1+ (1,0) [0|0] "" X
 SG_ DAS_leftVehType m1: 3|3@1+ (1,0) [0|0] "" X
 SG_ DAS_leftVehRelevantForControl m1: 7|1@1+ (1,0) [0|0] "" X
 SG_ DAS_leftVehDx m1: 8|8@1+ (0.5,0) [0|0] "m" X
 SG_ DAS_leftVehVxRel m1: 16|4@1+ (4,-30) [0|0] "m/s" X
 SG_ DAS_leftVehDy m1: 20|7@1+ (0.35,-22.05) [0|0] "m" X
 SG_ DAS_leftVehId m1: 27|7@1+ (1,0) [0|0] "" X
 SG_ DAS_leftVeh2Type m1: 34|3@1+ (1,0) [0|0] "" X
 SG_ DAS_leftVeh2RelevantForControl m1: 38|1@1+ (1,0) [0|0] "" X
 SG_ DAS_leftVeh2Dx m1: 39|8@1+ (0.5,0) [0|0] "m" X
 SG_ DAS_leftVeh2VxRel m1: 47|4@1+ (4,-30) [0|0] "m/s" X
 SG_ DAS_leftVeh2Dy m1: 51|7@1+ (0.35,-22.05) [0|0] "m" X
 SG_ DAS_leftVeh2Id m1: 58|6@1+ (1,0) [0|0] "" X
 SG_ DAS_rightVehType m2: 3|3@1+ (1,0) [0|0] "" X
 SG_ DAS_rightVehRelevantForControl m2: 7|1@1+ (1,0) [0|0] "" X
 SG_ DAS_rightVehDx m2: 8|8@1+ (0.5,0) [0|0] "m" X
 SG_ DAS_rightVehVxRel m2: 16|4@1+ (4,-30) [0|0] "m/s" X
 SG_ DAS_rightVehDy m2: 20|7@1+ (0.35,-22.05) [0|0] "m" X
 SG_ DAS_rightVehId m2: 27|7@1+ (1,0) [0|0] "" X
 SG_ DAS_rightVeh2Type m2: 34|3@1+ (1,0) [0|0] "" X
 SG_ DAS_rightVeh2RelevantForControl m2: 38|1@1+ (1,0) [0|0] "" X
 SG_ DAS_rightVeh2Dx m2: 39|8@1+ (0.5,0) [0|0] "m" X
 SG_ DAS_rightVeh2VxRel m2: 47|4@1+ (4,-30) [0|0] "m/s" X
 SG_ DAS_rightVeh2Dy m2: 51|7@1+ (0.35,-22.05) [0|0] "m" X
 SG_ DAS_rightVeh2Id m2: 58|6@1+ (1,0) [0|0] "" X
 SG_ DAS_cutinVehType m3: 3|3@1+ (1,0) [0|0] "" X
 SG_ DAS_cutinVehRelevantForControl m3: 7|1@1+ (1,0) [0|0] "" X
 SG_ DAS_cutinVehDx m3: 8|8@1+ (0.5,0) [0|0] "m" X
 SG_ DAS_cutinVehVxRel m3: 16|4@1+ (4,-30) [0|0] "m/s" X
 SG_ DAS_cutinVehDy m3: 20|7@1+ (0.35,-22.05) [0|0] "m" X
 SG_ DAS_cutinVehId m3: 27|7@1+ (1,0) [0|0] "" X
 SG_ DAS_roadSignColor m4: 3|3@1+ (1,0) [0|0] "" X
 SG_ DAS_roadSignId m4: 6|8@1+ (1,0) [0|0] "" X
 SG_ DAS_roadSignStopLineDist m4: 14|10@1+ (0.2,-20) [0|0] "m" X
 SG_ DAS_roadSignControlActive m4: 24|1@1+ (1,0) [0|0] "" X
 SG_ DAS_roadSignSource m4: 25|2@1+ (1,0) [0|0] "" X
 SG_ DAS_roadSignArrow m4: 27|3@1+ (1,0) [0|0] "" X
 SG_ DAS_roadSignOrientation m4: 30|2@1+ (1,0) [0|0] "" X
 SG_ DAS_leadVehHeading m5: 8|8@1+ (0.0245437,-3.14159) [0|0] "rad" X
 SG_ DAS_leadVeh2Heading m5: 16|8@1+ (0.0245437,-3.14159) [0|0] "rad" X
 SG_ DAS_leftVehHeading m5: 24|8@1+ (0.0245437,-3.14159) [0|0] "rad" X
 SG_ DAS_leftVeh2Heading m5: 32|8@1+ (0.0245437,-3.14159) [0|0] "rad" X
 SG_ DAS_rightVehHeading m5: 40|8@1+ (0.0245437,-3.14159) [0|0] "rad" X
 SG_ DAS_rightVeh2Heading m5: 48|8@1+ (0.0245437,-3.14159) [0|0] "rad" X
 SG_ DAS_cutinVehHeading m5: 56|8@1+ (0.0245437,-3.14159) [0|0] "rad" X

BO_ 921 DAS_status: 8 ETH
 SG_ DAS_autoLaneChangeState: 46|5@1+ (1,0) [0|0] "" X
 SG_ DAS_autoParked: 25|1@1+ (1,0) [0|0] "" X
 SG_ DAS_autoparkReady: 24|1@1+ (1,0) [0|0] "" X
 SG_ DAS_autoparkWaitingForBrake: 26|1@1+ (1,0) [0|0] "" X
 SG_ DAS_autopilotHandsOnState: 42|4@1+ (1,0) [0|0] "" X
 SG_ DAS_autopilotState: 0|4@1+ (1,0) [0|0] "" X
 SG_ DAS_blindSpotRearLeft: 4|2@1+ (1,0) [0|0] "" X
 SG_ DAS_blindSpotRearRight: 6|2@1+ (1,0) [0|0] "" X
 SG_ DAS_csaState: 35|2@1+ (1,0) [0|0] "" X
 SG_ DAS_fleetSpeedState: 40|2@1+ (1,0) [0|0] "" X
 SG_ DAS_forwardCollisionWarning: 22|2@1+ (1,0) [0|0] "" X
 SG_ DAS_fusedSpeedLimit: 8|5@1+ (5,0) [0|0] "kph/mph" X
 SG_ DAS_heaterState: 21|1@1+ (1,0) [0|0] "" X
 SG_ DAS_hvacPowerRequest: 27|1@1+ (1,0) [0|0] "" X
 SG_ DAS_laneDepartureWarning: 37|3@1+ (1,0) [0|0] "" X
 SG_ DAS_sideCollisionAvoid: 30|2@1+ (1,0) [0|0] "" X
 SG_ DAS_sideCollisionInhibit: 34|1@1+ (1,0) [0|0] "" X
 SG_ DAS_sideCollisionWarning: 32|2@1+ (1,0) [0|0] "" X
 SG_ DAS_statusChecksum: 56|8@1+ (1,0) [0|0] "" X
 SG_ DAS_statusCounter: 52|4@1+ (1,0) [0|0] "" X
 SG_ DAS_summonAvailable: 51|1@1+ (1,0) [0|0] "" X
 SG_ DAS_summonClearedGate: 15|1@1+ (1,0) [0|0] "" X
 SG_ DAS_summonFwdLeashReached: 28|1@1+ (1,0) [0|0] "" X
 SG_ DAS_summonObstacle: 14|1@1+ (1,0) [0|0] "" X
 SG_ DAS_summonRvsLeashReached: 29|1@1+ (1,0) [0|0] "" X
 SG_ DAS_suppressSpeedWarning: 13|1@1+ (1,0) [0|0] "" X
 SG_ DAS_visionOnlySpeedLimit: 16|5@1+ (5,0) [0|0] "kph/mph" X

BO_ 905 DAS_status2: 8 ETH
 SG_ DAS_ACC_report: 26|5@1+ (1,0) [0|0] "" X
 SG_ DAS_accSpeedLimit: 0|10@1+ (0.2,0) [0|0] "mph" X
 SG_ DAS_activationFailureStatus: 14|2@1+ (1,0) [0|0] "" X
 SG_ DAS_driverInteractionLevel: 38|2@1+ (1,0) [0|0] "" X
 SG_ DAS_longCollisionWarning: 48|4@1+ (1,0) [0|0] "" X
 SG_ DAS_lssState: 31|3@1+ (1,0) [0|0] "" X
 SG_ DAS_pmmCameraFaultReason: 24|2@1+ (1,0) [0|0] "" X
 SG_ DAS_pmmLoggingRequest: 13|1@1+ (1,0) [0|0] "" X
 SG_ DAS_pmmObstacleSeverity: 10|3@1+ (1,0) [0|0] "" X
 SG_ DAS_pmmRadarFaultReason: 19|2@1+ (1,0) [0|0] "" X
 SG_ DAS_pmmSysFaultReason: 21|3@1+ (1,0) [0|0] "" X
 SG_ DAS_pmmUltrasonicsFaultReason: 16|3@1+ (1,0) [0|0] "" X
 SG_ DAS_ppOffsetDesiredRamp: 40|8@1+ (0.01,-1.28) [0|0] "m" X
 SG_ DAS_radarTelemetry: 34|2@1+ (1,0) [0|0] "" X
 SG_ DAS_robState: 36|2@1+ (1,0) [0|0] "" X
 SG_ DAS_status2Checksum: 56|8@1+ (1,0) [0|0] "" X
 SG_ DAS_status2Counter: 52|4@1+ (1,0) [0|0] "" X

BO_ 434 DAS_telemetry: 8 ETH
 SG_ DAS_telemetryMultiplexer M: 0|8@1+ (1,0) [0|0] "" X
 SG_ DAS_telLeftLaneType m0: 8|3@1+ (1,0) [0|0] "" X
 SG_ DAS_telRightLaneType m0: 11|3@1+ (1,0) [0|0] "" X
 SG_ DAS_telLeftMarkerQuality m0: 14|2@1+ (1,0) [0|0] "" X
 SG_ DAS_telRightMarkerQuality m0: 16|2@1+ (1,0) [0|0] "" X
 SG_ DAS_telLeftMarkerColor m0: 18|2@1+ (1,0) [0|0] "" X
 SG_ DAS_telRightMarkerColor m0: 20|2@1+ (1,0) [0|0] "" X
 SG_ DAS_telLeftLaneCrossing m0: 22|1@1+ (1,0) [0|0] "" X
 SG_ DAS_telRightLaneCrossing m0: 23|1@1+ (1,0) [0|0] "" X
 SG_ DAS_MCPObserved m1: 8|1@1+ (1,0) [0|0] "" X
 SG_ DAS_accReengaged m1: 9|1@1+ (1,0) [0|0] "" X
 SG_ DAS_pedestrianInFOVBeforeIntr m1: 10|1@1+ (1,0) [0|0] "" X
 SG_ DAS_pedestrianInFOVAfterIntr m1: 11|1@1+ (1,0) [0|0] "" X
 SG_ DAS_camFreeSpaceBeforeIntr m1: 12|1@1+ (1,0) [0|0] "" X
 SG_ DAS_camFreeSpaceAfterIntr m1: 13|1@1+ (1,0) [0|0] "" X
 SG_ DAS_timeOfIntervention m1: 14|6@1+ (0.25,0) [0|0] "s" X
 SG_ DAS_timeOfFirstPedestrian m1: 20|6@1+ (0.25,0) [0|0] "s" X
 SG_ DAS_timeOfACCReengaging m1: 26|6@1+ (0.25,0) [0|0] "s" X
 SG_ DAS_durationOfPrevACCStandstill m1: 32|6@1+ (0.5,0) [0|0] "s" X
 SG_ DAS_maxAbsSteeringWheelAngle m1: 38|7@1+ (2,0) [0|0] "degrees" X
 SG_ DAS_targetRelvelAtIntervention m1: 45|6@1+ (0.25,-2) [0|0] "m/s" X
 SG_ DAS_targetDistAtIntervention m1: 51|6@1+ (0.5,0) [0|0] "m" X
 SG_ DAS_egoSpeedAtIntervention m1: 57|6@1+ (0.5,0) [0|0] "m/s" X
 SG_ DAS_stopSignLongitudinalDist m2: 8|10@1+ (0.1,0) [0|0] "m" X
 SG_ DAS_stopSignLateralDist m2: 18|8@1+ (0.25,-32) [0|0] "m" X
 SG_ DAS_stopSignHeight m2: 26|6@1+ (0.1,0) [0|0] "m" X
 SG_ DAS_stopSignStopLineDistance m2: 32|10@1+ (0.1,-20) [0|0] "m" X
 SG_ DAS_stopSignCIPVDistance m2: 42|6@1+ (0.5,0) [0|0] "m" X
 SG_ DAS_stopSignHostAccel m2: 48|10@1+ (0.01,-5) [0|0] "m/s^2" X
 SG_ DAS_stopSignCrossingWarning m2: 58|1@1+ (1,0) [0|0] "" X
 SG_ DAS_stopSignIndex m2: 59|4@1+ (1,0) [0|0] "" X
 SG_ DAS_csaOverride m7: 10|1@1+ (1,0) [0|0] "" X
 SG_ DAS_csaIntState m7: 11|3@1+ (1,0) [0|0] "" X
 SG_ DAS_csaEnableSpeed m7: 14|12@1+ (0.05,-25) [0|0] "MPH" X
 SG_ DAS_csaDisableSpeed m7: 26|12@1+ (0.05,-25) [0|0] "MPH" X
 SG_ DAS_csaFiltCurv m7: 40|16@1- (1e-06,0) [0|0] "1/m" X
 SG_ DAS_csaMeasLatAccel m7: 56|8@1+ (0.08,-10.24) [0|0] "m/s^2" X
 SG_ DAS_soCamCipvStatus m8: 8|2@1+ (1,0) [0|0] "" X
 SG_ DAS_soRad5Status m8: 10|2@1+ (1,0) [0|0] "" X
 SG_ DAS_soRad1Status m8: 12|2@1+ (1,0) [0|0] "" X
 SG_ DAS_soCamCipvDx m8: 14|6@1+ (2,0) [0|0] "m" X
 SG_ DAS_soRad1Dx m8: 20|6@1+ (2,0) [0|0] "m" X
 SG_ DAS_soRad5Dx m8: 26|6@1+ (2,0) [0|0] "m" X
 SG_ DAS_soCamCipvDy m8: 32|5@1+ (0.4,-6.4) [0|0] "m" X
 SG_ DAS_soRad5Dy m8: 37|5@1+ (0.4,-6.4) [0|0] "m" X
 SG_ DAS_soCamCipvVx m8: 42|5@1+ (1,0) [0|0] "m/s" X
 SG_ DAS_soRad5ObstProb m8: 47|4@1+ (0.0625,0) [0|0] "probability" X
 SG_ DAS_soRad5Dz m8: 51|6@1+ (0.25,-5) [0|0] "m" X
 SG_ DAS_soRad5powerdB m8: 57|7@1+ (2,0) [0|0] "dB" X
 SG_ DAS_assPrevSetSpeed m9: 8|8@1+ (0.25,0) [0|0] "m/s" X
 SG_ DAS_assNewSetSpeed m9: 16|8@1+ (0.25,0) [0|0] "m/s" X
 SG_ DAS_assFusedSpeedLimit m9: 24|6@1+ (1,0) [0|0] "m/s" X
 SG_ DAS_assAutosteerActive m9: 30|1@1+ (1,0) [0|0] "" X
 SG_ DAS_assSmartSpeedActive m9: 31|1@1+ (2,0) [0|0] "" X

BO_ 985 DAS_telemetryEvent: 8 ETH
 SG_ DAS_TE_multiplexer M: 0|5@1+ (1,0) [0|0] "" X
 SG_ DAS_TE_counter m0: 5|3@1+ (1,0) [0|0] "" X
 SG_ DAS_TE_eventID m0: 8|16@1+ (1,0) [0|0] "" X
 SG_ DAS_TE_eventType m0: 24|6@1+ (1,0) [0|0] "" X
 SG_ DAS_TE_lcAbortReason m0: 32|5@1+ (1,0) [0|0] "" X
 SG_ DAS_TE_llCounter m1: 5|3@1+ (1,0) [0|0] "" X
 SG_ DAS_TE_llC0 m1: 8|10@1- (0.02,0) [0|0] "m" X
 SG_ DAS_TE_llC1 m1: 18|9@1- (0.00195313,0) [0|0] "rad" X
 SG_ DAS_TE_llC2 m1: 27|14@1- (4e-06,0) [0|0] "1/m" X
 SG_ DAS_TE_llC3 m1: 41|14@1- (1.6e-08,0) [0|0] "1/m2" X
 SG_ DAS_TE_llQlty m1: 55|1@1+ (1,0) [0|0] "" X
 SG_ DAS_TE_llRange m1: 56|7@1+ (1,0) [0|0] "m" X
 SG_ DAS_TE_llFuse m1: 63|1@1+ (1,0) [0|0] "" X
 SG_ DAS_TE_rlCounter m2: 5|3@1+ (1,0) [0|0] "" X
 SG_ DAS_TE_rlC0 m2: 8|10@1- (0.02,0) [0|0] "m" X
 SG_ DAS_TE_rlC1 m2: 18|9@1- (0.00195313,0) [0|0] "rad" X
 SG_ DAS_TE_rlC2 m2: 27|14@1- (4e-06,0) [0|0] "1/m" X
 SG_ DAS_TE_rlC3 m2: 41|14@1- (1.6e-08,0) [0|0] "1/m2" X
 SG_ DAS_TE_rlQlty m2: 55|1@1+ (1,0) [0|0] "" X
 SG_ DAS_TE_rlRange m2: 56|7@1+ (1,0) [0|0] "m" X
 SG_ DAS_TE_rlFuse m2: 63|1@1+ (1,0) [0|0] "" X
 SG_ DAS_TE_hppCounter m3: 5|3@1+ (1,0) [0|0] "" X
 SG_ DAS_TE_hppC0 m3: 8|10@1- (0.02,0) [0|0] "m" X
 SG_ DAS_TE_hppC1 m3: 18|9@1- (0.00195313,0) [0|0] "rad" X
 SG_ DAS_TE_hppC2 m3: 27|14@1- (4e-06,0) [0|0] "1/m" X
 SG_ DAS_TE_hppC3 m3: 41|14@1- (1.6e-08,0) [0|0] "1/m2" X
 SG_ DAS_TE_hppQlty m3: 55|1@1+ (1,0) [0|0] "" X
 SG_ DAS_TE_hppRange m3: 56|7@1+ (1,0) [0|0] "m" X
 SG_ DAS_TE_hppFuse m3: 63|1@1+ (1,0) [0|0] "" X
 SG_ DAS_TE_navCounter m4: 5|3@1+ (1,0) [0|0] "" X
 SG_ DAS_TE_navC0 m4: 8|10@1- (0.02,0) [0|0] "m" X
 SG_ DAS_TE_navC1 m4: 18|9@1- (0.00195313,0) [0|0] "rad" X
 SG_ DAS_TE_navC2 m4: 27|14@1- (4e-06,0) [0|0] "1/m" X
 SG_ DAS_TE_navC3 m4: 41|14@1- (1.6e-08,0) [0|0] "1/m2" X
 SG_ DAS_TE_navQlty m4: 55|1@1+ (1,0) [0|0] "" X
 SG_ DAS_TE_navRange m4: 56|7@1+ (1,0) [0|0] "m" X
 SG_ DAS_TE_navFuse m4: 63|1@1+ (1,0) [0|0] "" X
 SG_ DAS_TE_vlCounter m5: 5|3@1+ (1,0) [0|0] "" X
 SG_ DAS_TE_vlC0 m5: 8|10@1- (0.02,0) [0|0] "m" X
 SG_ DAS_TE_vlC1 m5: 18|9@1- (0.00195313,0) [0|0] "rad" X
 SG_ DAS_TE_vlC2 m5: 27|14@1- (4e-06,0) [0|0] "1/m" X
 SG_ DAS_TE_vlC3 m5: 41|14@1- (1.6e-08,0) [0|0] "1/m2" X
 SG_ DAS_TE_vlQlty m5: 55|1@1+ (1,0) [0|0] "" X
 SG_ DAS_TE_vlRange m5: 56|7@1+ (1,0) [0|0] "m" X
 SG_ DAS_TE_vlFuse m5: 63|1@1+ (1,0) [0|0] "" X
 SG_ DAS_TE_accCounter m6: 5|3@1+ (1,0) [0|0] "" X
 SG_ DAS_TE_accTargetDx m6: 8|6@1+ (2,0) [0|0] "m" X
 SG_ DAS_TE_accTargetDy m6: 14|6@1+ (0.2,-6.4) [0|0] "m" X
 SG_ DAS_TE_accTargetRelVel m6: 20|7@1- (0.25,0) [0|0] "m/s" X
 SG_ DAS_TE_accTargetRelA m6: 27|5@1- (0.5,0) [0|0] "m/s^2" X
 SG_ DAS_TE_accMinAccel m6: 32|5@1- (0.5,0) [0|0] "m/s^2" X
 SG_ DAS_TE_accMinJ m6: 37|5@1- (0.5,0) [0|0] "m/s^3" X
 SG_ DAS_TE_fcmCounter m7: 5|3@1+ (1,0) [0|0] "" X
 SG_ DAS_TE_fcmTargetDx m7: 8|8@1+ (0.25,0) [0|0] "m" X
 SG_ DAS_TE_fcmTargetDy m7: 16|5@1+ (0.2,0) [0|0] "m" X
 SG_ DAS_TE_fcmTargetVRel m7: 21|7@1+ (0.25,-31.75) [0|0] "m/s" X
 SG_ DAS_TE_fcmTargetAccel m7: 28|5@1+ (0.5,-15.5) [0|0] "m/s^2" X
 SG_ DAS_TE_fcmTargetProb m7: 33|5@1+ (5,0) [0|0] "%" X
 SG_ DAS_TE_fcmDecelReqInstant m7: 38|7@1- (0.1,0) [0|0] "m/s^2" X
 SG_ DAS_TE_fcmDecelReqAeb m7: 45|7@1- (0.1,0) [0|0] "m/s^2" X
 SG_ DAS_TE_meAebFlag m7: 52|1@1+ (1,0) [0|0] "" X
 SG_ DAS_TE_ipsoCounter m8: 5|3@1+ (1,0) [0|0] "" X
 SG_ DAS_TE_ipsoValid m8: 8|1@1+ (1,0) [0|0] "" X
 SG_ DAS_TE_ipsoConfidence m8: 9|7@1+ (1,0) [0|0] "" X
 SG_ DAS_TE_ipsoDx m8: 16|6@1+ (2,0) [0|0] "m" X
 SG_ DAS_TE_ipsoDy m8: 22|6@1+ (0.1,-3.2) [0|0] "m" X
 SG_ DAS_TE_vlDyAtIpsoDx m8: 28|6@1+ (0.1,-3.2) [0|0] "m" X
 SG_ DAS_TE_swaProjection m8: 34|6@1+ (0.1,-3.2) [0|0] "m" X
 SG_ DAS_TE_ipsoIsTarget1 m8: 40|1@1+ (1,0) [0|0] "" X
 SG_ DAS_TE_ipsoIsTarget5 m8: 41|1@1+ (1,0) [0|0] "" X
 SG_ DAS_TE_restrictedAccess m8: 42|1@1+ (1,0) [0|0] "" X
 SG_ DAS_TE_csaOfframpValid m8: 43|1@1+ (1,0) [0|0] "" X
 SG_ DAS_TE_accControlType m8: 44|4@1+ (1,0) [0|0] "" X
 SG_ DAS_TE_brakeCapacityWarning m8: 48|1@1+ (1,0) [0|0] "" X
 SG_ DAS_TE_emergencyBrake m8: 49|1@1+ (1,0) [0|0] "" X
 SG_ DAS_TE_extendedAccLimits m8: 50|1@1+ (1,0) [0|0] "" X
 SG_ DAS_TE_crashFront m8: 51|1@1+ (1,0) [0|0] "" X
 SG_ DAS_TE_crashLeft m8: 52|1@1+ (1,0) [0|0] "" X
 SG_ DAS_TE_crashRear m8: 53|1@1+ (1,0) [0|0] "" X
 SG_ DAS_TE_crashRight m8: 54|1@1+ (1,0) [0|0] "" X
 SG_ DAS_TE_crashRollover m8: 55|1@1+ (1,0) [0|0] "" X
 SG_ DAS_TE_crashPedPro m8: 56|1@1+ (1,0) [0|0] "" X
 SG_ DAS_TE_meIpsoValid m8: 57|1@1+ (1,0) [0|0] "" X
 SG_ DAS_TE_robCounter m9: 5|3@1+ (1,0) [0|0] "" X
 SG_ DAS_TE_robExceptionStart m9: 16|8@1+ (1,-95) [0|0] "m" X
 SG_ DAS_TE_robExceptionEnd m9: 24|8@1+ (1,0) [0|0] "m" X
 SG_ DAS_TE_robDistanceEllipse m9: 32|8@1+ (0.5,0) [0|0] "m" X
 SG_ DAS_TE_robEllipseOverlap m9: 40|8@1+ (0.1,-12.5) [0|0] "m" X
 SG_ DAS_TE_robEllipseAge m9: 48|3@1+ (1,0) [0|0] "" X
 SG_ DAS_TE_robInfrastructure m9: 51|1@1+ (1,0) [0|0] "" X
 SG_ DAS_TE_robTrustRadarMap m9: 52|1@1+ (1,0) [0|0] "" X
 SG_ DAS_TE_robActiveBraking m9: 53|1@1+ (1,0) [0|0] "" X

BO_ 945 DAS_telemetryFurniture: 8 ETH
 SG_ DAS_TF_multiplexer M: 0|5@1+ (1,0) [0|0] "" X
 SG_ DAS_TF_furnitureIndex0 m0: 5|8@1+ (1,0) [0|0] "" X
 SG_ DAS_TF_distTraveled m0: 13|11@1+ (0.1,0) [0|0] "m" X
 SG_ DAS_TF_llType m0: 24|3@1+ (1,0) [0|0] "" X
 SG_ DAS_TF_rlType m0: 27|3@1+ (1,0) [0|0] "" X
 SG_ DAS_TF_cipvDist m0: 30|9@1+ (0.1,0) [0|0] "m" X
 SG_ DAS_TF_timeOfDay m0: 39|3@1+ (1,0) [0|0] "" X
 SG_ DAS_TF_furnitureType m0: 42|3@1+ (1,0) [0|0] "" X
 SG_ DAS_TF_furnitureIndex1 m1: 5|8@1+ (1,0) [0|0] "" X
 SG_ DAS_TF_longitudinalDist m1: 13|12@1+ (0.1,0) [0|0] "m" X
 SG_ DAS_TF_lateralDist m1: 25|12@1+ (0.1,-204.8) [0|0] "m" X
 SG_ DAS_TF_height m1: 37|12@1+ (0.05,0) [0|0] "m" X
 SG_ DAS_TF_color m1: 49|3@1+ (1,0) [0|0] "" X
 SG_ DAS_TF_shape m1: 52|3@1+ (1,0) [0|0] "" X
 SG_ DAS_TF_orientation m1: 55|2@1+ (1,0) [0|0] "" X
 SG_ DAS_TF_transmissionStatus m1: 57|2@1+ (1,0) [0|0] "" X
 SG_ DAS_TF_isMain m1: 59|1@1+ (1,0) [0|0] "" X
 SG_ DAS_TF_isTeslaMain m1: 60|1@1+ (1,0) [0|0] "" X
 SG_ DAS_TF_furnitureIndex2 m2: 5|8@1+ (1,0) [0|0] "" X
 SG_ DAS_TF_juncStatus m2: 13|4@1+ (1,0) [0|0] "" X
 SG_ DAS_TF_juncDist m2: 17|11@1+ (0.2,-20) [0|0] "m" X
 SG_ DAS_TF_stopLineDist m2: 28|11@1+ (0.1,-10) [0|0] "m" X
 SG_ DAS_TF_ttc m2: 39|7@1+ (0.1,0) [0|0] "s" X

BO_ 889 DAS_telemetryPeriodic: 8 ETH
 SG_ DAS_TP_multiplexer M: 0|5@1+ (1,0) [0|0] "" X
 SG_ DAS_TP_counter m0: 5|3@1+ (1,0) [0|0] "" X
 SG_ DAS_TP_vlWidth m0: 8|8@1+ (0.05,0) [0|0] "m" X
 SG_ DAS_TP_hppError m0: 16|6@1+ (0.05,0) [0|0] "m" X
 SG_ DAS_TP_wipersActive m0: 22|1@1+ (1,0) [0|0] "" X
 SG_ DAS_TP_handsOn m0: 23|1@1+ (1,0) [0|0] "" X
 SG_ DAS_TP_sonicDistL m0: 24|9@1+ (0.01,0) [0|0] "m" X
 SG_ DAS_TP_sonicDistR m0: 33|9@1+ (0.01,0) [0|0] "m" X
 SG_ DAS_TP_hppValid m0: 42|1@1+ (1,0) [0|0] "" X
 SG_ DAS_TP_restrictedAccess m0: 43|1@1+ (1,0) [0|0] "" X
 SG_ DAS_TP_vehFuse m0: 44|1@1+ (1,0) [0|0] "" X
 SG_ DAS_TP_accRestricted m0: 46|1@1+ (1,0) [0|0] "" X
 SG_ DAS_TP_laneChange m0: 48|2@1+ (1,0) [0|0] "" X
 SG_ DAS_TP_llType m0: 50|3@1+ (1,0) [0|0] "" X
 SG_ DAS_TP_rlType m0: 53|3@1+ (1,0) [0|0] "" X
 SG_ DAS_TP_plannerState m0: 56|4@1+ (1,0) [0|0] "" X
 SG_ DAS_TP_lcState m0: 60|4@1+ (1,0) [0|0] "" X
 SG_ DAS_TP_llCounter m1: 5|3@1+ (1,0) [0|0] "" X
 SG_ DAS_TP_llC0 m1: 8|10@1- (0.02,0) [0|0] "m" X
 SG_ DAS_TP_llC1 m1: 18|9@1- (0.00195313,0) [0|0] "rad" X
 SG_ DAS_TP_llC2 m1: 27|14@1- (4e-06,0) [0|0] "1/m" X
 SG_ DAS_TP_llC3 m1: 41|14@1- (1.6e-08,0) [0|0] "1/m2" X
 SG_ DAS_TP_llQlty m1: 55|1@1+ (1,0) [0|0] "" X
 SG_ DAS_TP_llRange m1: 56|7@1+ (1,0) [0|0] "m" X
 SG_ DAS_TP_llFuse m1: 63|1@1+ (1,0) [0|0] "" X
 SG_ DAS_TP_rlCounter m2: 5|3@1+ (1,0) [0|0] "" X
 SG_ DAS_TP_rlC0 m2: 8|10@1- (0.02,0) [0|0] "m" X
 SG_ DAS_TP_rlC1 m2: 18|9@1- (0.00195313,0) [0|0] "rad" X
 SG_ DAS_TP_rlC2 m2: 27|14@1- (4e-06,0) [0|0] "1/m" X
 SG_ DAS_TP_rlC3 m2: 41|14@1- (1.6e-08,0) [0|0] "1/m2" X
 SG_ DAS_TP_rlQlty m2: 55|1@1+ (1,0) [0|0] "" X
 SG_ DAS_TP_rlRange m2: 56|7@1+ (1,0) [0|0] "m" X
 SG_ DAS_TP_rlFuse m2: 63|1@1+ (1,0) [0|0] "" X
 SG_ DAS_TP_hppCounter m3: 5|3@1+ (1,0) [0|0] "" X
 SG_ DAS_TP_hppC0 m3: 8|10@1- (0.02,0) [0|0] "m" X
 SG_ DAS_TP_hppC1 m3: 18|9@1- (0.00195313,0) [0|0] "rad" X
 SG_ DAS_TP_hppC2 m3: 27|14@1- (4e-06,0) [0|0] "1/m" X
 SG_ DAS_TP_hppC3 m3: 41|14@1- (1.6e-08,0) [0|0] "1/m2" X
 SG_ DAS_TP_hppQlty m3: 55|1@1+ (1,0) [0|0] "" X
 SG_ DAS_TP_hppRange m3: 56|7@1+ (1,0) [0|0] "m" X
 SG_ DAS_TP_hppFuse m3: 63|1@1+ (1,0) [0|0] "" X
 SG_ DAS_TP_navCounter m4: 5|3@1+ (1,0) [0|0] "" X
 SG_ DAS_TP_navC0 m4: 8|10@1- (0.02,0) [0|0] "m" X
 SG_ DAS_TP_navC1 m4: 18|9@1- (0.00195313,0) [0|0] "rad" X
 SG_ DAS_TP_navC2 m4: 27|14@1- (4e-06,0) [0|0] "1/m" X
 SG_ DAS_TP_navC3 m4: 41|14@1- (1.6e-08,0) [0|0] "1/m2" X
 SG_ DAS_TP_navQlty m4: 55|1@1+ (1,0) [0|0] "" X
 SG_ DAS_TP_navRange m4: 56|7@1+ (1,0) [0|0] "m" X
 SG_ DAS_TP_navFuse m4: 63|1@1+ (1,0) [0|0] "" X
 SG_ DAS_TP_vlCounter m5: 5|3@1+ (1,0) [0|0] "" X
 SG_ DAS_TP_vlC0 m5: 8|10@1- (0.02,0) [0|0] "m" X
 SG_ DAS_TP_vlC1 m5: 18|9@1- (0.00195313,0) [0|0] "rad" X
 SG_ DAS_TP_vlC2 m5: 27|14@1- (4e-06,0) [0|0] "1/m" X
 SG_ DAS_TP_vlC3 m5: 41|14@1- (1.6e-08,0) [0|0] "1/m2" X
 SG_ DAS_TP_vlQlty m5: 55|1@1+ (1,0) [0|0] "" X
 SG_ DAS_TP_vlRange m5: 56|7@1+ (1,0) [0|0] "m" X
 SG_ DAS_TP_vlFuse m5: 63|1@1+ (1,0) [0|0] "" X
 SG_ DAS_TP_bdlCounter m6: 5|3@1+ (1,0) [0|0] "" X
 SG_ DAS_TP_bdlC0 m6: 8|10@1- (0.02,0) [0|0] "m" X
 SG_ DAS_TP_bdlC1 m6: 18|9@1- (0.00195313,0) [0|0] "rad" X
 SG_ DAS_TP_bdlC2 m6: 27|14@1- (4e-06,0) [0|0] "1/m" X
 SG_ DAS_TP_bdlC3 m6: 41|14@1- (1.6e-08,0) [0|0] "1/m2" X
 SG_ DAS_TP_bdlQlty m6: 55|1@1+ (1,0) [0|0] "" X
 SG_ DAS_TP_bdlRange m6: 56|7@1+ (1,0) [0|0] "m" X
 SG_ DAS_TP_bdlFuse m6: 63|1@1+ (1,0) [0|0] "" X
 SG_ DAS_TP_bdrCounter m7: 5|3@1+ (1,0) [0|0] "" X
 SG_ DAS_TP_bdrC0 m7: 8|10@1- (0.02,0) [0|0] "m" X
 SG_ DAS_TP_bdrC1 m7: 18|9@1- (0.00195313,0) [0|0] "rad" X
 SG_ DAS_TP_bdrC2 m7: 27|14@1- (4e-06,0) [0|0] "1/m" X
 SG_ DAS_TP_bdrC3 m7: 41|14@1- (1.6e-08,0) [0|0] "1/m2" X
 SG_ DAS_TP_bdrQlty m7: 55|1@1+ (1,0) [0|0] "" X
 SG_ DAS_TP_bdrRange m7: 56|7@1+ (1,0) [0|0] "m" X
 SG_ DAS_TP_bdrFuse m7: 63|1@1+ (1,0) [0|0] "" X
 SG_ DAS_TP_laneCounter m8: 5|3@1+ (1,0) [0|0] "" X
 SG_ DAS_TP_llSegQ1 m8: 8|4@1+ (10,0) [0|0] "%" X
 SG_ DAS_TP_llSegQ2 m8: 12|4@1+ (10,0) [0|0] "%" X
 SG_ DAS_TP_llSegQ3 m8: 16|4@1+ (10,0) [0|0] "%" X
 SG_ DAS_TP_llSegQ4 m8: 20|4@1+ (10,0) [0|0] "%" X
 SG_ DAS_TP_rlSegQ1 m8: 24|4@1+ (10,0) [0|0] "%" X
 SG_ DAS_TP_rlSegQ2 m8: 28|4@1+ (10,0) [0|0] "%" X
 SG_ DAS_TP_rlSegQ3 m8: 32|4@1+ (10,0) [0|0] "%" X
 SG_ DAS_TP_rlSegQ4 m8: 36|4@1+ (10,0) [0|0] "%" X
 SG_ DAS_TP_llExist m8: 40|4@1+ (10,0) [0|0] "%" X
 SG_ DAS_TP_rlExist m8: 44|4@1+ (10,0) [0|0] "%" X
 SG_ DAS_TP_nllProb m8: 48|4@1+ (0.1,0) [0|0] "1" X
 SG_ DAS_TP_nrlProb m8: 52|4@1+ (0.1,0) [0|0] "1" X
 SG_ DAS_TP_llQltyME m8: 56|2@1+ (1,0) [0|0] "" X
 SG_ DAS_TP_rlQltyME m8: 58|2@1+ (1,0) [0|0] "" X
 SG_ DAS_TP_bdlQltyME m8: 60|2@1+ (1,0) [0|0] "" X
 SG_ DAS_TP_bdrQltyME m8: 62|2@1+ (1,0) [0|0] "" X
 SG_ DAS_TP_llrCounter m9: 5|3@1+ (1,0) [0|0] "" X
 SG_ DAS_TP_numLanes m9: 8|3@1+ (1,0) [0|0] "" X
 SG_ DAS_TP_lane1LLR m9: 11|6@1+ (0.3125,-10) [0|0] "1" X
 SG_ DAS_TP_lane2LLR m9: 17|6@1+ (0.3125,-10) [0|0] "1" X
 SG_ DAS_TP_lane3LLR m9: 23|6@1+ (0.3125,-10) [0|0] "1" X
 SG_ DAS_TP_lane4LLR m9: 29|6@1+ (0.3125,-10) [0|0] "1" X
 SG_ DAS_TP_lane5LLR m9: 35|6@1+ (0.3125,-10) [0|0] "1" X
 SG_ DAS_TP_lane6LLR m9: 41|6@1+ (0.3125,-10) [0|0] "1" X
 SG_ DAS_TP_lane7LLR m9: 47|6@1+ (0.3125,-10) [0|0] "1" X
 SG_ DAS_TP_lane8LLR m9: 53|6@1+ (0.3125,-10) [0|0] "1" X
 SG_ DAS_TP_egoLane m9: 59|3@1+ (1,0) [0|0] "" X

BA_DEF_ BO_ "GenMsgSendType" ENUM "Cyclic";
BA_DEF_ BO_ "GenMsgCycleTime" INT 0 60000;

BA_ "GenMsgSendType" BO_ 795 0;
BA_ "GenMsgCycleTime" BO_ 795 1000;

BA_ "GenMsgSendType" BO_ 701 0;
BA_ "GenMsgCycleTime" BO_ 701 100;

BA_ "GenMsgSendType" BO_ 589 0;
BA_ "GenMsgCycleTime" BO_ 589 100;

BA_ "GenMsgSendType" BO_ 669 0;
BA_ "GenMsgCycleTime" BO_ 669 100;

BA_ "GenMsgSendType" BO_ 605 0;
BA_ "GenMsgCycleTime" BO_ 605 100;

BA_ "GenMsgSendType" BO_ 868 0;
BA_ "GenMsgCycleTime" BO_ 868 1000;

BA_ "GenMsgSendType" BO_ 575 0;
BA_ "GenMsgCycleTime" BO_ 575 100;

BA_ "GenMsgSendType" BO_ 686 0;
BA_ "GenMsgCycleTime" BO_ 686 100;

BA_ "GenMsgSendType" BO_ 781 0;
BA_ "GenMsgCycleTime" BO_ 781 1000;

BA_ "GenMsgSendType" BO_ 797 0;
BA_ "GenMsgCycleTime" BO_ 797 1000;

BA_ "GenMsgSendType" BO_ 1300 0;
BA_ "GenMsgCycleTime" BO_ 1300 1000;

BA_ "GenMsgSendType" BO_ 1448 0;
BA_ "GenMsgCycleTime" BO_ 1448 1000;

BA_ "GenMsgSendType" BO_ 32 0;
BA_ "GenMsgCycleTime" BO_ 32 1000;

BA_ "GenMsgSendType" BO_ 33 0;
BA_ "GenMsgCycleTime" BO_ 33 1000;

BA_ "GenMsgSendType" BO_ 34 0;
BA_ "GenMsgCycleTime" BO_ 34 1000;

BA_ "GenMsgSendType" BO_ 35 0;
BA_ "GenMsgCycleTime" BO_ 35 1000;

BA_ "GenMsgSendType" BO_ 96 0;
BA_ "GenMsgCycleTime" BO_ 96 1000;

BA_ "GenMsgSendType" BO_ 97 0;
BA_ "GenMsgCycleTime" BO_ 97 1000;

BA_ "GenMsgSendType" BO_ 994 0;
BA_ "GenMsgCycleTime" BO_ 994 1000;

BA_ "GenMsgSendType" BO_ 64 0;
BA_ "GenMsgCycleTime" BO_ 64 1000;

BA_ "GenMsgSendType" BO_ 1042 0;
BA_ "GenMsgCycleTime" BO_ 1042 1000;

BA_ "GenMsgSendType" BO_ 802 0;
BA_ "GenMsgCycleTime" BO_ 802 1000;

BA_ "GenMsgSendType" BO_ 1490 0;
BA_ "GenMsgCycleTime" BO_ 1490 1000;

BA_ "GenMsgSendType" BO_ 978 0;
BA_ "GenMsgCycleTime" BO_ 978 1000;

BA_ "GenMsgSendType" BO_ 1378 0;
BA_ "GenMsgCycleTime" BO_ 1378 10000;

BA_ "GenMsgSendType" BO_ 65 0;
BA_ "GenMsgCycleTime" BO_ 65 1000;

BA_ "GenMsgSendType" BO_ 537 0;
BA_ "GenMsgCycleTime" BO_ 537 30000;

BA_ "GenMsgSendType" BO_ 786 0;
BA_ "GenMsgCycleTime" BO_ 786 1000;

BA_ "GenMsgSendType" BO_ 926 0;
BA_ "GenMsgCycleTime" BO_ 926 100;

BA_ "GenMsgSendType" BO_ 647 0;
BA_ "GenMsgCycleTime" BO_ 647 1000;

BA_ "GenMsgSendType" BO_ 1134 0;
BA_ "GenMsgCycleTime" BO_ 1134 10000;

BA_ "GenMsgSendType" BO_ 592 0;
BA_ "GenMsgCycleTime" BO_ 592 1000;

BA_ "GenMsgSendType" BO_ 593 0;
BA_ "GenMsgCycleTime" BO_ 593 1000;

BA_ "GenMsgSendType" BO_ 1335 0;
BA_ "GenMsgCycleTime" BO_ 1335 1000;

BA_ "GenMsgSendType" BO_ 1337 0;
BA_ "GenMsgCycleTime" BO_ 1337 1000;

BA_ "GenMsgSendType" BO_ 1339 0;
BA_ "GenMsgCycleTime" BO_ 1339 1000;

BA_ "GenMsgSendType" BO_ 1463 0;
BA_ "GenMsgCycleTime" BO_ 1463 1000;

BA_ "GenMsgSendType" BO_ 1465 0;
BA_ "GenMsgCycleTime" BO_ 1465 1000;

BA_ "GenMsgSendType" BO_ 1467 0;
BA_ "GenMsgCycleTime" BO_ 1467 1000;

BA_ "GenMsgSendType" BO_ 956 0;
BA_ "GenMsgCycleTime" BO_ 956 1000;

BA_ "GenMsgSendType" BO_ 66 0;
BA_ "GenMsgCycleTime" BO_ 66 1000;

BA_ "GenMsgSendType" BO_ 67 0;
BA_ "GenMsgCycleTime" BO_ 67 1000;

BA_ "GenMsgSendType" BO_ 1468 0;
BA_ "GenMsgCycleTime" BO_ 1468 1000;

BA_ "GenMsgSendType" BO_ 940 0;
BA_ "GenMsgCycleTime" BO_ 940 1000;

BA_ "GenMsgSendType" BO_ 68 0;
BA_ "GenMsgCycleTime" BO_ 68 1000;

BA_ "GenMsgSendType" BO_ 69 0;
BA_ "GenMsgCycleTime" BO_ 69 1000;

BA_ "GenMsgSendType" BO_ 828 0;
BA_ "GenMsgCycleTime" BO_ 828 1000;

BA_ "GenMsgSendType" BO_ 36 0;
BA_ "GenMsgCycleTime" BO_ 36 1000;

BA_ "GenMsgSendType" BO_ 37 0;
BA_ "GenMsgCycleTime" BO_ 37 1000;

BA_ "GenMsgSendType" BO_ 1340 0;
BA_ "GenMsgCycleTime" BO_ 1340 1000;

BA_ "GenMsgSendType" BO_ 540 0;
BA_ "GenMsgCycleTime" BO_ 540 100;

BA_ "GenMsgSendType" BO_ 812 0;
BA_ "GenMsgCycleTime" BO_ 812 1000;

BA_ "GenMsgSendType" BO_ 38 0;
BA_ "GenMsgCycleTime" BO_ 38 1000;

BA_ "GenMsgSendType" BO_ 39 0;
BA_ "GenMsgCycleTime" BO_ 39 1000;

BA_ "GenMsgSendType" BO_ 867 0;
BA_ "GenMsgCycleTime" BO_ 867 1000;

BA_ "GenMsgSendType" BO_ 1342 0;
BA_ "GenMsgCycleTime" BO_ 1342 1000;

BA_ "GenMsgSendType" BO_ 20 0;
BA_ "GenMsgCycleTime" BO_ 20 1000;

BA_ "GenMsgSendType" BO_ 40 0;
BA_ "GenMsgCycleTime" BO_ 40 1000;

BA_ "GenMsgSendType" BO_ 129 0;
BA_ "GenMsgCycleTime" BO_ 129 500;

BA_ "GenMsgSendType" BO_ 583 0;
BA_ "GenMsgCycleTime" BO_ 583 100;

BA_ "GenMsgSendType" BO_ 825 0;
BA_ "GenMsgCycleTime" BO_ 825 500;

BA_ "GenMsgSendType" BO_ 697 0;
BA_ "GenMsgCycleTime" BO_ 697 40;

BA_ "GenMsgSendType" BO_ 1641 0;
BA_ "GenMsgCycleTime" BO_ 1641 1000;

BA_ "GenMsgSendType" BO_ 1338 0;
BA_ "GenMsgCycleTime" BO_ 1338 1000;

BA_ "GenMsgSendType" BO_ 571 0;
BA_ "GenMsgCycleTime" BO_ 571 100;

BA_ "GenMsgSendType" BO_ 500 0;
BA_ "GenMsgCycleTime" BO_ 500 40;

BA_ "GenMsgSendType" BO_ 1027 0;
BA_ "GenMsgCycleTime" BO_ 1027 30;

BA_ "GenMsgSendType" BO_ 921 0;
BA_ "GenMsgCycleTime" BO_ 921 500;

BA_ "GenMsgSendType" BO_ 905 0;
BA_ "GenMsgCycleTime" BO_ 905 500;

VAL_ 701 BCS2R_6040ReclinerState 0 "FORWARD" 1 "BACK" 2 "UNKNOWN" 3 "NOT_INSTALLED" 4 "CRASH";
VAL_ 701 BCS2R_6040ReclinerStopReason 0 "NONE" 1 "TIMEOUT" 2 "CURRENT_THRESHOLD" 3 "NO_CURRENT" 4 "CURRENT_PEAK";
VAL_ 701 BCS2R_6040TrackState 0 "LOCKED" 1 "RELEASING" 2 "RELEASED" 3 "LOCKING" 4 "UNKNOWN" 5 "NOT_INSTALLED" 6 "RELEASED_HOLD" 7 "LOCKING_UNDERCURRENT";
VAL_ 701 BCS2R_6040TrackStopReason 0 "NONE" 1 "TIMEOUT" 2 "CURRENT_THRESHOLD" 3 "NO_CURRENT" 4 "CURRENT_PEAK";

VAL_ 1309 BCS2R_infoIndex 0 "DEPRECATED_0" 1 "DEPRECATED_1" 2 "DEPRECATED_2" 3 "DEPRECATED_3" 4 "DEPRECATED_4" 5 "DEPRECATED_5" 6 "DEPRECATED_6" 7 "DEPRECATED_7" 8 "DEPRECATED_8" 9 "DEPRECATED_9" 10 "BUILD_HWID_COMPONENTID" 11 "PCBAID_ASSYID_USAGEID" 13 "APP_CRC" 14 "BOOTLOADER_SVN" 15 "BOOTLOADER_CRC" 16 "SUBCOMPONENT1" 17 "APP_GITHASH" 18 "BOOTLOADER_GITHASH" 19 "VERSION_DEPRECATED" 20 "UDS_PROTOCOL_BOOTCRC" 23 "SUBCOMPONENT2" 24 "SUBCOMPONENT3" 31 "SUBCOMPONENT4" 255 "END";
VAL_ 1309 BCS2R_infoBuildType 0 "UNKNOWN_BUILD" 1 "PLATFORM_BUILD" 2 "LOCAL_BUILD" 3 "TRACEABLE_CI_BUILD" 4 "MFG_BUILD";
VAL_ 1309 BCS2R_infoAssemblyID 1 "ASSEMBLY1" 255 "ASSEMBLY_SNA";

VAL_ 669 BCS2R_isPitchMoving 0 "IS_MOVING_SNA" 1 "NOT_MOVING" 2 "MOVING" 3 "MOVING_UNKNOWN";
VAL_ 669 BCS2R_pitchPosition -762 "EASY_ENTRY_FORWARD" -138 "COMFORT_FORWARD" 0 "EASY_ENTRY_REVERSE" 118 "COMFORT_REVERSE";
VAL_ 669 BCS2R_pitchState 0 "OFF" 1 "FORWARD" 2 "REVERSE" 3 "STOPPING" 4 "EASY_ENTRY_FORWARD" 5 "EASY_ENTRY_REVERSE" 6 "CALIBRATING" 7 "COLLISION_RESOLUTION_FWD" 8 "COLLISION_RESOLUTION_REV" 9 "CRASH" 10 "CRASH_FWD" 11 "CRASH_REV" 12 "UNKNOWN" 13 "NOT_INSTALLED";

VAL_ 605 BCS2R_2RChimeTelltaleRequest 0 "OFF" 1 "ON" 2 "UNUSED" 3 "SNA";
VAL_ 605 BCS2R_2RowBuckleStatus 0 "UNLATCHED" 1 "LATCHED" 2 "FAULTED" 3 "SNA";
VAL_ 605 BCS2R_2RowOccupancyStatus 0 "UNOCCUPIED" 1 "OCCUPIED" 2 "FAULTED" 3 "SNA";
VAL_ 605 BCS2R_3RChimeTelltaleRequest 0 "OFF" 1 "ON" 2 "UNUSED" 3 "SNA";
VAL_ 605 BCS2R_3RowBuckleStatus 0 "UNLATCHED" 1 "LATCHED" 2 "FAULTED" 3 "SNA";
VAL_ 605 BCS2R_3RowOccupancyStatus 0 "UNOCCUPIED" 1 "OCCUPIED" 2 "FAULTED" 3 "SNA";

VAL_ 868 BCS2R_crashStatus 0 "INACTIVE" 1 "ACTIVE" 3 "SNA";

VAL_ 575 BCS2R_3RowFoldFlatSwitch 0 "SNA" 1 "FAULT" 2 "HEADREST_ONLY" 3 "HEADREST_AND_FOLD" 4 "IDLE";
VAL_ 575 BCS2R_comfortPitchSwitchStatus 0 "IDLE" 1 "FORWARD" 2 "BACKWARD" 3 "FAULT" 4 "SNA";
VAL_ 575 BCS2R_comfortTrackSwitchStatus 0 "IDLE" 1 "FORWARD" 2 "BACKWARD" 3 "FAULT" 4 "SNA";
VAL_ 575 BCS2R_easyEntryHallSensorStatus 0 "SNA" 1 "FAULT" 2 "ACTIVE" 3 "INACTIVE";
VAL_ 575 BCS2R_easyEntryLatchSensorStatus 0 "SNA" 1 "FAULT" 2 "LATCHED" 3 "NOT_LATCHED";
VAL_ 575 BCS2R_easyEntryReadyForward 0 "NOT_READY" 1 "READY" 2 "NEEDS_OVERRIDE" 3 "IN_PROGRESS";
VAL_ 575 BCS2R_easyEntryReadyReverse 0 "NOT_READY" 1 "READY" 2 "NEEDS_OVERRIDE" 3 "IN_PROGRESS";
VAL_ 575 BCS2R_easyEntrySwitchStatus 0 "IDLE" 1 "FORWARD" 2 "BACKWARD" 3 "FAULT" 4 "SNA";
VAL_ 575 BCS2R_easyEntrySwitchStatusLeft 0 "IDLE" 1 "FORWARD" 2 "BACKWARD" 3 "FAULT" 4 "SNA";
VAL_ 575 BCS2R_easyEntrySwitchStatusRight 0 "IDLE" 1 "FORWARD" 2 "BACKWARD" 3 "FAULT" 4 "SNA";
VAL_ 575 BCS2R_easyEntryUnlatchStatus 0 "SNA" 1 "FAULT" 2 "UNLATCHED" 3 "NOT_UNLATCHED";
VAL_ 575 BCS2R_trackHomeSensorStatus 0 "SNA" 1 "FAULT" 2 "ACTIVE" 3 "INACTIVE";

VAL_ 686 BCS2R_isTrackMoving 0 "IS_MOVING_SNA" 1 "NOT_MOVING" 2 "MOVING" 3 "MOVING_UNKNOWN";
VAL_ 686 BCS2R_trackMotorPosition -5097 "EASY_ENTRY_COMFORT_REVERSE" -600 "COMFORT_FORWARD" 13645 "EASY_ENTRY_FORWARD";
VAL_ 686 BCS2R_trackState 0 "OFF" 1 "FORWARD" 2 "REVERSE" 3 "STOPPING" 4 "STARTING_EASY_ENTRY" 5 "EASY_ENTRY_FORWARD" 6 "EASY_ENTRY_REVERSE" 7 "CALIBRATING_FORWARD" 8 "CALIBRATING_REVERSE" 9 "COLLISION_RESOLUTION_FWD" 10 "COLLISION_RESOLUTION_REV" 11 "CRASH" 12 "CRASH_FWD" 13 "CRASH_REV" 14 "UNKNOWN" 15 "NOT_INSTALLED";

VAL_ 1300 BC_componentBranchOrigin 254 "LOCAL_BUILD" 255 "SNA";
VAL_ 1300 BC_componentHardwareRevision 254 "LOCAL_BUILD" 255 "SNA";
VAL_ 1300 BC_componentMajorVersion 254 "LOCAL_BUILD" 255 "SNA";
VAL_ 1300 BC_componentMaturity 254 "LOCAL_BUILD" 255 "SNA";
VAL_ 1300 BC_componentSvn 16777215 "SNA";
VAL_ 1300 BC_platformType 254 "LOCAL_BUILD" 255 "SNA";

VAL_ 6 BMS_brickVoltageMax 4095 "SNA";
VAL_ 6 BMS_brickVoltageMin 4095 "SNA";
VAL_ 6 BMS_moduleTMax 255 "SNA";
VAL_ 6 BMS_moduleTMin 255 "SNA";

VAL_ 64 BMS_chgLineCurrentAvail 2047 "SNA";
VAL_ 64 BMS_chgPower 2047 "SNA";
VAL_ 64 BMS_chgPowerAvailable 2047 "SNA";
VAL_ 64 BMS_chgTimeToFull 4095 "SNA";
VAL_ 64 BMS_gbUpdateDetectorState 0 "NOT_ACTIVE" 1 "RECENTLY_CONNECTED" 2 "UPDATE_IN_PROGRESS" 3 "UPDATE_WINDOW_CLOSED";

VAL_ 1042 BMS_vDeltaNegCtrDrop -128 "SNA";
VAL_ 1042 BMS_vDeltaPackCurrent 255 "SNA";
VAL_ 1042 BMS_vDeltaPackMinus 255 "SNA";
VAL_ 1042 BMS_vDeltaPackPlus 255 "SNA";
VAL_ 1042 BMS_vDeltaPosCtrDrop -128 "SNA";

VAL_ 802 BMS_dtcIndex 0 "mux0";
VAL_ 802 BMS_d001_Internal_Batt_Failure 0 "NOT_TESTED_DTC" 1 "PASSED_DTC" 2 "FAILED_DTC" 3 "UNABLE_TO_TEST_DTC";
VAL_ 802 BMS_d002_Internal_Iso_Failure 0 "NOT_TESTED_DTC" 1 "PASSED_DTC" 2 "FAILED_DTC" 3 "UNABLE_TO_TEST_DTC";
VAL_ 802 BMS_d003_FEIM_Failure 0 "NOT_TESTED_DTC" 1 "PASSED_DTC" 2 "FAILED_DTC" 3 "UNABLE_TO_TEST_DTC";
VAL_ 802 BMS_d004_System_Iso_Failure 0 "NOT_TESTED_DTC" 1 "PASSED_DTC" 2 "FAILED_DTC" 3 "UNABLE_TO_TEST_DTC";
VAL_ 802 BMS_d005_Pos_Ctr_Stuck_Closed 0 "NOT_TESTED_DTC" 1 "PASSED_DTC" 2 "FAILED_DTC" 3 "UNABLE_TO_TEST_DTC";
VAL_ 802 BMS_d006_Neg_Ctr_Stuck_Closed 0 "NOT_TESTED_DTC" 1 "PASSED_DTC" 2 "FAILED_DTC" 3 "UNABLE_TO_TEST_DTC";
VAL_ 802 BMS_d007_HVIL_Fault 0 "NOT_TESTED_DTC" 1 "PASSED_DTC" 2 "FAILED_DTC" 3 "UNABLE_TO_TEST_DTC";
VAL_ 802 BMS_d008_HV_Discharge_Fault 0 "NOT_TESTED_DTC" 1 "PASSED_DTC" 2 "FAILED_DTC" 3 "UNABLE_TO_TEST_DTC";
VAL_ 802 BMS_d009_Over_Temperature 0 "NOT_TESTED_DTC" 1 "PASSED_DTC" 2 "FAILED_DTC" 3 "UNABLE_TO_TEST_DTC";
VAL_ 802 BMS_d010_Precharge_Too_Short 0 "NOT_TESTED_DTC" 1 "PASSED_DTC" 2 "FAILED_DTC" 3 "UNABLE_TO_TEST_DTC";
VAL_ 802 BMS_d011_Precharge_Too_Long 0 "NOT_TESTED_DTC" 1 "PASSED_DTC" 2 "FAILED_DTC" 3 "UNABLE_TO_TEST_DTC";
VAL_ 802 BMS_d012_12V_Undervoltage 0 "NOT_TESTED_DTC" 1 "PASSED_DTC" 2 "FAILED_DTC" 3 "UNABLE_TO_TEST_DTC";
VAL_ 802 BMS_d013_12V_Overvoltage 0 "NOT_TESTED_DTC" 1 "PASSED_DTC" 2 "FAILED_DTC" 3 "UNABLE_TO_TEST_DTC";
VAL_ 802 BMS_d014_Replace_Desiccant 0 "NOT_TESTED_DTC" 1 "PASSED_DTC" 2 "FAILED_DTC" 3 "UNABLE_TO_TEST_DTC";
VAL_ 802 BMS_d015_Flood 0 "NOT_TESTED_DTC" 1 "PASSED_DTC" 2 "FAILED_DTC" 3 "UNABLE_TO_TEST_DTC";

VAL_ 898 BMS_energyBuffer 255 "SNA";
VAL_ 898 BMS_energyToChargeComplete 1023 "SNA";
VAL_ 898 BMS_expectedEnergyRemaining 1023 "SNA";
VAL_ 898 BMS_idealEnergyRemaining 1023 "SNA";
VAL_ 898 BMS_nominalEnergyRemaining 1023 "SNA";
VAL_ 898 BMS_nominalFullPackEnergy 1023 "SNA";

VAL_ 1490 BMS_infoIndex 0 "DEPRECATED_0" 1 "DEPRECATED_1" 2 "DEPRECATED_2" 3 "DEPRECATED_3" 4 "DEPRECATED_4" 5 "DEPRECATED_5" 6 "DEPRECATED_6" 7 "DEPRECATED_7" 8 "DEPRECATED_8" 9 "DEPRECATED_9" 10 "BUILD_HWID_COMPONENTID" 11 "PCBAID_ASSYID_USAGEID" 13 "APP_CRC" 14 "BOOTLOADER_SVN" 15 "BOOTLOADER_CRC" 16 "SUBCOMPONENT" 17 "APP_GITHASH" 18 "BOOTLOADER_GITHASH" 19 "VERSION_DEPRECATED" 20 "UDS_PROTOCOL_BOOTCRC" 255 "END";
VAL_ 1490 BMS_infoBuildType 0 "UNKNOWN_BUILD" 1 "PLATFORM_BUILD" 2 "LOCAL_BUILD" 3 "TRACEABLE_CI_BUILD" 4 "MFG_BUILD";
VAL_ 1490 BMS_infoHardwareRevision 254 "LOCAL_BUILD" 255 "SNA";

VAL_ 978 BMS_kwhChargeTotal 0 "SNA";
VAL_ 978 BMS_kwhDischargeTotal 0 "SNA";

VAL_ 1378 BMS_odometer 4294967295 "SNA";

VAL_ 65 BMS_kwhCounterType 0 "FAST_CHARGER_KWH_COUNTER" 1 "ONBOARD_CHARGER_KWH_COUNTER";
VAL_ 65 BMS_packSOE 1023 "SNA";
VAL_ 65 BMS_socMin 1023 "SNA";
VAL_ 65 BMS_dcChargerKwhTotal 0 "SNA";
VAL_ 65 BMS_acChargerKwhTotal 0 "SNA";

VAL_ 537 BMS_contactorState 0 "OPEN" 1 "PRECHARGE" 2 "CLOSED" 3 "OPENING" 4 "SNA" 5 "WELD" 6 "CLEANING";
VAL_ 537 BMS_contactorStateFC 0 "OPEN" 1 "PRECHARGE" 2 "CLOSED" 3 "SNA";
VAL_ 537 BMS_cpChargeStatus 0 "INACTIVE" 1 "ACTIVE" 2 "COMPLETE" 3 "FAULT" 4 "ENABLING" 5 "UPDATE_IN_PROGRESS";
VAL_ 537 BMS_highestFaultCategory 0 "NONE" 1 "STATISTICS" 2 "NOTICE" 3 "RAMP_DOWN" 4 "IMMEDIATE_SWITCH_OFF" 5 "FUTURE_USE_INHIBIT" 6 "RESERVED" 7 "SNA";
VAL_ 537 BMS_isolationResistance 255 "SNA";
VAL_ 537 BMS_state 0 "STANDBY" 1 "DRIVE" 2 "SUPPORT" 3 "CHARGER" 4 "FASTCHARGE" 5 "CHARGERVOLTAGE" 6 "CLEARFAULT" 7 "FAULT" 8 "WELD" 15 "SNA";

VAL_ 1314 BMS_componentSpecificData 0 "BMS_PRODUCT_METRO" 1 "BMS_PRODUCT_W169EV" 2 "BMS_PRODUCT_W451EV" 3 "BMS_PRODUCT_MODELS" 4 "BMS_PRODUCT_RAV4" 5 "BMS_PRODUCT_RAV4P1" 31 "SNA";
VAL_ 1314 BMS_cpldVersion 254 "LOCAL_BUILD" 255 "SNA";

VAL_ 786 BMS_battTempPct 127 "SNA";
VAL_ 786 BMS_dragStripStatus 0 "OFF" 1 "UNAVAILABLE" 2 "HEATING" 3 "COOLING" 4 "COMPLETE";
VAL_ 786 BMS_dsTargetTimeEst 127 "SNA";
VAL_ 786 BMS_flowRequest 127 "SNA";
VAL_ 786 BMS_inletActiveCoolTargetT 127 "SNA";
VAL_ 786 BMS_inletActiveHeatTargetT 127 "SNA";
VAL_ 786 BMS_inletPassiveTargetT 127 "SNA";
VAL_ 786 BMS_packTemperature -128 "SNA";
VAL_ 786 BMS_powerDissipation 1023 "SNA";

VAL_ 1298 BMS_componentBranchOrigin 255 "SNA";
VAL_ 1298 BMS_componentHardwareId 255 "SNA";
VAL_ 1298 BMS_componentMajorVersion 253 "MFG_BUILD" 254 "LOCAL_BUILD" 255 "SNA";
VAL_ 1298 BMS_componentMaturity 255 "SNA";
VAL_ 1298 BMS_platformBranchOrigin 255 "SNA";
VAL_ 1298 BMS_platformMajorVersion 254 "LOCAL_BUILD" 255 "SNA";
VAL_ 1298 BMS_platformMaturity 255 "SNA";
VAL_ 1298 BMS_platformType 255 "SNA";

VAL_ 926 CC_currentLimit 255 "SNA";
VAL_ 926 CC_gridGrounding 0 "TN-TT" 1 "IT-SplitPhase" 2 "SNA";
VAL_ 926 CC_groundResistance 4095 "SNA";
VAL_ 926 CC_line1Voltage 511 "SNA";
VAL_ 926 CC_line2Voltage 511 "SNA";
VAL_ 926 CC_line3Voltage 511 "SNA";
VAL_ 926 CC_numPhases 0 "SNA";
VAL_ 926 CC_pilotState 0 "READY" 1 "IDLE" 2 "FAULTED" 3 "SNA";

VAL_ 1134 CC_activeConnectorID 255 "SNA";
VAL_ 1134 CC_temperature1 127 "SNA";
VAL_ 1134 CC_temperature2 127 "SNA";
VAL_ 1134 CC_temperature3 127 "SNA";
VAL_ 1134 CC_contactor1Closed 0 "OPEN" 1 "CLOSED" 3 "SNA";
VAL_ 1134 CC_contactor2Closed 0 "OPEN" 1 "CLOSED" 3 "SNA";
VAL_ 1134 CC_temperature4 127 "SNA";
VAL_ 1134 CC_conn1Current 255 "SNA";
VAL_ 1134 CC_conn2Current 255 "SNA";
VAL_ 1134 CC_conn3Current 255 "SNA";
VAL_ 1134 CC_conn4Current 255 "SNA";
VAL_ 1134 CC_lifetimei2t 4294967295 "SNA";
VAL_ 1134 CC_lifetimeCtrCycles 268435455 "SNA";
VAL_ 1134 CC_lifetimeCtrCyclesLoaded 268435455 "SNA";
VAL_ 1134 CC_lifetimeAlertCount 268435455 "SNA";
VAL_ 1134 CC_lifetimeThermalFoldbacks 268435455 "SNA";
VAL_ 1134 CC_lifetimeAvgStartupTemp 16383 "SNA";

VAL_ 592 CA_status1DummySig 0 "SNA";
VAL_ 592 CA_pilotState 0 "SNA" 1 "READY" 2 "ACCEPT";
VAL_ 592 CA_proximityState 0 "SNA" 1 "DISCONNECTED" 2 "UNLATCHED" 3 "LATCHED";
VAL_ 592 CA_swCanRelay 0 "OFF_SNA";
VAL_ 592 CA_flybackEnabled 0 "DISABLED_SNA";
VAL_ 592 CA_bms_vehicleReady 0 "NOT_READY_SNA";
VAL_ 592 CA_bms_connLocked 0 "UNLOCKED_SNA";
VAL_ 592 CA_flybackV 65535 "SNA";
VAL_ 592 CA_flybackTargetV 65535 "SNA";
VAL_ 592 CA_proximityV 65535 "SNA";
VAL_ 592 CA_state 0 "INIT" 1 "WAIT_PROX_LATCHED" 2 "WAIT_PILOT_ACCEPT" 3 "WAIT_VEHICLE_DATA" 4 "WAIT_VEH_CONN_LOCK" 5 "WAIT_SS2_LOW" 6 "WAIT_EVSE_DATA" 7 "WAIT_VEHICLE_READY" 8 "WAIT_EVSE_ISO_TEST" 9 "CHARGING_BUS" 10 "WAIT_VEH_CONTACTORS_CLOSED" 11 "WAIT_EVSE_START" 12 "RUNNING" 13 "NORMAL_SHUTDOWN_1" 14 "NORMAL_SHUTDOWN_2" 15 "NORMAL_SHUTDOWN_3" 16 "IDLE" 17 "EMERGENCY_SHUTDOWN" 18 "FAULT" 19 "WAIT_EVSE_CONN_LOCK" 20 "UNUSED_20" 21 "UNUSED_21" 22 "UNUSED_22" 23 "UNUSED_23" 24 "UNUSED_24" 25 "UNUSED_25" 26 "UNUSED_26" 27 "UNUSED_27" 28 "UNUSED_28" 29 "UNUSED_29" 30 "UNUSED_30" 31 "UNUSED_31" 255 "STATE_SNA";
VAL_ 592 CA_bms_packVoltage 8191 "SNA";
VAL_ 592 CA_evse_ss1Active_GPIO 0 "INACTIVE_SNA";
VAL_ 592 CA_evse_ss2Active_GPIO 0 "INACTIVE_SNA";
VAL_ 592 CA_evse_chgEnable_GPIO 0 "DISABLED_SNA";
VAL_ 592 CA_bms_packCurrent -32768 "SNA";
VAL_ 592 CA_pilotMaxV -32768 "SNA";
VAL_ 592 CA_bms_currentCommand 65535 "SNA";
VAL_ 592 CA_bms_voltageLimit 65535 "SNA";
VAL_ 592 CA_bms_currentLimit 65535 "SNA";
VAL_ 592 CA_bmsStatus 0 "SNA" 1 "MIA" 2 "PRESENT";
VAL_ 592 CA_evseStatus 0 "SNA" 1 "MIA" 2 "PRESENT";
VAL_ 592 CA_dbgStatus 0 "SNA" 1 "MIA" 2 "PRESENT";
VAL_ 592 CA_global_dbg_active 0 "FALSE_SNA";
VAL_ 592 CA_VEH_Flag_BAT_V_Over 0 "FALSE_SNA";
VAL_ 592 CA_VEH_Flag_BAT_V_Under 0 "FALSE_SNA";
VAL_ 592 CA_VEH_Flag_BAT_I_Deviation 0 "FALSE_SNA";
VAL_ 592 CA_VEH_Flag_BAT_T_High 0 "FALSE_SNA";
VAL_ 592 CA_VEH_Flag_BAT_V_Deviation 0 "FALSE_SNA";
VAL_ 592 CA_VEH_Flag_CHR_Enable 0 "FALSE_SNA";
VAL_ 592 CA_VEH_Flag_In_Drive 0 "FALSE_SNA";
VAL_ 592 CA_VEH_Flag_Other_Fault 0 "FALSE_SNA";
VAL_ 592 CA_VEH_Flag_FC_Cont_Open 0 "FALSE_SNA";
VAL_ 592 CA_VEH_Flag_Normal_Stop_Req 0 "FALSE_SNA";
VAL_ 592 CA_EVSE_Flag_CHR_Enabled 0 "FALSE_SNA";
VAL_ 592 CA_EVSE_Flag_CHR_Malfunc 0 "FALSE_SNA";
VAL_ 592 CA_EVSE_Flag_CHR_ConLock 0 "FALSE_SNA";
VAL_ 592 CA_EVSE_Flag_BAT_Incomp 0 "FALSE_SNA";
VAL_ 592 CA_EVSE_Flag_BAT_Malfunc 0 "FALSE_SNA";
VAL_ 592 CA_EVSE_Flag_Stop_Req 0 "FALSE_SNA";
VAL_ 592 CA_fc_dcVoltage 65535 "SNA";
VAL_ 592 CA_voltageRail12V 65535 "SNA";
VAL_ 592 CA_pilotDrv 0 "LOW" 1 "HIGH" 2 "PWM" 3 "DRIVE_SNA";
VAL_ 592 CA_flybackState 0 "SNA" 1 "OFF" 2 "DRV" 3 "MON";
VAL_ 592 CA_flybackTargetState 0 "SNA" 1 "OFF" 2 "DRV" 3 "MON";
VAL_ 592 CA_EVSE_Present_V_Out 65535 "SNA";
VAL_ 592 CA_EVSE_Present_I_Out 255 "SNA";
VAL_ 592 CA_VEH_Request_I 255 "SNA";
VAL_ 592 CA_flybackMaxV 65535 "SNA";
VAL_ 592 CA_shutdownSource 0 "NONE_SNA" 1 "ADAPTER" 2 "BMS" 3 "STATION";
VAL_ 592 CA_shutdownReason 0 "NONE_SNA" 1 "PROX_NO_LATCH" 2 "BMS_VEH_N_RDY" 3 "EVSE_STOP_REQ" 4 "STD_FAULT" 5 "CRIT_FAULT";

VAL_ 593 CA_status2DummySig 0 "SNA";
VAL_ 593 CA_VEH_Ext_Protocol_Ver 255 "SNA";
VAL_ 593 CA_EVSE_Ext_Protocol_Ver 255 "SNA";
VAL_ 593 CA_FC_protocolVersion 255 "SNA";
VAL_ 593 CA_BMS_protocolVersion 255 "SNA";
VAL_ 593 CA_VEH_BAT_V_Target 65535 "SNA";
VAL_ 593 CA_VEH_BAT_SOC 0 "SNA";
VAL_ 593 CA_EVSE_Threshold_V 65535 "SNA";
VAL_ 593 CA_EVSE_Avail_V_Out 65535 "SNA";
VAL_ 593 CA_EVSE_Avail_I_Out 255 "SNA";
VAL_ 593 CA_flybackVoltageLimit 65535 "SNA";
VAL_ 593 CA_vehConnTempDegC -32768 "SNA";
VAL_ 593 CA_evseConnTempDegC -32768 "SNA";
VAL_ 593 CA_pcbaTempDegC -32768 "SNA";
VAL_ 593 CA_vehConnTempV 65535 "SNA";
VAL_ 593 CA_evseConnTempV 65535 "SNA";
VAL_ 593 CA_pcbaTempV 65535 "SNA";

VAL_ 1335 CHGPH1_infoIndex 0 "DEPRECATED_0" 1 "DEPRECATED_1" 2 "DEPRECATED_2" 3 "DEPRECATED_3" 4 "DEPRECATED_4" 5 "DEPRECATED_5" 6 "DEPRECATED_6" 7 "DEPRECATED_7" 8 "DEPRECATED_8" 9 "DEPRECATED_9" 10 "BUILD_HWID_COMPONENTID" 11 "PCBAID_ASSYID_USAGEID" 13 "APP_CRC" 14 "BOOTLOADER_SVN" 15 "BOOTLOADER_CRC" 16 "SUBCOMPONENT" 17 "APP_GITHASH" 18 "BOOTLOADER_GITHASH" 19 "VERSION_DEPRECATED" 20 "UDS_PROTOCOL_BOOTCRC" 255 "END";
VAL_ 1335 CHGPH1_infoBuildType 0 "UNKNOWN_BUILD" 1 "PLATFORM_BUILD" 2 "LOCAL_BUILD" 3 "TRACEABLE_CI_BUILD" 4 "MFG_BUILD";
VAL_ 1335 CHGPH1_infoMajorVersion 254 "LOCAL_BUILD" 255 "SNA";
VAL_ 1335 CHGPH1_infoBranchOrigin 254 "LOCAL_BUILD" 255 "SNA";
VAL_ 1335 CHGPH1_infoMaturity 254 "LOCAL_BUILD" 255 "SNA";
VAL_ 1335 CHGPH1_infoHardwareRevision 254 "LOCAL_BUILD" 255 "SNA";

VAL_ 1337 CHGPH2_infoIndex 0 "DEPRECATED_0" 1 "DEPRECATED_1" 2 "DEPRECATED_2" 3 "DEPRECATED_3" 4 "DEPRECATED_4" 5 "DEPRECATED_5" 6 "DEPRECATED_6" 7 "DEPRECATED_7" 8 "DEPRECATED_8" 9 "DEPRECATED_9" 10 "BUILD_HWID_COMPONENTID" 11 "PCBAID_ASSYID_USAGEID" 13 "APP_CRC" 14 "BOOTLOADER_SVN" 15 "BOOTLOADER_CRC" 16 "SUBCOMPONENT" 17 "APP_GITHASH" 18 "BOOTLOADER_GITHASH" 19 "VERSION_DEPRECATED" 20 "UDS_PROTOCOL_BOOTCRC" 255 "END";
VAL_ 1337 CHGPH2_infoBuildType 0 "UNKNOWN_BUILD" 1 "PLATFORM_BUILD" 2 "LOCAL_BUILD" 3 "TRACEABLE_CI_BUILD" 4 "MFG_BUILD";
VAL_ 1337 CHGPH2_infoMajorVersion 254 "LOCAL_BUILD" 255 "SNA";
VAL_ 1337 CHGPH2_infoBranchOrigin 254 "LOCAL_BUILD" 255 "SNA";
VAL_ 1337 CHGPH2_infoMaturity 254 "LOCAL_BUILD" 255 "SNA";
VAL_ 1337 CHGPH2_infoHardwareRevision 254 "LOCAL_BUILD" 255 "SNA";

VAL_ 1339 CHGPH3_infoIndex 0 "DEPRECATED_0" 1 "DEPRECATED_1" 2 "DEPRECATED_2" 3 "DEPRECATED_3" 4 "DEPRECATED_4" 5 "DEPRECATED_5" 6 "DEPRECATED_6" 7 "DEPRECATED_7" 8 "DEPRECATED_8" 9 "DEPRECATED_9" 10 "BUILD_HWID_COMPONENTID" 11 "PCBAID_ASSYID_USAGEID" 13 "APP_CRC" 14 "BOOTLOADER_SVN" 15 "BOOTLOADER_CRC" 16 "SUBCOMPONENT" 17 "APP_GITHASH" 18 "BOOTLOADER_GITHASH" 19 "VERSION_DEPRECATED" 20 "UDS_PROTOCOL_BOOTCRC" 255 "END";
VAL_ 1339 CHGPH3_infoBuildType 0 "UNKNOWN_BUILD" 1 "PLATFORM_BUILD" 2 "LOCAL_BUILD" 3 "TRACEABLE_CI_BUILD" 4 "MFG_BUILD";
VAL_ 1339 CHGPH3_infoMajorVersion 254 "LOCAL_BUILD" 255 "SNA";
VAL_ 1339 CHGPH3_infoBranchOrigin 254 "LOCAL_BUILD" 255 "SNA";
VAL_ 1339 CHGPH3_infoMaturity 254 "LOCAL_BUILD" 255 "SNA";
VAL_ 1339 CHGPH3_infoHardwareRevision 254 "LOCAL_BUILD" 255 "SNA";

VAL_ 1388 CHGRLY_infoIndex 0 "DEPRECATED_0" 1 "DEPRECATED_1" 2 "DEPRECATED_2" 3 "DEPRECATED_3" 4 "DEPRECATED_4" 5 "DEPRECATED_5" 6 "DEPRECATED_6" 7 "DEPRECATED_7" 8 "DEPRECATED_8" 9 "DEPRECATED_9" 10 "BUILD_HWID_COMPONENTID" 11 "PCBAID_ASSYID_USAGEID" 13 "APP_CRC" 14 "BOOTLOADER_SVN" 15 "BOOTLOADER_CRC" 16 "SUBCOMPONENT" 17 "APP_GITHASH" 18 "BOOTLOADER_GITHASH" 19 "VERSION_DEPRECATED" 20 "UDS_PROTOCOL_BOOTCRC" 255 "END";
VAL_ 1388 CHGRLY_buildType 0 "UNKNOWN_BUILD" 1 "PLATFORM_BUILD" 2 "LOCAL_BUILD" 3 "TRACEABLE_CI_BUILD" 4 "MFG_BUILD";

VAL_ 1463 CHGSPH1_infoIndex 0 "DEPRECATED_0" 1 "DEPRECATED_1" 2 "DEPRECATED_2" 3 "DEPRECATED_3" 4 "DEPRECATED_4" 5 "DEPRECATED_5" 6 "DEPRECATED_6" 7 "DEPRECATED_7" 8 "DEPRECATED_8" 9 "DEPRECATED_9" 10 "BUILD_HWID_COMPONENTID" 11 "PCBAID_ASSYID_USAGEID" 13 "APP_CRC" 14 "BOOTLOADER_SVN" 15 "BOOTLOADER_CRC" 16 "SUBCOMPONENT" 17 "APP_GITHASH" 18 "BOOTLOADER_GITHASH" 19 "VERSION_DEPRECATED" 20 "UDS_PROTOCOL_BOOTCRC" 255 "END";
VAL_ 1463 CHGSPH1_infoBuildType 0 "UNKNOWN_BUILD" 1 "PLATFORM_BUILD" 2 "LOCAL_BUILD" 3 "TRACEABLE_CI_BUILD" 4 "MFG_BUILD";
VAL_ 1463 CHGSPH1_infoMajorVersion 254 "LOCAL_BUILD" 255 "SNA";
VAL_ 1463 CHGSPH1_infoBranchOrigin 254 "LOCAL_BUILD" 255 "SNA";
VAL_ 1463 CHGSPH1_infoMaturity 254 "LOCAL_BUILD" 255 "SNA";
VAL_ 1463 CHGSPH1_infoHardwareRevision 254 "LOCAL_BUILD" 255 "SNA";

VAL_ 1465 CHGSPH2_infoIndex 0 "DEPRECATED_0" 1 "DEPRECATED_1" 2 "DEPRECATED_2" 3 "DEPRECATED_3" 4 "DEPRECATED_4" 5 "DEPRECATED_5" 6 "DEPRECATED_6" 7 "DEPRECATED_7" 8 "DEPRECATED_8" 9 "DEPRECATED_9" 10 "BUILD_HWID_COMPONENTID" 11 "PCBAID_ASSYID_USAGEID" 13 "APP_CRC" 14 "BOOTLOADER_SVN" 15 "BOOTLOADER_CRC" 16 "SUBCOMPONENT" 17 "APP_GITHASH" 18 "BOOTLOADER_GITHASH" 19 "VERSION_DEPRECATED" 20 "UDS_PROTOCOL_BOOTCRC" 255 "END";
VAL_ 1465 CHGSPH2_infoBuildType 0 "UNKNOWN_BUILD" 1 "PLATFORM_BUILD" 2 "LOCAL_BUILD" 3 "TRACEABLE_CI_BUILD" 4 "MFG_BUILD";
VAL_ 1465 CHGSPH2_infoMajorVersion 254 "LOCAL_BUILD" 255 "SNA";
VAL_ 1465 CHGSPH2_infoBranchOrigin 254 "LOCAL_BUILD" 255 "SNA";
VAL_ 1465 CHGSPH2_infoMaturity 254 "LOCAL_BUILD" 255 "SNA";
VAL_ 1465 CHGSPH2_infoHardwareRevision 254 "LOCAL_BUILD" 255 "SNA";

VAL_ 1467 CHGSPH3_infoIndex 0 "DEPRECATED_0" 1 "DEPRECATED_1" 2 "DEPRECATED_2" 3 "DEPRECATED_3" 4 "DEPRECATED_4" 5 "DEPRECATED_5" 6 "DEPRECATED_6" 7 "DEPRECATED_7" 8 "DEPRECATED_8" 9 "DEPRECATED_9" 10 "BUILD_HWID_COMPONENTID" 11 "PCBAID_ASSYID_USAGEID" 13 "APP_CRC" 14 "BOOTLOADER_SVN" 15 "BOOTLOADER_CRC" 16 "SUBCOMPONENT" 17 "APP_GITHASH" 18 "BOOTLOADER_GITHASH" 19 "VERSION_DEPRECATED" 20 "UDS_PROTOCOL_BOOTCRC" 255 "END";
VAL_ 1467 CHGSPH3_infoBuildType 0 "UNKNOWN_BUILD" 1 "PLATFORM_BUILD" 2 "LOCAL_BUILD" 3 "TRACEABLE_CI_BUILD" 4 "MFG_BUILD";
VAL_ 1467 CHGSPH3_infoMajorVersion 254 "LOCAL_BUILD" 255 "SNA";
VAL_ 1467 CHGSPH3_infoBranchOrigin 254 "LOCAL_BUILD" 255 "SNA";
VAL_ 1467 CHGSPH3_infoMaturity 254 "LOCAL_BUILD" 255 "SNA";
VAL_ 1467 CHGSPH3_infoHardwareRevision 254 "LOCAL_BUILD" 255 "SNA";

VAL_ 956 CHGS_d001_replaceCharger 0 "NOT_TESTED_DTC" 1 "PASSED_DTC" 2 "FAILED_DTC" 3 "UNABLE_TO_TEST_DTC";
VAL_ 956 CHGS_d002_12VOV 0 "NOT_TESTED_DTC" 1 "PASSED_DTC" 2 "FAILED_DTC" 3 "UNABLE_TO_TEST_DTC";
VAL_ 956 CHGS_d003_12VUV 0 "NOT_TESTED_DTC" 1 "PASSED_DTC" 2 "FAILED_DTC" 3 "UNABLE_TO_TEST_DTC";
VAL_ 956 CHGS_d004_overTemp 0 "NOT_TESTED_DTC" 1 "PASSED_DTC" 2 "FAILED_DTC" 3 "UNABLE_TO_TEST_DTC";
VAL_ 956 CHGS_d005_lowFlow 0 "NOT_TESTED_DTC" 1 "PASSED_DTC" 2 "FAILED_DTC" 3 "UNABLE_TO_TEST_DTC";
VAL_ 956 CHGS_d006_HVUV 0 "NOT_TESTED_DTC" 1 "PASSED_DTC" 2 "FAILED_DTC" 3 "UNABLE_TO_TEST_DTC";
VAL_ 956 CHGS_d007_FCFuseBlown 0 "NOT_TESTED_DTC" 1 "PASSED_DTC" 2 "FAILED_DTC" 3 "UNABLE_TO_TEST_DTC";
VAL_ 956 CHGS_d008_FCWeld 0 "NOT_TESTED_DTC" 1 "PASSED_DTC" 2 "FAILED_DTC" 3 "UNABLE_TO_TEST_DTC";
VAL_ 956 CHGS_d009_FCWontClose 0 "NOT_TESTED_DTC" 1 "PASSED_DTC" 2 "FAILED_DTC" 3 "UNABLE_TO_TEST_DTC";
VAL_ 956 CHGS_d010_FCCnctrPower 0 "NOT_TESTED_DTC" 1 "PASSED_DTC" 2 "FAILED_DTC" 3 "UNABLE_TO_TEST_DTC";
VAL_ 956 CHGS_d011_proxRationality 0 "NOT_TESTED_DTC" 1 "PASSED_DTC" 2 "FAILED_DTC" 3 "UNABLE_TO_TEST_DTC";
VAL_ 956 CHGS_d012_lostComms 0 "NOT_TESTED_DTC" 1 "PASSED_DTC" 2 "FAILED_DTC" 3 "UNABLE_TO_TEST_DTC";
VAL_ 956 CHGS_d013_HVIL 0 "NOT_TESTED_DTC" 1 "PASSED_DTC" 2 "FAILED_DTC" 3 "UNABLE_TO_TEST_DTC";
VAL_ 956 CHGS_d014_15VUV 0 "NOT_TESTED_DTC" 1 "PASSED_DTC" 2 "FAILED_DTC" 3 "UNABLE_TO_TEST_DTC";
VAL_ 956 CHGS_d015_unused 0 "NOT_TESTED_DTC" 1 "PASSED_DTC" 2 "FAILED_DTC" 3 "UNABLE_TO_TEST_DTC";
VAL_ 956 CHGS_d016_unused 0 "NOT_TESTED_DTC" 1 "PASSED_DTC" 2 "FAILED_DTC" 3 "UNABLE_TO_TEST_DTC";
VAL_ 956 CHGS_d017_unused 0 "NOT_TESTED_DTC" 1 "PASSED_DTC" 2 "FAILED_DTC" 3 "UNABLE_TO_TEST_DTC";
VAL_ 956 CHGS_d018_unused 0 "NOT_TESTED_DTC" 1 "PASSED_DTC" 2 "FAILED_DTC" 3 "UNABLE_TO_TEST_DTC";
VAL_ 956 CHGS_d019_unused 0 "NOT_TESTED_DTC" 1 "PASSED_DTC" 2 "FAILED_DTC" 3 "UNABLE_TO_TEST_DTC";
VAL_ 956 CHGS_d020_unused 0 "NOT_TESTED_DTC" 1 "PASSED_DTC" 2 "FAILED_DTC" 3 "UNABLE_TO_TEST_DTC";
VAL_ 956 CHGS_d021_unused 0 "NOT_TESTED_DTC" 1 "PASSED_DTC" 2 "FAILED_DTC" 3 "UNABLE_TO_TEST_DTC";
VAL_ 956 CHGS_d022_unused 0 "NOT_TESTED_DTC" 1 "PASSED_DTC" 2 "FAILED_DTC" 3 "UNABLE_TO_TEST_DTC";
VAL_ 956 CHGS_d023_unused 0 "NOT_TESTED_DTC" 1 "PASSED_DTC" 2 "FAILED_DTC" 3 "UNABLE_TO_TEST_DTC";
VAL_ 956 CHGS_d024_unused 0 "NOT_TESTED_DTC" 1 "PASSED_DTC" 2 "FAILED_DTC" 3 "UNABLE_TO_TEST_DTC";
VAL_ 956 CHGS_d025_unused 0 "NOT_TESTED_DTC" 1 "PASSED_DTC" 2 "FAILED_DTC" 3 "UNABLE_TO_TEST_DTC";
VAL_ 956 CHGS_d026_unused 0 "NOT_TESTED_DTC" 1 "PASSED_DTC" 2 "FAILED_DTC" 3 "UNABLE_TO_TEST_DTC";
VAL_ 956 CHGS_d027_unused 0 "NOT_TESTED_DTC" 1 "PASSED_DTC" 2 "FAILED_DTC" 3 "UNABLE_TO_TEST_DTC";
VAL_ 956 CHGS_d028_unused 0 "NOT_TESTED_DTC" 1 "PASSED_DTC" 2 "FAILED_DTC" 3 "UNABLE_TO_TEST_DTC";

VAL_ 1468 CHGS_infoIndex 0 "DEPRECATED_0" 1 "DEPRECATED_1" 2 "DEPRECATED_2" 3 "DEPRECATED_3" 4 "DEPRECATED_4" 5 "DEPRECATED_5" 6 "DEPRECATED_6" 7 "DEPRECATED_7" 8 "DEPRECATED_8" 9 "DEPRECATED_9" 10 "BUILD_HWID_COMPONENTID" 11 "PCBAID_ASSYID_USAGEID" 13 "APP_CRC" 14 "BOOTLOADER_SVN" 15 "BOOTLOADER_CRC" 16 "SUBCOMPONENT" 17 "APP_GITHASH" 18 "BOOTLOADER_GITHASH" 19 "VERSION_DEPRECATED" 20 "UDS_PROTOCOL_BOOTCRC" 255 "END";
VAL_ 1468 CHGS_infoBuildType 0 "UNKNOWN_BUILD" 1 "PLATFORM_BUILD" 2 "LOCAL_BUILD" 3 "TRACEABLE_CI_BUILD" 4 "MFG_BUILD";
VAL_ 1468 CHGS_infoAssemblyID 255 "CHG_ASSEMBLY_SNA";
VAL_ 1468 CHGS_infoMajorVersion 254 "LOCAL_BUILD" 255 "SNA";
VAL_ 1468 CHGS_infoBranchOrigin 254 "LOCAL_BUILD" 255 "SNA";
VAL_ 1468 CHGS_infoMaturity 254 "LOCAL_BUILD" 255 "SNA";
VAL_ 1468 CHGS_infoHardwareRevision 254 "LOCAL_BUILD" 255 "SNA";

VAL_ 652 CHGS_numPhases 0 "NUM_PHASES_SNA";

VAL_ 668 CHGS_cableState 0 "NOT_CONNECTED" 1 "CONNECTED" 2 "UNKNOWN_SNA";
VAL_ 668 CHGS_mainState 0 "STANDBY" 1 "CLEAR_FAULT" 2 "FAULT" 3 "PRECHARGE" 4 "ENABLE" 5 "FC_STARTUP" 6 "FC_ENABLE";
VAL_ 668 CHGS_phaseConfig 0 "SINGLE_PHASE" 1 "THREE_PHASE" 2 "TWO_PHASE_DELTA_TWO_CHGPH" 3 "TWO_PHASE_DELTA_THREE_CHGPH" 4 "PHASE_CONFIG_SNA";
VAL_ 668 CHGS_pilot 0 "NONE" 1 "FAULTED" 2 "LINE_CHARGE" 3 "FAST_CHARGE" 4 "IDLE" 5 "INVALID" 6 "UNUSED_6" 7 "SNA";
VAL_ 668 CHGS_proximity 0 "SNA" 1 "DISCONNECTED" 2 "UNLATCHED" 3 "LATCHED";
VAL_ 668 CHGS_subState 0 "STARTUP" 1 "IDLE" 2 "TRANSITION_TO_PRECHARGE" 3 "WAIT_ACCEPT" 4 "ACCEPT" 5 "HAVE_VLINE" 6 "FAILED_TO_START" 7 "PRECHARGE" 8 "PRECHARGE_INITIAL_TEST" 9 "PRECHARGE_WAIT_FINAL" 10 "PRECHARGE_FINAL_TEST" 11 "WAIT_ARM_PWM" 12 "ARM_PWM" 13 "CHECK_PWM_ENABLED" 14 "TRANSITION_TO_ENABLE" 15 "PWM_ON" 16 "ANTISPARK_ON" 17 "ANTISPARK_CLOSED" 18 "ENABLE_PID" 19 "PRECHARGE_OFF" 20 "RAMP_CURRENT" 21 "CHARGING" 22 "SOFTWARE_FAULT" 23 "FAULTED" 24 "CLRFLT" 25 "CLRFLT_GATE_DRV_OFF_1" 26 "CLRFLT_GATE_DRV_OFF_2" 27 "CLRFLT_GATE_DRV_ON" 28 "CLRFLT_DRV_STABLE" 29 "CLRFLT_DONE" 30 "SOFT_SHUTDOWN" 31 "CURRENT_OFF" 32 "OPEN_RELAYS" 33 "CHECK_USER_ALERTS" 34 "DELAY_TO_IDLE" 35 "RETRY" 36 "FORCE_SHUTDOWN" 37 "WAIT_NUMPHASES" 38 "SET_PRECHARGE_TARGET" 39 "WAIT_ACCEPT_DIGITAL_COMMS" 40 "ACCEPT_DIGITAL_COMMS" 41 "WAIT_DIGITAL_COMMS" 42 "DIGITAL_COMMS" 43 "WAIT_CHGPH_SHUTDOWN" 44 "44" 45 "45" 46 "46" 47 "47" 48 "48" 49 "49" 50 "50";

VAL_ 1452 CHGS_cpldVersion 254 "LOCAL_BUILD" 255 "SNA";

VAL_ 700 CHGS_igbtTempMax 255 "SNA";
VAL_ 700 CHGS_igbtTemperature 255 "SNA";
VAL_ 700 CHGS_inletPassiveTarget 255 "SNA";
VAL_ 700 CHGS_magneticsTempMax 255 "SNA";
VAL_ 700 CHGS_magneticsTemperature 255 "SNA";
VAL_ 700 CHGS_outletTemperature 255 "SNA";

VAL_ 716 CHGS_tempPercent 255 "TEMP_PERCENT_SNA";

VAL_ 1436 CHGS_componentBranchOrigin 254 "LOCAL_BUILD" 255 "SNA";
VAL_ 1436 CHGS_componentHardwareRevision 254 "LOCAL_BUILD" 255 "SNA";
VAL_ 1436 CHGS_componentMajorVersion 254 "LOCAL_BUILD" 255 "SNA";
VAL_ 1436 CHGS_componentMaturity 254 "LOCAL_BUILD" 255 "SNA";

VAL_ 828 CHG_d001_replaceCharger 0 "NOT_TESTED_DTC" 1 "PASSED_DTC" 2 "FAILED_DTC" 3 "UNABLE_TO_TEST_DTC";
VAL_ 828 CHG_d002_12VOV 0 "NOT_TESTED_DTC" 1 "PASSED_DTC" 2 "FAILED_DTC" 3 "UNABLE_TO_TEST_DTC";
VAL_ 828 CHG_d003_12VUV 0 "NOT_TESTED_DTC" 1 "PASSED_DTC" 2 "FAILED_DTC" 3 "UNABLE_TO_TEST_DTC";
VAL_ 828 CHG_d004_overTemp 0 "NOT_TESTED_DTC" 1 "PASSED_DTC" 2 "FAILED_DTC" 3 "UNABLE_TO_TEST_DTC";
VAL_ 828 CHG_d005_lowFlow 0 "NOT_TESTED_DTC" 1 "PASSED_DTC" 2 "FAILED_DTC" 3 "UNABLE_TO_TEST_DTC";
VAL_ 828 CHG_d006_HVUV 0 "NOT_TESTED_DTC" 1 "PASSED_DTC" 2 "FAILED_DTC" 3 "UNABLE_TO_TEST_DTC";
VAL_ 828 CHG_d007_FCFuseBlown 0 "NOT_TESTED_DTC" 1 "PASSED_DTC" 2 "FAILED_DTC" 3 "UNABLE_TO_TEST_DTC";
VAL_ 828 CHG_d008_FCWeld 0 "NOT_TESTED_DTC" 1 "PASSED_DTC" 2 "FAILED_DTC" 3 "UNABLE_TO_TEST_DTC";
VAL_ 828 CHG_d009_FCWontClose 0 "NOT_TESTED_DTC" 1 "PASSED_DTC" 2 "FAILED_DTC" 3 "UNABLE_TO_TEST_DTC";
VAL_ 828 CHG_d010_FCCnctrPower 0 "NOT_TESTED_DTC" 1 "PASSED_DTC" 2 "FAILED_DTC" 3 "UNABLE_TO_TEST_DTC";
VAL_ 828 CHG_d011_proxRationality 0 "NOT_TESTED_DTC" 1 "PASSED_DTC" 2 "FAILED_DTC" 3 "UNABLE_TO_TEST_DTC";
VAL_ 828 CHG_d012_lostComms 0 "NOT_TESTED_DTC" 1 "PASSED_DTC" 2 "FAILED_DTC" 3 "UNABLE_TO_TEST_DTC";
VAL_ 828 CHG_d013_HVIL 0 "NOT_TESTED_DTC" 1 "PASSED_DTC" 2 "FAILED_DTC" 3 "UNABLE_TO_TEST_DTC";
VAL_ 828 CHG_d014_15VUV 0 "NOT_TESTED_DTC" 1 "PASSED_DTC" 2 "FAILED_DTC" 3 "UNABLE_TO_TEST_DTC";
VAL_ 828 CHG_d015_unused 0 "NOT_TESTED_DTC" 1 "PASSED_DTC" 2 "FAILED_DTC" 3 "UNABLE_TO_TEST_DTC";
VAL_ 828 CHG_d016_unused 0 "NOT_TESTED_DTC" 1 "PASSED_DTC" 2 "FAILED_DTC" 3 "UNABLE_TO_TEST_DTC";
VAL_ 828 CHG_d017_unused 0 "NOT_TESTED_DTC" 1 "PASSED_DTC" 2 "FAILED_DTC" 3 "UNABLE_TO_TEST_DTC";
VAL_ 828 CHG_d018_unused 0 "NOT_TESTED_DTC" 1 "PASSED_DTC" 2 "FAILED_DTC" 3 "UNABLE_TO_TEST_DTC";
VAL_ 828 CHG_d019_unused 0 "NOT_TESTED_DTC" 1 "PASSED_DTC" 2 "FAILED_DTC" 3 "UNABLE_TO_TEST_DTC";
VAL_ 828 CHG_d020_unused 0 "NOT_TESTED_DTC" 1 "PASSED_DTC" 2 "FAILED_DTC" 3 "UNABLE_TO_TEST_DTC";
VAL_ 828 CHG_d021_unused 0 "NOT_TESTED_DTC" 1 "PASSED_DTC" 2 "FAILED_DTC" 3 "UNABLE_TO_TEST_DTC";
VAL_ 828 CHG_d022_unused 0 "NOT_TESTED_DTC" 1 "PASSED_DTC" 2 "FAILED_DTC" 3 "UNABLE_TO_TEST_DTC";
VAL_ 828 CHG_d023_unused 0 "NOT_TESTED_DTC" 1 "PASSED_DTC" 2 "FAILED_DTC" 3 "UNABLE_TO_TEST_DTC";
VAL_ 828 CHG_d024_unused 0 "NOT_TESTED_DTC" 1 "PASSED_DTC" 2 "FAILED_DTC" 3 "UNABLE_TO_TEST_DTC";
VAL_ 828 CHG_d025_unused 0 "NOT_TESTED_DTC" 1 "PASSED_DTC" 2 "FAILED_DTC" 3 "UNABLE_TO_TEST_DTC";
VAL_ 828 CHG_d026_unused 0 "NOT_TESTED_DTC" 1 "PASSED_DTC" 2 "FAILED_DTC" 3 "UNABLE_TO_TEST_DTC";
VAL_ 828 CHG_d027_unused 0 "NOT_TESTED_DTC" 1 "PASSED_DTC" 2 "FAILED_DTC" 3 "UNABLE_TO_TEST_DTC";
VAL_ 828 CHG_d028_unused 0 "NOT_TESTED_DTC" 1 "PASSED_DTC" 2 "FAILED_DTC" 3 "UNABLE_TO_TEST_DTC";

VAL_ 1340 CHG_infoIndex 0 "DEPRECATED_0" 1 "DEPRECATED_1" 2 "DEPRECATED_2" 3 "DEPRECATED_3" 4 "DEPRECATED_4" 5 "DEPRECATED_5" 6 "DEPRECATED_6" 7 "DEPRECATED_7" 8 "DEPRECATED_8" 9 "DEPRECATED_9" 10 "BUILD_HWID_COMPONENTID" 11 "PCBAID_ASSYID_USAGEID" 13 "APP_CRC" 14 "BOOTLOADER_SVN" 15 "BOOTLOADER_CRC" 16 "SUBCOMPONENT" 17 "APP_GITHASH" 18 "BOOTLOADER_GITHASH" 19 "VERSION_DEPRECATED" 20 "UDS_PROTOCOL_BOOTCRC" 255 "END";
VAL_ 1340 CHG_infoBuildType 0 "UNKNOWN_BUILD" 1 "PLATFORM_BUILD" 2 "LOCAL_BUILD" 3 "TRACEABLE_CI_BUILD" 4 "MFG_BUILD";
VAL_ 1340 CHG_infoAssemblyID 255 "CHG_ASSEMBLY_SNA";
VAL_ 1340 CHG_infoMajorVersion 254 "LOCAL_BUILD" 255 "SNA";
VAL_ 1340 CHG_infoBranchOrigin 254 "LOCAL_BUILD" 255 "SNA";
VAL_ 1340 CHG_infoMaturity 254 "LOCAL_BUILD" 255 "SNA";
VAL_ 1340 CHG_infoHardwareRevision 254 "LOCAL_BUILD" 255 "SNA";

VAL_ 524 CHG_numPhases 0 "NUM_PHASES_SNA";

VAL_ 540 CHG_cableState 0 "NOT_CONNECTED" 1 "CONNECTED" 2 "UNKNOWN_SNA";
VAL_ 540 CHG_cableType 0 "IEC" 1 "SAE" 2 "GB_AC" 3 "GB_DC" 4 "SNA";
VAL_ 540 CHG_inputRelayState 0 "L2_CLOSED" 1 "L1_CLOSED" 2 "OPEN" 3 "SNA";
VAL_ 540 CHG_mainState 0 "STANDBY" 1 "CLEAR_FAULT" 2 "FAULT" 3 "PRECHARGE" 4 "ENABLE" 5 "FC_STARTUP" 6 "FC_ENABLE";
VAL_ 540 CHG_phaseConfig 0 "SINGLE_PHASE" 1 "THREE_PHASE" 2 "TWO_PHASE_DELTA_TWO_CHGPH" 3 "TWO_PHASE_DELTA_THREE_CHGPH" 4 "PHASE_CONFIG_SNA";
VAL_ 540 CHG_pilot 0 "NONE" 1 "FAULTED" 2 "LINE_CHARGE" 3 "FAST_CHARGE" 4 "IDLE" 5 "INVALID" 6 "UNUSED_6" 7 "SNA";
VAL_ 540 CHG_proximity 0 "SNA" 1 "DISCONNECTED" 2 "UNLATCHED" 3 "LATCHED";
VAL_ 540 CHG_subState 0 "STARTUP" 1 "IDLE" 2 "TRANSITION_TO_PRECHARGE" 3 "WAIT_ACCEPT" 4 "ACCEPT" 5 "HAVE_VLINE" 6 "FAILED_TO_START" 7 "PRECHARGE" 8 "PRECHARGE_INITIAL_TEST" 9 "PRECHARGE_WAIT_FINAL" 10 "PRECHARGE_FINAL_TEST" 11 "WAIT_ARM_PWM" 12 "ARM_PWM" 13 "CHECK_PWM_ENABLED" 14 "TRANSITION_TO_ENABLE" 15 "PWM_ON" 16 "ANTISPARK_ON" 17 "ANTISPARK_CLOSED" 18 "ENABLE_PID" 19 "PRECHARGE_OFF" 20 "RAMP_CURRENT" 21 "CHARGING" 22 "SOFTWARE_FAULT" 23 "FAULTED" 24 "CLRFLT" 25 "CLRFLT_GATE_DRV_OFF_1" 26 "CLRFLT_GATE_DRV_OFF_2" 27 "CLRFLT_GATE_DRV_ON" 28 "CLRFLT_DRV_STABLE" 29 "CLRFLT_DONE" 30 "SOFT_SHUTDOWN" 31 "CURRENT_OFF" 32 "OPEN_RELAYS" 33 "CHECK_USER_ALERTS" 34 "DELAY_TO_IDLE" 35 "RETRY" 36 "FORCE_SHUTDOWN" 37 "WAIT_NUMPHASES" 38 "SET_PRECHARGE_TARGET" 39 "WAIT_ACCEPT_DIGITAL_COMMS" 40 "ACCEPT_DIGITAL_COMMS" 41 "WAIT_DIGITAL_COMMS" 42 "DIGITAL_COMMS" 43 "WAIT_CHGPH_SHUTDOWN" 44 "44" 45 "45" 46 "46" 47 "47" 48 "48" 49 "49" 50 "50";

VAL_ 1324 CHG_cpldVersion 254 "LOCAL_BUILD" 255 "SNA";

VAL_ 572 CHG_igbtTempMax 255 "SNA";
VAL_ 572 CHG_igbtTemperature 255 "SNA";
VAL_ 572 CHG_inletPassiveTarget 255 "SNA";
VAL_ 572 CHG_magneticsTempMax 255 "SNA";
VAL_ 572 CHG_magneticsTemperature 255 "SNA";
VAL_ 572 CHG_outletTemperature 255 "SNA";

VAL_ 588 CHG_tempPercent 255 "TEMP_PERCENT_SNA";

VAL_ 1308 CHG_componentBranchOrigin 254 "LOCAL_BUILD" 255 "SNA";
VAL_ 1308 CHG_componentHardwareRevision 254 "LOCAL_BUILD" 255 "SNA";
VAL_ 1308 CHG_componentMajorVersion 254 "LOCAL_BUILD" 255 "SNA";
VAL_ 1308 CHG_componentMaturity 254 "LOCAL_BUILD" 255 "SNA";

VAL_ 867 CMP_componentBranchOrigin 253 "MANUFACTURING_BUILD" 254 "LOCAL_BUILD" 255 "SNA";
VAL_ 867 CMP_componentMajorVersion 253 "MANUFACTURING_BUILD" 254 "LOCAL_BUILD" 255 "SNA";
VAL_ 867 CMP_componentMaturity 253 "MANUFACTURING_BUILD" 254 "LOCAL_BUILD" 255 "SNA";

VAL_ 1342 CP_infoIndex 0 "DEPRECATED_0" 1 "DEPRECATED_1" 2 "DEPRECATED_2" 3 "DEPRECATED_3" 4 "DEPRECATED_4" 5 "DEPRECATED_5" 6 "DEPRECATED_6" 7 "DEPRECATED_7" 8 "DEPRECATED_8" 9 "DEPRECATED_9" 10 "BUILD_HWID_COMPONENTID" 11 "PCBAID_ASSYID_USAGEID" 13 "APP_CRC" 14 "BOOTLOADER_SVN" 15 "BOOTLOADER_CRC" 16 "SUBCOMPONENT" 17 "APP_GITHASH" 18 "BOOTLOADER_GITHASH" 19 "VERSION_DEPRECATED" 20 "UDS_PROTOCOL_BOOTCRC" 255 "END";
VAL_ 1342 CP_buildType 0 "UNKNOWN_BUILD" 1 "PLATFORM_BUILD" 2 "LOCAL_BUILD" 3 "TRACEABLE_CI_BUILD" 4 "MFG_BUILD";

VAL_ 20 CP_apsVoltage 0 "CP_APSVOLTAGE_SNA";
VAL_ 20 CP_doorControlState 0 "doorInit" 1 "doorIdle" 2 "doorOpenRequested" 3 "doorOpening" 4 "doorSenseOpen" 5 "doorClosing" 6 "doorSenseClosed";
VAL_ 20 CP_faultLineSensed 0 "CLEARED" 1 "SET";
VAL_ 20 CP_inductiveDoorState 0 "INIT" 1 "INIT_FROM_CHARGE" 2 "INIT_FROM_DRIVE" 3 "PRESENT" 4 "NOT_PRESENT" 5 "OFF_DRIVE" 6 "OFF_CHARGE" 7 "FAULT";
VAL_ 20 CP_inductiveSensorState 0 "INIT" 1 "POLL" 2 "SHUTDOWN" 3 "PAUSE" 4 "WAIT_FOR_INIT" 5 "FAULT" 6 "RESET";
VAL_ 20 CP_latch2ControlState 0 "latchInit" 1 "latchIdle" 2 "latchDisengageRequested" 3 "latchDisengaging" 4 "latchDisengaged" 5 "latchEngaging";
VAL_ 20 CP_latch2State 0 "SNA" 1 "DISENGAGED" 2 "ENGAGED" 3 "BLOCKING";
VAL_ 20 CP_latchControlState 0 "latchInit" 1 "latchIdle" 2 "latchDisengageRequested" 3 "latchDisengaging" 4 "latchDisengaged" 5 "latchEngaging";
VAL_ 20 CP_latchState 0 "SNA" 1 "DISENGAGED" 2 "ENGAGED" 3 "BLOCKING";
VAL_ 20 CP_ledColor 0 "OFF" 1 "RED" 2 "GREEN" 3 "BLUE" 4 "WHITE" 5 "FLASHING_GREEN" 6 "FLASHING_AMBER" 7 "AMBER" 8 "RAVE" 9 "DEBUG" 10 "FLASHING_BLUE";
VAL_ 20 CP_type 0 "US_TESLA" 1 "EURO_IEC" 2 "GB";

VAL_ 1438 CP_componentBranchOrigin 254 "LOCAL_BUILD" 255 "SNA";
VAL_ 1438 CP_componentHardwareRevision 254 "LOCAL_BUILD" 255 "SNA";
VAL_ 1438 CP_componentMajorVersion 254 "LOCAL_BUILD" 255 "SNA";
VAL_ 1438 CP_componentMaturity 254 "LOCAL_BUILD" 255 "SNA";
VAL_ 1438 CP_platformBranchOrigin 254 "LOCAL_BUILD" 255 "SNA";
VAL_ 1438 CP_platformMajorVersion 254 "LOCAL_BUILD" 255 "SNA";
VAL_ 1438 CP_platformMaturity 254 "LOCAL_BUILD" 255 "SNA";
VAL_ 1438 CP_platformTypeVers 254 "LOCAL_BUILD" 255 "SNA";

VAL_ 129 DispBrt_IC 254 "DISP_LGT_ON" 255 "SNA";
VAL_ 129 SwIllLvl 255 "SNA";

VAL_ 583 DAS_alcInternalState 0 "DISABLED" 1 "IDLE" 2 "ABORTING" 3 "BEHAVIOR_CHECK" 4 "PRE_ACTIVE_LEFT" 5 "PRE_ACTIVE_RIGHT" 6 "ACTIVE_LEFT" 7 "ACTIVE_RIGHT" 8 "ACTIVE_ACC_LEFT" 9 "ACTIVE_ACC_RIGHT" 10 "SOFT_ABORTING_LEFT" 11 "SOFT_ABORTING_RIGHT";
VAL_ 583 DAS_autopilotAbortReason 0 "NONE" 1 "WATCHDOG_HEALTH" 2 "DI_MIA" 3 "ESP_MIA" 4 "EPAS_MIA" 5 "GTW_MIA" 6 "SCCM_MIA" 7 "RADAR_MIA" 8 "VCFRONT_MIA" 9 "VCRIGHT_MIA" 10 "CRUISE_FAULT" 11 "CRUISE_NOT_ACTIVE" 12 "USER_DISABLED" 13 "TRAILER_MODE_ACTIVE" 14 "VEHICLE_SPEED_ABOVE_MAX" 15 "EPAS_EAC_NOT_ACTIVE" 16 "EPAS_EAC_ERROR" 17 "CAMERA_FAILSAFES" 18 "CAMERA_CALIBRATION" 19 "RADAR_BLIND" 20 "RADAR_FAULT" 21 "ACC_CANCEL_GENERIC" 22 "ACC_CANCEL_SILENT" 23 "ACC_FAULT" 24 "ROAD_ESTIMATOR_HEALTH" 25 "CONTROLLER_REFERENCE" 26 "CONTROLLER_SOLVER" 27 "CONTROLLER_NOT_ALLOWED" 28 "THERMAL_ISSUE" 29 "MAP_HEALTH" 30 "CONTROLLER_STALE_REFERENCE" 31 "CONTROLLER_STALE_LOCALIZATION" 32 "CONTROLLER_BAD_REF_UPDATE" 33 "AEB" 34 "CONTROLLER_REF_TOO_SHORT" 35 "MISSION_PLANNER_NO_VISION_LANES_FOUND" 36 "GORE_INCURSION" 37 "REACHED_END_OF_NAV_STOP" 38 "STEERING_SATURATED_LANE_DEPARTURE";
VAL_ 583 DAS_behaviorReport 1 "VIEW_RANGE" 2 "CURVE_SPEED_ADAPTATION" 3 "RADAR_ONLY_BRAKING" 4 "KEEP_CALM" 5 "FLEET_SPEEDS" 6 "TRAFFIC_CONTROL_STOPPED_STATE" 7 "UNDERTAKE_ASSIST_KEEP_CALM" 8 "IN_LANE_VEHICLE" 9 "TARGET_LANE_VEHICLE" 10 "UNDERTAKE_VEHICLE" 11 "TRAFFIC_CONTROL" 12 "VISION_LANE_GEOMETRY" 13 "MAP_LANE_GEOMETRY" 14 "DRIVABLE_SPACE_VIOLATION" 15 "SLOWING_FOR_TARGET_LANE" 16 "VISION_SPEEDS" 17 "NAV_FLEET_SPEEDS" 18 "NAV_PATH_CSA" 19 "MERGE_VEHICLE_LEFT" 20 "MERGE_VEHICLE_RIGHT" 21 "CUTIN_VEHICLE_LEFT" 22 "CUTIN_VEHICLE_RIGHT" 23 "MP_AP_RESTRICTION" 24 "MP_NOT_BUCKLED" 25 "MP_DRIVER_MONITOR" 26 "MP_AP_STATE_MACHINE" 27 "MP_DI_CRUISE" 28 "MP_ULC" 29 "MP_AP_INACTIVE";
VAL_ 583 DAS_controllerHealth 0 "HEALTHY" 1 "DEGRADED" 2 "CRITICAL" 3 "SOLVER_FAILURE";
VAL_ 583 DAS_controllerRef 0 "HEALTHY" 1 "UNHEALTHY" 2 "STALE_REFERENCE" 3 "STALE_LOCALIZATION" 4 "BAD_REF_UPDATE" 5 "REF_TOO_SHORT" 6 "INDETERMINATE";
VAL_ 583 DAS_forkState 0 "INVALID" 1 "UNAVAILABLE_DISABLED" 2 "UNAVAILABLE_AP_INACTIVE" 3 "UNAVAILABLE_CONSTRUCTION" 4 "UNAVAILABLE_CONTROLLED_ACCESS_TOO_FAR" 5 "UNAVAILABLE_DON_INACTIVE" 6 "UNAVAILABLE_TOLL_BOOTH" 7 "UNAVAILABLE_OTHER" 8 "IDLE_BOTH_FORKS_AVAILABLE" 9 "IDLE_LEFT_FORK_AVAILABLE" 10 "IDLE_RIGHT_FORK_AVAILABLE" 11 "IDLE_NO_FORKS_AVAILABLE" 12 "ACTIVE_LEFT_NAV" 13 "ACTIVE_LEFT_USER" 14 "ACTIVE_RIGHT_NAV" 15 "ACTIVE_RIGHT_USER" 16 "FORK_COMPLETE" 17 "ABORT_CONTROL_INACTIVE" 18 "ABORT_BLINKER_CHANGE" 19 "ABORT_NOT_LEFT_LANE" 20 "ABORT_NOT_RIGHT_LANE" 21 "ABORT_DISALLOW" 22 "ABORT_OTHER" 23 "UNAVAILABLE_TIGHT_TURN_RADIUS" 24 "UNAVAILABLE_WEATHER";
VAL_ 583 DAS_laneChangeState 0 "UNAVAILABLE_DISABLED" 1 "UNAVAILABLE_ROAD_NOT_APPROPRIATE" 2 "UNAVAILABLE_SPEED" 3 "UNAVAILABLE_NO_LANES" 4 "UNAVAILABLE_INACTIVE" 5 "UNAVAILABLE_FORK_MODE" 6 "UNAVAILABLE_ULTRASONICS_NOT_READY" 7 "UNAVAILABLE_INVALID_MODE" 8 "AVAILABLE_LEFT_ONLY" 9 "AVAILABLE_RIGHT_ONLY" 10 "AVAILABLE_BOTH" 11 "ABORTING_INACTIVE" 12 "ABORTING_BLINKER" 13 "ABORTING_TIMEOUT" 14 "ABORTING_BLIND_SPOT_OCCUPIED" 15 "ABORTING_INVALID_MODE" 16 "ABORTING_LINE_TYPE" 17 "ABORTING_FORK_AVAILABLE" 18 "ABORTING_LOST_VISION_POSE" 19 "ABORTING_ACC_AUTOSTEER_ACTIVATED" 20 "ABORTING_ULC_BLINKER_TIMEOUT" 21 "ABORTING_INVALID_BEHAVIOR" 22 "ABORTING_BELOW_MIN_SPEED" 23 "ABORTING_BEHAVIOR_CHANGED" 24 "ABORTING_HIGH_ALC_PROGRESS_ERROR" 25 "ABORTING_ULC_CONFIRMATION_TIMEOUT" 26 "ABORTING_ALC_REQUEST_BEFORE_ULC_CONFIRM" 27 "IN_PROGRESS_LEFT" 28 "IN_PROGRESS_RIGHT" 29 "BLOCKED_LEFT" 30 "BLOCKED_RIGHT" 31 "ABORTING_GORE_POINT" 32 "ABORTING_CONSTRUCTION_DETECTED" 33 "ABORTING_TOLL_BOOTH_DETECTED" 34 "ABORTING_TIGHT_TURN_RADIUS" 35 "ABORTING_WEATHER" 36 "UNAVAILABLE_BLINDSPOT_RESTRICTED" 37 "ABORTING_NO_HANDS_ON" 38 "UNAVAILABLE_NO_REAR_OBJECT" 39 "ABORTING_SOURCE_AND_TARGET_LANES_MERGED" 63 "UNKNOWN";
VAL_ 583 DAS_lastWatchdogCode 0 "NO_TASK_FAILED" 30 "UNKNOWN_TASK_FAILED" 39 "TELEMETRY_PACKAGER_FAILED" 40 "TELEMETRY_FAILED" 41 "SNAPSHOT_FAILED" 42 "VISION_FAILED" 43 "LEGACY_FAILED" 44 "WATCHDOG_FAILED" 45 "CAN_RX_FAILED" 46 "CAN_TX_FAILED" 47 "TEMPERATURE_MONITOR_FAILED" 48 "INERTIATOR_FAILED" 49 "GPS_FAILED" 50 "ARBITER_FAILED" 51 "AP_STATE_MACHINE_FAILED" 52 "CONTROLLER_FAILED" 53 "LOCALIZER_FAILED" 54 "MISSION_PLANNER_FAILED" 55 "PERCEPTION_FAILED" 56 "ROAD_ESTIMATOR_FAILED" 57 "ATLAS_FAILED" 58 "STAY_IN_LANE_BEHAVIOR_FAILED" 59 "SNAPSHOT_TRIGGER_CLIENT_FAILED" 60 "RAIN_LIGHT_SENSING_FAILED" 61 "IMU_FAILED" 62 "UBX_LOG_FAILED" 63 "LANE_CHANGE_BEHAVIOR_FAILED" 65 "DRIVER_MONITOR_FAILED" 66 "MAP_MANAGER_FAILED" 67 "CAMERA_FAILED" 68 "ACTIVE_SAFETY_FAILED" 69 "UI_SERVER_FAILED" 70 "DYNAMICS_FAILED" 71 "FIELD_CALIBRATION_FAILED" 72 "PARKING_BEHAVIOR_FAILED";
VAL_ 583 DAS_localizerHealth 0 "CRITICAL" 1 "DEGRADED" 2 "RECOVERING" 3 "NO_LANE_LOCALIZED" 4 "SHADOW" 5 "NEAR_LANE_LOCALIZED" 6 "LANE_LOCALIZED" 7 "FINE_LOCALIZED_STICKING" 8 "FINE_LOCALIZED_CONFIRMED";
VAL_ 583 DAS_mapAvailability 0 "NOT_AVAILABLE" 1 "AVAILABLE";
VAL_ 583 DAS_missionPlan 0 "MAP_ONLY" 1 "VISION_ONLY" 2 "MAP_AND_VISION" 3 "INVALID";
VAL_ 583 DAS_roadEstimator 0 "HEALTHY" 1 "UNSTABLE_MEASUREMENTS" 2 "DEGRADED" 3 "CRITICAL";
VAL_ 583 DAS_rqstedBehaviorStatus 0 "VALID" 1 "NO_SRC_POLYLANE" 2 "NO_DEST_POLYLANE" 3 "MAP_NOT_INITIALIZED" 4 "NO_SOURCE_LANE_ON_MAP" 5 "NO_TARGET_LANE_ON_MAP" 6 "BUILD_ARGUMENT_FAIL" 7 "BLOCKED_BY_ULTRASOUND_L" 8 "BLOCKED_BY_BLINDSPOT_CAMERA_L" 9 "BLOCKED_BY_BLINDSPOT_CAMERA_INVALID_L" 10 "BLOCKED_BY_ULTRASOUND_AND_CAMERA_L" 11 "BLOCKED_BY_LANE_TYPE_L" 12 "BLOCKED_BY_ULTRASOUND_R" 13 "BLOCKED_BY_BLINDSPOT_CAMERA_R" 14 "BLOCKED_BY_BLINDSPOT_CAMERA_INVALID_R" 15 "BLOCKED_BY_ULTRASOUND_AND_CAMERA_R" 16 "BLOCKED_BY_LANE_TYPE_R" 17 "ROAD_NOT_APPROPRIATE" 18 "OUT_OF_DATE" 19 "BAD_ORIGIN_UPDATE" 20 "BLOCKED_BY_SLOW_TARGET_L" 21 "BLOCKED_BY_SLOW_TARGET_R" 22 "INVALID_PLAN";

VAL_ 825 DAS_hazardLightRequest 0 "OFF" 1 "ON" 2 "UNUSED" 3 "SNA";
VAL_ 825 DAS_headlightRequest 0 "OFF" 1 "ON" 3 "INVALID";
VAL_ 825 DAS_highLowBeamDecision 0 "UNDECIDED" 1 "OFF" 2 "ON" 3 "SNA";
VAL_ 825 DAS_highLowBeamOffReason 0 "ON" 1 "OFF_REASON_MOVING_VISION_TARGET" 2 "OFF_REASON_MOVING_RADAR_TARGET" 3 "OFF_REASON_AMBIENT_LIGHT" 4 "OFF_REASON_HEAD_LIGHT" 5 "OFF_REASON_SNA";
VAL_ 825 DAS_turnIndicatorRequest 0 "NONE" 1 "LEFT" 2 "RIGHT" 3 "CANCEL";
VAL_ 825 DAS_turnIndicatorRequestReason 0 "NONE" 1 "ACTIVE_NAV_LANE_CHANGE" 2 "ACTIVE_SPEED_LANE_CHANGE" 3 "ACTIVE_FORK" 4 "CANCEL_LANE_CHANGE" 5 "CANCEL_FORK" 6 "ACTIVE_MERGE" 7 "CANCEL_MERGE" 8 "ACTIVE_COMMANDED_LANE_CHANGE";
VAL_ 825 DAS_wiperSpeed 0 "OFF" 1 "1" 2 "2" 3 "3" 4 "4" 5 "5" 6 "6" 7 "7" 8 "8" 9 "9" 10 "10" 11 "11" 12 "12" 13 "13" 14 "14" 15 "INVALID";

VAL_ 697 DAS_accState 0 "ACC_CANCEL_GENERIC" 1 "ACC_CANCEL_CAMERA_BLIND" 2 "ACC_CANCEL_RADAR_BLIND" 3 "ACC_HOLD" 4 "ACC_ON" 5 "APC_BACKWARD" 6 "APC_FORWARD" 7 "APC_COMPLETE" 8 "APC_ABORT" 9 "APC_PAUSE" 10 "APC_UNPARK_COMPLETE" 11 "APC_SELFPARK_START" 12 "ACC_CANCEL_PATH_NOT_CLEAR" 13 "ACC_CANCEL_GENERIC_SILENT" 14 "ACC_CANCEL_OUT_OF_CALIBRATION" 15 "FAULT_SNA";
VAL_ 697 DAS_accelMax 511 "SNA";
VAL_ 697 DAS_accelMin 511 "SNA";
VAL_ 697 DAS_aebEvent 0 "NOT_ACTIVE" 1 "ACTIVE" 2 "FAULT" 3 "SNA";
VAL_ 697 DAS_jerkMax 255 "SNA";
VAL_ 697 DAS_jerkMin 511 "SNA";
VAL_ 697 DAS_setSpeed 4095 "SNA";

VAL_ 1338 DAS_infoIndex 0 "DEPRECATED_0" 1 "DEPRECATED_1" 2 "DEPRECATED_2" 3 "DEPRECATED_3" 4 "DEPRECATED_4" 5 "DEPRECATED_5" 6 "DEPRECATED_6" 7 "DEPRECATED_7" 8 "DEPRECATED_8" 9 "DEPRECATED_9" 10 "BUILD_HWID_COMPONENTID" 11 "PCBAID_ASSYID_USAGEID" 13 "APP_CRC" 14 "BOOTLOADER_SVN" 15 "BOOTLOADER_CRC" 16 "EYEQ_BOOT" 17 "APP_GITHASH" 18 "BOOTLOADER_GITHASH" 19 "VERSION_DEPRECATED" 20 "UDS_PROTOCOL_BOOTCRC" 23 "EYEQ_APP" 24 "EYEQ_FFS" 255 "END";
VAL_ 1338 DAS_infoHardwareRevision 252 "CONFIGURABLE_HWID_PLACEHOLDER";

VAL_ 571 DAS_leftFork 0 "NONE" 1 "AVAILABLE" 2 "SELECTED" 3 "UNAVAILABLE";
VAL_ 571 DAS_leftLineUsage 0 "REJECTED_UNAVAILABLE" 1 "AVAILABLE" 2 "FUSED" 3 "BLACKLISTED";
VAL_ 571 DAS_rightFork 0 "NONE" 1 "AVAILABLE" 2 "SELECTED" 3 "UNAVAILABLE";
VAL_ 571 DAS_rightLineUsage 0 "REJECTED_UNAVAILABLE" 1 "AVAILABLE" 2 "FUSED" 3 "BLACKLISTED";

VAL_ 500 DAS_locAccelMax 511 "SNA";
VAL_ 500 DAS_locAccelMin 511 "SNA";
VAL_ 500 DAS_locJerkMax 255 "SNA";
VAL_ 500 DAS_locJerkMin 255 "SNA";
VAL_ 500 DAS_locMode 0 "OFF" 1 "NORMAL" 2 "RESTRICTED" 3 "DRIVERLESS";
VAL_ 500 DAS_locRequest 0 "IDLE" 1 "FORWARD" 2 "BACKWARD" 3 "HOLD" 4 "PARK";
VAL_ 500 DAS_locSpeed 2047 "SNA";
VAL_ 500 DAS_locState 0 "HEALTHY" 1 "CANCEL_GENERIC" 2 "CANCEL_SILENT" 6 "AEB_ACTIVE" 7 "FAULT_SNA";

VAL_ 1027 DAS_objectId 0 "LEAD_VEHICLES" 1 "LEFT_VEHICLES" 2 "RIGHT_VEHICLES" 3 "CUTIN_VEHICLE" 4 "ROAD_SIGN" 5 "VEHICLE_HEADINGS";
VAL_ 1027 DAS_leadVehType 0 "UNKNOWN" 1 "TRUCK" 2 "CAR" 3 "MOTORCYCLE" 4 "BICYCLE" 5 "PEDESTRIAN" 6 "IPSO";
VAL_ 1027 DAS_leadVehDx 255 "SNA";
VAL_ 1027 DAS_leadVehVxRel 15 "SNA";
VAL_ 1027 DAS_leadVehId 127 "SNA";
VAL_ 1027 DAS_leadVeh2Type 0 "UNKNOWN" 1 "TRUCK" 2 "CAR" 3 "MOTORCYCLE" 4 "BICYCLE" 5 "PEDESTRIAN";
VAL_ 1027 DAS_leadVeh2Dx 255 "SNA";
VAL_ 1027 DAS_leadVeh2VxRel 15 "SNA";
VAL_ 1027 DAS_leadVeh2Id 0 "SNA";
VAL_ 1027 DAS_leftVehType 0 "UNKNOWN" 1 "TRUCK" 2 "CAR" 3 "MOTORCYCLE" 4 "BICYCLE" 5 "PEDESTRIAN";
VAL_ 1027 DAS_leftVehDx 255 "SNA";
VAL_ 1027 DAS_leftVehVxRel 15 "SNA";
VAL_ 1027 DAS_leftVehId 127 "SNA";
VAL_ 1027 DAS_leftVeh2Type 0 "UNKNOWN" 1 "TRUCK" 2 "CAR" 3 "MOTORCYCLE" 4 "BICYCLE" 5 "PEDESTRIAN";
VAL_ 1027 DAS_leftVeh2Dx 255 "SNA";
VAL_ 1027 DAS_leftVeh2VxRel 15 "SNA";
VAL_ 1027 DAS_leftVeh2Id 0 "SNA";
VAL_ 1027 DAS_rightVehType 0 "UNKNOWN" 1 "TRUCK" 2 "CAR" 3 "MOTORCYCLE" 4 "BICYCLE" 5 "PEDESTRIAN";
VAL_ 1027 DAS_rightVehDx 255 "SNA";
VAL_ 1027 DAS_rightVehVxRel 15 "SNA";
VAL_ 1027 DAS_rightVehId 127 "SNA";
VAL_ 1027 DAS_rightVeh2Type 0 "UNKNOWN" 1 "TRUCK" 2 "CAR" 3 "MOTORCYCLE" 4 "BICYCLE" 5 "PEDESTRIAN";
VAL_ 1027 DAS_rightVeh2Dx 255 "SNA";
VAL_ 1027 DAS_rightVeh2VxRel 15 "SNA";
VAL_ 1027 DAS_rightVeh2Id 0 "SNA";
VAL_ 1027 DAS_cutinVehType 0 "UNKNOWN" 1 "TRUCK" 2 "CAR" 3 "MOTORCYCLE" 4 "BICYCLE" 5 "PEDESTRIAN";
VAL_ 1027 DAS_cutinVehDx 255 "SNA";
VAL_ 1027 DAS_cutinVehVxRel 15 "SNA";
VAL_ 1027 DAS_cutinVehId 127 "SNA";
VAL_ 1027 DAS_roadSignColor 0 "NONE" 1 "RED" 2 "YELLOW" 3 "GREEN" 4 "RED_YELLOW";
VAL_ 1027 DAS_roadSignId 0 "STOP_SIGN" 1 "TRAFFIC_LIGHT" 255 "SNA";
VAL_ 1027 DAS_roadSignStopLineDist 1023 "SNA";
VAL_ 1027 DAS_roadSignSource 0 "NONE" 1 "NAV" 2 "VISION";
VAL_ 1027 DAS_roadSignArrow 0 "CIRCLE" 1 "LEFT" 2 "RIGHT" 3 "STRAIGHT" 4 "UNKNOWN";
VAL_ 1027 DAS_roadSignOrientation 0 "UNKNOWN" 1 "VERTICAL_3_LIGHT" 2 "HORIZONTAL_3_LIGHT";
VAL_ 1027 DAS_leadVehHeading 255 "SNA";
VAL_ 1027 DAS_leadVeh2Heading 255 "SNA";
VAL_ 1027 DAS_leftVehHeading 255 "SNA";
VAL_ 1027 DAS_leftVeh2Heading 255 "SNA";
VAL_ 1027 DAS_rightVehHeading 255 "SNA";
VAL_ 1027 DAS_rightVeh2Heading 255 "SNA";
VAL_ 1027 DAS_cutinVehHeading 255 "SNA";

VAL_ 921 DAS_autoLaneChangeState 0 "UNAVAILABLE_DISABLED" 1 "UNAVAILABLE_NO_LANES" 2 "UNAVAILABLE_SONICS_INVALID" 3 "UNAVAILABLE_TP_FOLLOW" 4 "UNAVAILABLE_EXITING_HIGHWAY" 5 "UNAVAILABLE_VEHICLE_SPEED" 6 "AVAILABLE_ONLY_L" 7 "AVAILABLE_ONLY_R" 8 "AVAILABLE_BOTH" 9 "IN_PROGRESS_L" 10 "IN_PROGRESS_R" 11 "WAITING_FOR_SIDE_OBST_TO_PASS_L" 12 "WAITING_FOR_SIDE_OBST_TO_PASS_R" 13 "WAITING_FOR_FWD_OBST_TO_PASS_L" 14 "WAITING_FOR_FWD_OBST_TO_PASS_R" 15 "ABORT_SIDE_OBSTACLE_PRESENT_L" 16 "ABORT_SIDE_OBSTACLE_PRESENT_R" 17 "ABORT_POOR_VIEW_RANGE" 18 "ABORT_LC_HEALTH_BAD" 19 "ABORT_BLINKER_TURNED_OFF" 20 "ABORT_OTHER_REASON" 21 "UNAVAILABLE_SOLID_LANE_LINE" 22 "BLOCKED_VEH_TTC_L" 23 "BLOCKED_VEH_TTC_AND_USS_L" 24 "BLOCKED_VEH_TTC_R" 25 "BLOCKED_VEH_TTC_AND_USS_R" 26 "BLOCKED_LANE_TYPE_L" 27 "BLOCKED_LANE_TYPE_R" 28 "WAITING_HANDS_ON" 29 "ABORT_TIMEOUT" 30 "ABORT_MISSION_PLAN_INVALID" 31 "SNA";
VAL_ 921 DAS_autoparkReady 0 "UNAVAILABLE" 1 "READY";
VAL_ 921 DAS_autopilotHandsOnState 0 "NOT_REQD" 1 "REQD_DETECTED" 2 "REQD_NOT_DETECTED" 3 "REQD_VISUAL" 4 "REQD_CHIME_1" 5 "REQD_CHIME_2" 7 "REQD_STRUCK_OUT" 8 "SUSPENDED" 15 "SNA";
VAL_ 921 DAS_autopilotState 0 "DISABLED" 1 "UNAVAILABLE" 2 "AVAILABLE" 3 "ACTIVE_NOMINAL" 4 "ACTIVE_RESTRICTED" 5 "ACTIVE_NAV" 8 "ABORTING" 9 "ABORTED" 14 "FAULT" 15 "SNA";
VAL_ 921 DAS_blindSpotRearLeft 0 "NO_WARNING" 1 "WARNING_LEVEL_1" 2 "WARNING_LEVEL_2" 3 "SNA";
VAL_ 921 DAS_blindSpotRearRight 0 "NO_WARNING" 1 "WARNING_LEVEL_1" 2 "WARNING_LEVEL_2" 3 "SNA";
VAL_ 921 DAS_csaState 0 "UNAVAILABLE" 1 "AVAILABLE" 2 "ENABLE" 3 "HOLD";
VAL_ 921 DAS_fleetSpeedState 0 "UNAVAILABLE" 1 "AVAILABLE" 2 "ACTIVE" 3 "HOLD";
VAL_ 921 DAS_forwardCollisionWarning 0 "NONE" 1 "FORWARD_COLLISION_WARNING" 3 "SNA";
VAL_ 921 DAS_fusedSpeedLimit 0 "UNKNOWN_SNA" 31 "NONE";
VAL_ 921 DAS_heaterState 0 "OFF_SNA" 1 "ON";
VAL_ 921 DAS_laneDepartureWarning 0 "NONE" 1 "LEFT_WARNING" 2 "RIGHT_WARNING" 3 "LEFT_WARNING_SEVERE" 4 "RIGHT_WARNING_SEVERE" 5 "SNA";
VAL_ 921 DAS_sideCollisionAvoid 0 "NONE" 1 "AVOID_LEFT" 2 "AVOID_RIGHT" 3 "SNA";
VAL_ 921 DAS_sideCollisionInhibit 0 "NO_INHIBIT" 1 "INHIBIT";
VAL_ 921 DAS_sideCollisionWarning 0 "NONE" 1 "WARN_LEFT" 2 "WARN_RIGHT" 3 "WARN_LEFT_RIGHT";
VAL_ 921 DAS_suppressSpeedWarning 0 "Do_Not_Suppress" 1 "Suppress_Speed_Warning";
VAL_ 921 DAS_visionOnlySpeedLimit 0 "UNKNOWN_SNA" 31 "NONE";

VAL_ 905 DAS_ACC_report 0 "TARGET_NONE" 1 "TARGET_CIPV" 2 "TARGET_IN_FRONT_OF_CIPV" 3 "TARGET_MCVL" 4 "TARGET_MCVR" 5 "TARGET_CUTIN" 6 "TARGET_TYPE_STOP_SIGN" 7 "TARGET_TYPE_TRAFFIC_LIGHT" 8 "TARGET_TYPE_IPSO" 9 "TARGET_TYPE_FAULT" 10 "CSA" 11 "LC_HANDS_ON_REQD_STRUCK_OUT" 12 "LC_EXTERNAL_STATE_ABORTING" 13 "LC_EXTERNAL_STATE_ABORTED" 14 "LC_EXTERNAL_STATE_ACTIVE_RESTRICTED" 15 "RADAR_OBJ_ONE" 16 "RADAR_OBJ_TWO" 17 "TARGET_MCP" 18 "FLEET_SPEEDS" 19 "MCVLR_DPP" 20 "MCVLR_IN_PATH" 21 "CIPV_CUTTING_OUT" 22 "RADAR_OBJ_FIVE" 23 "CAMERA_ONLY" 24 "BEHAVIOR_REPORT";
VAL_ 905 DAS_accSpeedLimit 0 "NONE" 1023 "SNA";
VAL_ 905 DAS_activationFailureStatus 0 "IDLE" 1 "FAILED_1" 2 "FAILED_2";
VAL_ 905 DAS_driverInteractionLevel 0 "DRIVER_INTERACTING" 1 "DRIVER_NOT_INTERACTING" 2 "CONTINUED_DRIVER_NOT_INTERACTING";
VAL_ 905 DAS_longCollisionWarning 0 "NONE" 1 "VEHICLE_UNKNOWN" 2 "PEDESTRIAN" 3 "IPSO" 4 "STOPSIGN_STOPLINE" 5 "TFL_STOPLINE" 6 "VEHICLE_CIPV" 7 "VEHICLE_CUTIN" 8 "VEHICLE_MCVL" 9 "VEHICLE_MCVL2" 10 "VEHICLE_MCVR" 11 "VEHICLE_MCVR2" 12 "VEHICLE_CIPV2" 15 "SNA";
VAL_ 905 DAS_lssState 0 "FAULT" 1 "LDW" 2 "LKA" 3 "ELK" 4 "MONITOR" 5 "BLINDSPOT" 6 "ABORT" 7 "OFF";
VAL_ 905 DAS_pmmCameraFaultReason 0 "NO_FAULT" 1 "BLOCKED_FRONT" 2 "INVALID_MIA";
VAL_ 905 DAS_pmmLoggingRequest 0 "FALSE" 1 "TRUE";
VAL_ 905 DAS_pmmObstacleSeverity 0 "NONE" 1 "IMMINENT_REAR" 2 "IMMINENT_FRONT" 3 "BRAKE_REQUEST" 4 "CRASH_REAR" 5 "CRASH_FRONT" 6 "ACCEL_LIMIT" 7 "SNA";
VAL_ 905 DAS_pmmRadarFaultReason 0 "NO_FAULT" 1 "BLOCKED_FRONT" 2 "INVALID_MIA";
VAL_ 905 DAS_pmmSysFaultReason 0 "NONE" 1 "DAS_DISABLED" 2 "SPEED" 3 "DI_FAULT" 4 "STEERING_ANGLE_RATE" 5 "DISABLED_BY_USER" 6 "ROAD_TYPE" 7 "BRAKE_PEDAL_INHIBIT";
VAL_ 905 DAS_pmmUltrasonicsFaultReason 0 "NO_FAULT" 1 "BLOCKED_FRONT" 2 "BLOCKED_REAR" 3 "BLOCKED_BOTH" 4 "INVALID_MIA";
VAL_ 905 DAS_ppOffsetDesiredRamp 128 "PP_NO_OFFSET";
VAL_ 905 DAS_radarTelemetry 0 "IDLE" 1 "NORMAL" 2 "URGENT";
VAL_ 905 DAS_robState 0 "INHIBITED" 1 "MEASURE" 2 "ACTIVE" 3 "MAPLESS";

VAL_ 434 DAS_telemetryMultiplexer 0 "ROAD_INFORMATION" 1 "ACC_DRIVER_MONITOR" 2 "TRAFFIC_SIGNS" 7 "CSA_EVENT" 8 "STATIONARY_OBST" 9 "CRUISE_STALK_INPUT";
VAL_ 434 DAS_telLeftLaneType 0 "UNDECIDED" 1 "SOLID" 2 "ROAD EDGE" 3 "DASHED" 4 "DOUBLE" 5 "BOTTS DOTS" 6 "BARRIER";
VAL_ 434 DAS_telRightLaneType 0 "UNDECIDED" 1 "SOLID" 2 "ROAD EDGE" 3 "DASHED" 4 "DOUBLE" 5 "BOTTS DOTS" 6 "BARRIER";
VAL_ 434 DAS_telLeftMarkerQuality 0 "LOWEST" 1 "LOW" 2 "MEDIUM" 3 "HIGH";
VAL_ 434 DAS_telRightMarkerQuality 0 "LOWEST" 1 "LOW" 2 "MEDIUM" 3 "HIGH";
VAL_ 434 DAS_telLeftMarkerColor 0 "UNKNOWN" 1 "WHITE" 2 "YELLOW" 3 "BLUE";
VAL_ 434 DAS_telRightMarkerColor 0 "UNKNOWN" 1 "WHITE" 2 "YELLOW" 3 "BLUE";
VAL_ 434 DAS_telLeftLaneCrossing 0 "NOT_CROSSING" 1 "CROSSING";
VAL_ 434 DAS_telRightLaneCrossing 0 "NOT_CROSSING" 1 "CROSSING";
VAL_ 434 DAS_stopSignLongitudinalDist 1023 "SNA";
VAL_ 434 DAS_stopSignLateralDist 255 "SNA";
VAL_ 434 DAS_stopSignHeight 63 "SNA";
VAL_ 434 DAS_stopSignStopLineDistance 1023 "SNA";
VAL_ 434 DAS_stopSignCIPVDistance 63 "SNA";
VAL_ 434 DAS_stopSignHostAccel 1023 "SNA";
VAL_ 434 DAS_csaIntState 0 "UNAVAILABLE" 1 "AVAILABLE" 2 "ENABLE_PREDICTED" 3 "ENABLE_ACCELEROMETER" 4 "ENABLE_HOLD";
VAL_ 434 DAS_soCamCipvStatus 0 "INVALID" 1 "UNFUSED" 2 "FUSED_W_OTHER_RAD_OBJ" 3 "FUSED_W_RAD5";
VAL_ 434 DAS_soRad5Status 0 "INVALID" 1 "UNFUSED" 2 "FUSED_W_CIPV" 3 "FUSED_W_OTHER_CAMOBJ";
VAL_ 434 DAS_soRad1Status 0 "INVALID" 1 "UNFUSED" 2 "FUSED_W_CIPV" 3 "FUSED_W_OTHER_CAMOBJ";

VAL_ 985 DAS_TE_multiplexer 0 "START" 1 "LEFT_LANE" 2 "RIGHT_LANE" 3 "HPP" 4 "NAV" 5 "VL" 6 "ACC" 7 "FCM" 8 "IPSO" 9 "END";
VAL_ 985 DAS_TE_eventType 0 "NONE" 1 "DRIVER_INTERVENTION" 2 "AUTOSTEER_ABORT" 3 "ANGLE_SATURATION" 4 "ANGLE_RATE_SATURATION" 5 "LDW_LEFT" 6 "LDW_RIGHT" 7 "ALC_ABORT_LEFT" 8 "ALC_ABORT_RIGHT" 9 "SCA_LEFT" 10 "SCA_RIGHT" 11 "TM_EVENT_IPSO" 12 "TM_EVENT_CRASH" 13 "TM_EVENT_AEB" 14 "TM_EVENT_ROB";
VAL_ 985 DAS_TE_lcAbortReason 0 "HM_LANE_VIEW_RANGE" 1 "HM_VIRTUAL_LANE_NO_INPUTS" 16 "CAM_MSG_MIA" 17 "CAM_WATCHDOG" 18 "TRAILER_MODE" 19 "SIDE_COLLISION_IMMINENT" 20 "EPAS_EAC_DENIED" 21 "COMPONENT_MIA" 22 "CRUISE_FAULT" 23 "CID_SWITCH_DISABLED" 24 "DRIVING_OFF_NAV" 25 "VEHICLE_SPEED_ABOVE_MAX" 26 "FOLLOWER_OUTPUT_INVALID" 27 "PLANNER_OUTPUT_INVALID" 28 "EPAS_ERROR_CODE" 29 "ACC_CANCEL" 30 "CAMERA_FAILSAFES" 31 "NO_ABORT";

VAL_ 945 DAS_TF_multiplexer 0 "ENVIRONMENT_DATA" 1 "FURNITURE_DATA" 2 "TFL_DATA";
VAL_ 945 DAS_TF_llType 0 "UNDECIDED" 1 "SOLID" 2 "ROAD_EDGE" 3 "DASHED" 4 "DOUBLE_LANE" 5 "BOTTS_DOTS" 6 "BARRIER" 7 "INVALID";
VAL_ 945 DAS_TF_rlType 0 "UNDECIDED" 1 "SOLID" 2 "ROAD_EDGE" 3 "DASHED" 4 "DOUBLE_LANE" 5 "BOTTS_DOTS" 6 "BARRIER" 7 "INVALID";
VAL_ 945 DAS_TF_cipvDist 511 "SNA";
VAL_ 945 DAS_TF_transmissionStatus 0 "INITIAL" 1 "INTERMEDIATE" 2 "FINAL";

VAL_ 889 DAS_TP_multiplexer 0 "START" 1 "LEFT_LANE" 2 "RIGHT_LANE" 3 "HPP" 4 "NAV" 5 "VIRTUAL_LANE" 6 "LEFT_BOTTS_DOTS" 7 "RIGHT_BOTTS_DOTS" 8 "LANE_INFO" 9 "END";
VAL_ 889 DAS_TP_laneChange 0 "NONE" 1 "LEFT" 2 "RIGHT";
VAL_ 889 DAS_TP_llType 0 "UNDECIDED" 1 "SOLID" 2 "ROAD_EDGE" 3 "DASHED" 4 "DOUBLE_LANE" 5 "BOTTS_DOTS" 6 "BARRIER" 7 "INVALID";
VAL_ 889 DAS_TP_rlType 0 "UNDECIDED" 1 "SOLID" 2 "ROAD_EDGE" 3 "DASHED" 4 "DOUBLE_LANE" 5 "BOTTS_DOTS" 6 "BARRIER" 7 "INVALID";
VAL_ 889 DAS_TP_plannerState 0 "DISABLED" 1 "VIRTUAL_LANE" 2 "FOLLOW" 3 "LANECHANGE_REQUESTED" 4 "LANECHANGE_IN_PROGRESS" 5 "LANECHANGE_WAIT_FOR_SIDE_OBSTACLE" 6 "LANECHANGE_WAIT_FOR_FWD_OBSTACLE" 7 "LANECHANGE_ABORT";
VAL_ 889 DAS_TP_lcState 0 "DISABLED" 1 "UNAVAILABLE" 2 "AVAILABLE" 3 "ACTIVE_NOMINAL" 4 "ACTIVE_RESTRICTED" 8 "ABORTING" 9 "ABORTED" 14 "FAULT" 15 "SNA";
VAL_ 889 DAS_TP_llQltyME 0 "LOWEST" 1 "LOW" 2 "MEDIUM" 3 "HIGH";
VAL_ 889 DAS_TP_rlQltyME 0 "LOWEST" 1 "LOW" 2 "MEDIUM" 3 "HIGH";
VAL_ 889 DAS_TP_bdlQltyME 0 "LOWEST" 1 "LOW" 2 "MEDIUM" 3 "HIGH";
VAL_ 889 DAS_TP_bdrQltyME 0 "LOWEST" 1 "LOW" 2 "MEDIUM" 3 "HIGH";
